VERSION "HNNBNNNYNNNNNNNNNNNNNNNNNNNNNNNNNNNNNNNNNN/4/%%%/4/'%**4NNN///"

NS_ :

BS_:

BU_: AWC BAP_Tester BMC_MLBevo BMS_MV BMS_NV CBC DCDC_800V_PAG DCDC_HV DCDC_HV_02 DCDC_IHEV FCU_MLBevo_FCEV Gateway Gateway_PAG Ladegeraet_2 Ladegeraet_Konzern LE1 LE2 LE_MLBevo Sub_Gateway TME

BO_ 64 Airbag_01: 8 Gateway
 SG_ Airbag_01_CRC : 0|8@1+ (1,0) [0|255] ""  BMC_MLBevo,BMS_MV,BMS_NV,CBC,DCDC_800V_PAG,DCDC_HV,DCDC_HV_02,DCDC_IHEV,FCU_MLBevo_FCEV,Ladegeraet_2,Ladegeraet_Konzern,Sub_Gateway
 SG_ Airbag_01_BZ : 8|4@1+ (1,0) [0|15] ""  BMC_MLBevo,BMS_MV,BMS_NV,CBC,DCDC_800V_PAG,DCDC_HV,DCDC_HV_02,DCDC_IHEV,FCU_MLBevo_FCEV,Ladegeraet_2,Ladegeraet_Konzern,Sub_Gateway
 SG_ AB_RGS_Anst : 12|4@1+ (1.0,0.0) [0.0|15] ""  FCU_MLBevo_FCEV,Sub_Gateway
 SG_ AB_Front_Crash : 16|1@1+ (1.0,0.0) [0.0|1] ""  FCU_MLBevo_FCEV,Sub_Gateway
 SG_ AB_Heck_Crash : 17|1@1+ (1.0,0.0) [0.0|1] ""  FCU_MLBevo_FCEV,Sub_Gateway
 SG_ AB_SF_Crash : 18|1@1+ (1.0,0.0) [0.0|1] ""  FCU_MLBevo_FCEV,Sub_Gateway
 SG_ AB_SB_Crash : 19|1@1+ (1.0,0.0) [0.0|1] ""  FCU_MLBevo_FCEV,Sub_Gateway
 SG_ AB_Rollover_Crash : 20|1@1+ (1.0,0.0) [0.0|1] ""  FCU_MLBevo_FCEV,Sub_Gateway
 SG_ AB_Crash_Int : 21|3@1+ (1.0,0.0) [0.0|7] ""  FCU_MLBevo_FCEV,Sub_Gateway,TME
 SG_ AB_Lampe : 24|1@1+ (1.0,0.0) [0.0|1] ""  FCU_MLBevo_FCEV,Sub_Gateway
 SG_ AB_Deaktiviert : 25|1@1+ (1.0,0.0) [0.0|1] ""  FCU_MLBevo_FCEV,Sub_Gateway
 SG_ AB_VB_deaktiviert : 26|1@1+ (1.0,0.0) [0.0|1] ""  FCU_MLBevo_FCEV,Sub_Gateway
 SG_ AB_Systemfehler : 27|1@1+ (1.0,0.0) [0.0|1] ""  FCU_MLBevo_FCEV,Sub_Gateway
 SG_ AB_Diagnose : 28|1@1+ (1.0,0.0) [0.0|1] ""  FCU_MLBevo_FCEV,Sub_Gateway
 SG_ AB_Stellgliedtest : 29|1@1+ (1.0,0.0) [0.0|1] ""  FCU_MLBevo_FCEV,Sub_Gateway,TME
 SG_ AB_Erh_Auf_VB : 30|2@1+ (1.0,0.0) [0.0|3] ""  FCU_MLBevo_FCEV,Sub_Gateway
 SG_ AB_Gurtwarn_VF : 32|1@1+ (1.0,0.0) [0.0|1] ""  FCU_MLBevo_FCEV,Sub_Gateway
 SG_ AB_Gurtwarn_VB : 33|1@1+ (1.0,0.0) [0.0|1] ""  FCU_MLBevo_FCEV,Sub_Gateway
 SG_ AB_Anzeige_Fussg : 34|2@1+ (1.0,0.0) [0.0|3] ""  FCU_MLBevo_FCEV,Sub_Gateway
 SG_ AB_Texte_AKS : 36|2@1+ (1.0,0.0) [0.0|3] ""  FCU_MLBevo_FCEV,Sub_Gateway
 SG_ AB_MKB_gueltig : 39|1@1+ (1.0,0.0) [0.0|1] ""  FCU_MLBevo_FCEV,Sub_Gateway
 SG_ AB_MKB_Anforderung : 40|1@1+ (1.0,0.0) [0.0|1] ""  FCU_MLBevo_FCEV,Sub_Gateway
 SG_ AB_Versorgungsspannung : 41|1@1+ (1.0,0.0) [0.0|1] ""  FCU_MLBevo_FCEV,Sub_Gateway
 SG_ AB_Deaktivierung_HV : 42|3@1+ (1.0,0.0) [0.0|7] ""  BMC_MLBevo,BMS_MV,BMS_NV,CBC,DCDC_800V_PAG,DCDC_HV,DCDC_HV_02,DCDC_IHEV,FCU_MLBevo_FCEV,Ladegeraet_2,Ladegeraet_Konzern,Sub_Gateway,TME
 SG_ AB_EDR_Trigger : 45|2@1+ (1.0,0.0) [0.0|3] ""  FCU_MLBevo_FCEV,Sub_Gateway
 SG_ AB_Belegung_VF : 47|2@1+ (1.0,0.0) [0.0|3] ""  FCU_MLBevo_FCEV,Sub_Gateway
 SG_ SC_Masterzeit_Offset : 53|2@1+ (5.08,0) [0.00|15.24] "Unit_Secon"  FCU_MLBevo_FCEV,Sub_Gateway
 SG_ SC_LowSpeedCrashErkannt : 55|2@1+ (1.0,0.0) [0.0|3] ""  FCU_MLBevo_FCEV,Sub_Gateway
 SG_ SC_Masterzeit : 57|7@1+ (0.04,0) [0.00|5.04] "Unit_Secon"  FCU_MLBevo_FCEV,Sub_Gateway

BO_ 2589283757 Authentic_Time_01: 8 Gateway
 SG_ AT_VALID_TIME : 32|32@1+ (1,0) [1|4294967295] ""  Ladegeraet_Konzern

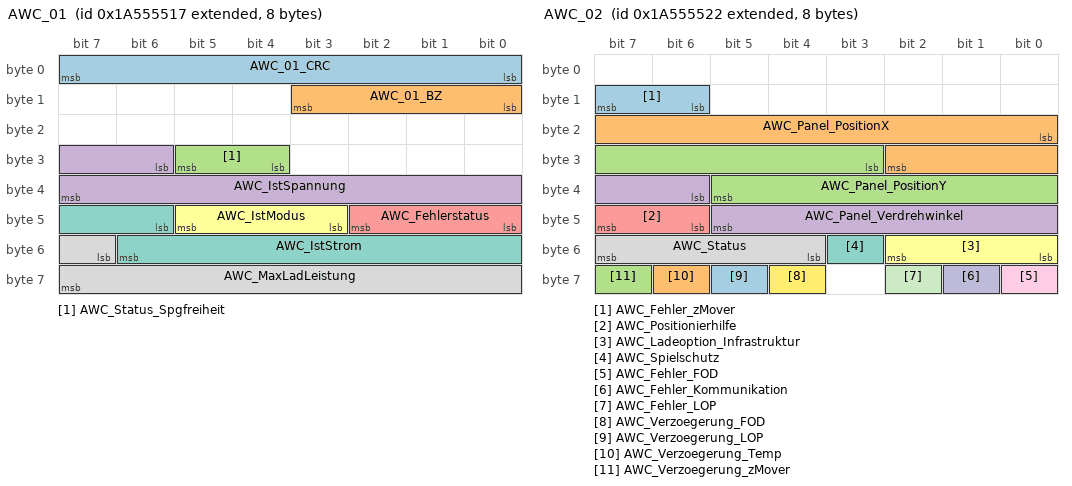
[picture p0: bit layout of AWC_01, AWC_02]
BO_ 2589283607 AWC_01: 8 AWC
 SG_ AWC_01_CRC : 0|8@1+ (1,0) [0|255] ""  Gateway
 SG_ AWC_01_BZ : 8|4@1+ (1,0) [0|15] ""  Gateway
 SG_ AWC_Status_Spgfreiheit : 28|2@1+ (1.0,0.0) [0.0|3] ""  Gateway
 SG_ AWC_IstSpannung : 30|10@1+ (1,0) [0|1021] "Unit_Volt"  Gateway
 SG_ AWC_Fehlerstatus : 40|3@1+ (1.0,0.0) [0.0|7] ""  Gateway
 SG_ AWC_IstModus : 43|3@1+ (1.0,0.0) [0.0|7] ""  Vector__XXX
 SG_ AWC_IstStrom : 46|9@1+ (0.1,0) [0.0|50.9] "Unit_Amper"  Vector__XXX
 SG_ AWC_MaxLadLeistung : 55|9@1+ (25,0) [0|12725] "Unit_Watt"  Vector__XXX

BO_ 2589283618 AWC_02: 8 AWC
 SG_ AWC_Fehler_zMover : 14|2@1+ (1.0,0.0) [0.0|3] ""  Gateway,Gateway_PAG
 SG_ AWC_Panel_PositionX : 16|11@1+ (1,-1000) [-1000|1000] "Unit_Centimeter"  Gateway,Gateway_PAG
 SG_ AWC_Panel_PositionY : 27|11@1+ (1,-1000) [-1000|1000] "Unit_Centimeter"  Gateway,Gateway_PAG
 SG_ AWC_Panel_Verdrehwinkel : 38|8@1+ (1.5,0) [0.0|360.0] "Unit_DegreOfArc"  Gateway,Gateway_PAG
 SG_ AWC_Positionierhilfe : 46|2@1+ (1.0,0.0) [0.0|3] ""  Gateway,Gateway_PAG
 SG_ AWC_Ladeoption_Infrastruktur : 48|3@1+ (1.0,0.0) [0.0|7] ""  Gateway,Gateway_PAG
 SG_ AWC_Spielschutz : 51|1@1+ (1.0,0.0) [0.0|1] ""  Gateway,Gateway_PAG
 SG_ AWC_Status : 52|4@1+ (1.0,0.0) [0.0|15] ""  Gateway,Gateway_PAG
 SG_ AWC_Fehler_FOD : 56|1@1+ (1.0,0.0) [0.0|1] ""  Gateway,Gateway_PAG
 SG_ AWC_Fehler_Kommunikation : 57|1@1+ (1.0,0.0) [0.0|1] ""  Gateway,Gateway_PAG
 SG_ AWC_Fehler_LOP : 58|1@1+ (1.0,0.0) [0.0|1] ""  Gateway,Gateway_PAG
 SG_ AWC_Verzoegerung_FOD : 60|1@1+ (1.0,0.0) [0.0|1] ""  Gateway,Gateway_PAG
 SG_ AWC_Verzoegerung_LOP : 61|1@1+ (1.0,0.0) [0.0|1] ""  Gateway,Gateway_PAG
 SG_ AWC_Verzoegerung_Temp : 62|1@1+ (1.0,0.0) [0.0|1] ""  Gateway,Gateway_PAG
 SG_ AWC_Verzoegerung_zMover : 63|1@1+ (1.0,0.0) [0.0|1] ""  Gateway,Gateway_PAG

BO_ 2536720384 BAP_AWC_ASG_01: 8 Gateway
 SG_ BAP_AWC_ASG_01_Header : 0|8@1+ (1,0) [0|255] "Unit_None"  Vector__XXX

BO_ 2536720385 BAP_AWC_ASG_02: 8 Gateway
 SG_ BAP_AWC_ASG_02_Header : 0|64@1+ (1.0,0.0) [0.0|18446744073709551615] ""  Vector__XXX

BO_ 2536720400 BAP_AWC_FSG_01: 8 AWC
 SG_ BAP_AWC_FSG_01_Header : 0|8@1+ (1,0) [0|255] "Unit_None"  Gateway,Gateway_PAG

BO_ 2536711424 BAP_BatteryControl_ASG_01: 8 Gateway
 SG_ BAP_BatteryControl_ASG_01_Header : 0|8@1+ (1.0,0.0) [0.0|255] ""  Ladegeraet_Konzern

BO_ 2536711425 BAP_BatteryControl_ASG_02: 8 Gateway
 SG_ BAP_BatteryControl_ASG_02_Header : 0|8@1+ (1.0,0.0) [0.0|255] ""  Ladegeraet_Konzern

BO_ 2536711426 BAP_BatteryControl_ASG_03: 8 Gateway
 SG_ BAP_BatteryControl_ASG_03_Header : 0|8@1+ (1.0,0.0) [0.0|255] ""  Ladegeraet_Konzern

BO_ 2536711427 BAP_BatteryControl_ASG_04: 8 Gateway
 SG_ BAP_BatteryControl_ASG_04_Header : 0|8@1+ (1.0,0.0) [0.0|255] ""  Ladegeraet_Konzern

BO_ 2536711429 BAP_BatteryControl_ASG_06: 8 Gateway
 SG_ BAP_BatteryControl_ASG_06_Header : 0|8@1+ (1.0,0.0) [0.0|255] ""  Ladegeraet_Konzern

BO_ 2536711440 BAP_BatteryControl_FSG_01: 8 Ladegeraet_Konzern
 SG_ BAP_BatteryControl_FSG_01_Header : 0|8@1+ (1.0,0.0) [0.0|255] ""  Gateway,Gateway_PAG

BO_ 2536767264 BAP_Debug_Cmd: 8 BAP_Tester
 SG_ BAP_Debug_Cmd : 0|16@1+ (1.0,0.0) [0.0|65535] ""  Gateway,Gateway_PAG,Ladegeraet_Konzern

BO_ 2536767280 BAP_Debug_Data: 8 Gateway
 SG_ BAP_Debug_Data : 0|64@1+ (1.0,0.0) [0.0|18446744073709551615] ""  BAP_Tester

BO_ 2536706306 BAP_Uhrzeit_ASG_03: 8 Ladegeraet_Konzern
 SG_ BAP_Uhrzeit_ASG_03_Header : 0|8@1+ (1.0,0.0) [0.0|255] ""  Gateway,Gateway_PAG

BO_ 2536706310 BAP_Uhrzeit_ASG_07: 8 AWC
 SG_ BAP_Uhrzeit_ASG_07_Header : 0|64@1+ (1.0,0.0) [0.0|18446744073709551615] ""  Gateway,Gateway_PAG

BO_ 2536706320 BAP_Uhrzeit_FSG_01: 8 Gateway
 SG_ BAP_Uhrzeit_FSG_01_Header : 0|8@1+ (1.0,0.0) [0.0|255] ""  Ladegeraet_Konzern

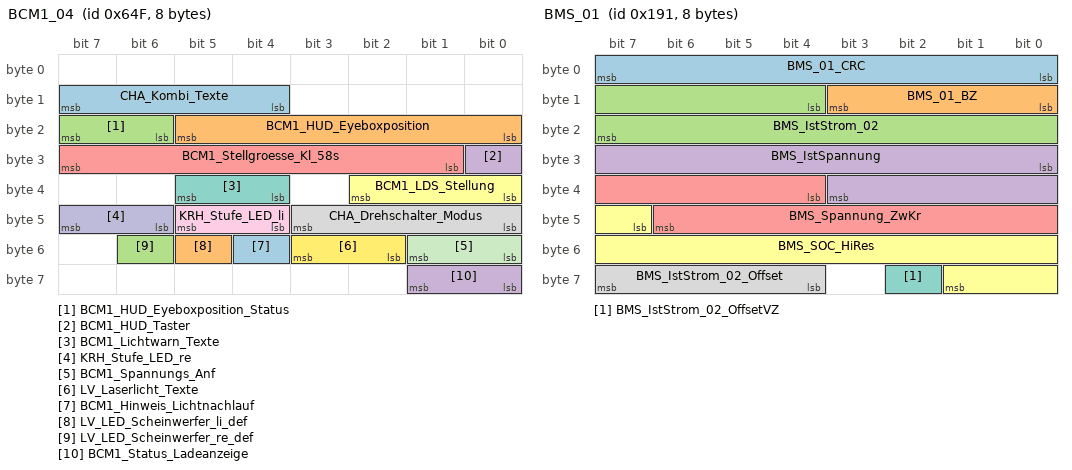
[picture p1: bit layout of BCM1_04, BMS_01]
BO_ 1615 BCM1_04: 8 Gateway
 SG_ CHA_Kombi_Texte : 12|4@1+ (1.0,0.0) [0.0|15] ""  Vector__XXX
 SG_ BCM1_HUD_Eyeboxposition : 16|6@1+ (1,0) [0|63] ""  Vector__XXX
 SG_ BCM1_HUD_Eyeboxposition_Status : 22|2@1+ (1.0,0.0) [0.0|3] ""  Vector__XXX
 SG_ BCM1_HUD_Taster : 24|1@1+ (1.0,0.0) [0.0|1] ""  Vector__XXX
 SG_ BCM1_Stellgroesse_Kl_58s : 25|7@1+ (1,0) [0|100] ""  Vector__XXX
 SG_ BCM1_LDS_Stellung : 32|3@1+ (1.0,0.0) [0.0|7] ""  Vector__XXX
 SG_ BCM1_Lichtwarn_Texte : 36|2@1+ (1.0,0.0) [0.0|3] ""  Vector__XXX
 SG_ CHA_Drehschalter_Modus : 40|4@1+ (1.0,0.0) [0.0|15] ""  Vector__XXX
 SG_ KRH_Stufe_LED_li : 44|2@1+ (1.0,0.0) [0.0|3] ""  Vector__XXX
 SG_ KRH_Stufe_LED_re : 46|2@1+ (1.0,0.0) [0.0|3] ""  Vector__XXX
 SG_ BCM1_Spannungs_Anf : 48|2@1+ (1.0,0.0) [0.0|3] ""  Vector__XXX
 SG_ LV_Laserlicht_Texte : 50|2@1+ (1.0,0.0) [0.0|3] ""  Vector__XXX
 SG_ BCM1_Hinweis_Lichtnachlauf : 52|1@1+ (1.0,0.0) [0.0|1] ""  Vector__XXX
 SG_ LV_LED_Scheinwerfer_li_def : 53|1@1+ (1.0,0.0) [0.0|1] ""  Vector__XXX
 SG_ LV_LED_Scheinwerfer_re_def : 54|1@1+ (1.0,0.0) [0.0|1] ""  Vector__XXX
 SG_ BCM1_Status_Ladeanzeige : 56|2@1+ (1.0,0.0) [0.0|3] ""  Ladegeraet_Konzern

BO_ 1626 BCM_01: 8 Gateway
 SG_ BCM_Bremsbelag_Sensor : 12|1@1+ (1.0,0.0) [0.0|1] ""  Vector__XXX
 SG_ BCM_Bremsfluessigkeit_Sensor : 13|1@1+ (1.0,0.0) [0.0|1] ""  Vector__XXX
 SG_ BCM1_Licht_Warn : 14|1@1+ (1.0,0.0) [0.0|1] ""  Vector__XXX
 SG_ BCM_Waschwasser_Sensor : 15|1@1+ (1.0,0.0) [0.0|1] ""  Vector__XXX
 SG_ BCM_Kuehlmittel_Sensor : 16|1@1+ (1.0,0.0) [0.0|1] ""  TME
 SG_ BCM1_Kl_15_HW_erkannt : 17|1@1+ (1.0,0.0) [0.0|1] ""  Vector__XXX
 SG_ BCM1_Kl_15_Sig_HW_erkannt : 18|1@1+ (1.0,0.0) [0.0|1] ""  Vector__XXX
 SG_ BCM_Kuehlmittel_Sensor_02 : 19|1@1+ (1.0,0.0) [0.0|1] ""  TME
 SG_ BCM1_Hinweis_Lichtnachlauf : 20|1@1+ (1.0,0.0) [0.0|1] ""  Vector__XXX
 SG_ BCM_Offroad_Taste : 21|1@1+ (1.0,0.0) [0.0|1] ""  Vector__XXX
 SG_ BCM_Hybrid_StSt_Taste_Fehler : 23|1@1+ (1.0,0.0) [0.0|1] ""  Vector__XXX
 SG_ BCM_Hybrid_StartStopp_Taste : 24|1@1+ (1.0,0.0) [0.0|1] ""  Vector__XXX
 SG_ BCM1_Warnblink_Taster : 25|1@1+ (1.0,0.0) [0.0|1] ""  Vector__XXX
 SG_ BCM1_Valet_Parking_Taster : 26|1@1+ (1.0,0.0) [0.0|1] ""  Vector__XXX
 SG_ BCM1_LDS_Stellung : 27|3@1+ (1.0,0.0) [0.0|7] ""  Vector__XXX
 SG_ BCM1_Rueckfahrlicht_Schalter : 30|1@1+ (1.0,0.0) [0.0|1] ""  Vector__XXX
 SG_ BCM1_MH_Schalter : 31|1@1+ (1.0,0.0) [0.0|1] ""  Vector__XXX
 SG_ BCM1_MH_WIV_Schalter : 32|1@1+ (1.0,0.0) [0.0|1] ""  Vector__XXX
 SG_ BCM_Eco_Charisma_Taste : 33|1@1+ (1.0,0.0) [0.0|1] ""  Vector__XXX
 SG_ BCM1_NV_Taster : 34|1@1+ (1.0,0.0) [0.0|1] ""  Vector__XXX
 SG_ BCM1_AFS_Lampe : 35|1@1+ (1.0,0.0) [0.0|1] ""  Vector__XXX
 SG_ BCM1_Reisemodus_Texte : 36|2@1+ (1.0,0.0) [0.0|3] ""  Vector__XXX
 SG_ BCM1_Lichtwarn_Texte : 38|2@1+ (1.0,0.0) [0.0|3] ""  Vector__XXX
 SG_ Gong_TFL_Umschaltung : 40|1@1+ (1.0,0.0) [0.0|1] ""  Vector__XXX
 SG_ UGDO_Function_01 : 41|3@1+ (1.0,0.0) [0.0|7] ""  Vector__XXX
 SG_ APS_Tongeber_defekt : 44|1@1+ (1.0,0.0) [0.0|1] ""  Vector__XXX
 SG_ BCM1_EasyEntry_Status : 45|1@1+ (1.0,0.0) [0.0|1] ""  Vector__XXX
 SG_ BCM1_Lenksaeule_aktiv : 46|1@1+ (1.0,0.0) [0.0|1] ""  Vector__XXX
 SG_ BCM1_St_SW_Diebstahl_links : 47|1@1+ (1.0,0.0) [0.0|1] ""  Vector__XXX
 SG_ BCM1_St_SW_Diebstahl_rechts : 48|1@1+ (1.0,0.0) [0.0|1] ""  Vector__XXX
 SG_ ISP_Dimmung_ASP_02 : 49|6@1+ (0.0226,0) [0.0000|1.4012] "Unit_Volt"  Vector__XXX
 SG_ BCM1_Schluesselsuche_Anf : 55|1@1+ (1.0,0.0) [0.0|1] ""  Vector__XXX
 SG_ BCM1_Fahrlicht_Hinweis : 62|1@1+ (1.0,0.0) [0.0|1] ""  Vector__XXX
 SG_ BCM_HDF_betaetigt : 63|1@1+ (1.0,0.0) [0.0|1] ""  Vector__XXX

BO_ 401 BMS_01: 8 BMC_MLBevo
 SG_ BMS_01_CRC : 0|8@1+ (1,0) [0|255] ""  Gateway,Gateway_PAG,LE1,Sub_Gateway
 SG_ BMS_01_BZ : 8|4@1+ (1,0) [0|15] ""  Gateway,Gateway_PAG,LE1,Sub_Gateway
 SG_ BMS_IstStrom_02 : 12|12@1+ (1,-2047) [-2047|2046] "Unit_Amper"  Gateway,Gateway_PAG,Ladegeraet_Konzern,LE1,LE2,Sub_Gateway,TME
 SG_ BMS_IstSpannung : 24|12@1+ (0.25,0) [0.00|1023.25] "Unit_Volt"  DCDC_HV,Gateway,Gateway_PAG,Ladegeraet_2,Ladegeraet_Konzern,LE1,LE2,Sub_Gateway,TME
 SG_ BMS_Spannung_ZwKr : 36|11@1+ (0.5,0) [0.0|1022.5] "Unit_Volt"  Gateway,Gateway_PAG,LE1,LE2,Sub_Gateway,TME
 SG_ BMS_SOC_HiRes : 47|11@1+ (0.05,0) [0.00|100.00] "Unit_PerCent"  Gateway,Gateway_PAG,Ladegeraet_Konzern,Sub_Gateway,TME
 SG_ BMS_IstStrom_02_OffsetVZ : 58|1@1+ (1.0,0.0) [0.0|1] ""  Gateway,Gateway_PAG,Ladegeraet_Konzern,Sub_Gateway
 SG_ BMS_IstStrom_02_Offset : 60|4@1+ (0.0625,0) [0.0000|0.9375] "Unit_Amper"  Gateway,Gateway_PAG,Ladegeraet_Konzern,Sub_Gateway

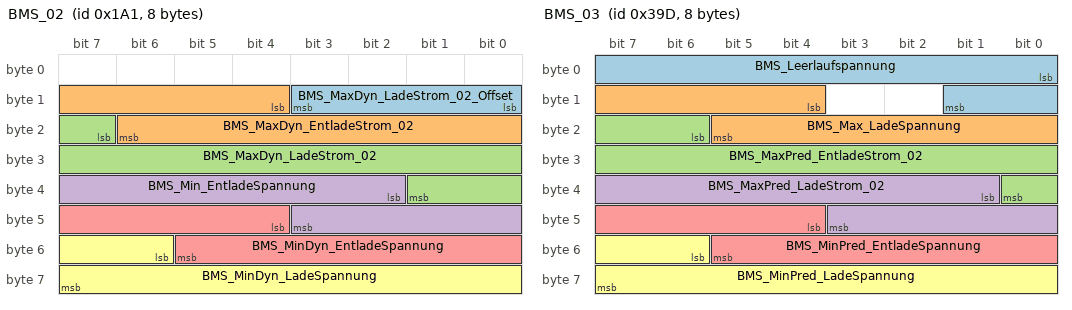
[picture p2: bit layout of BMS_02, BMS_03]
BO_ 417 BMS_02: 8 BMC_MLBevo
 SG_ BMS_MaxDyn_LadeStrom_02_Offset : 8|4@1+ (0.0625,0) [0.0000|0.9375] "Unit_Amper"  FCU_MLBevo_FCEV,Gateway,Gateway_PAG,Ladegeraet_Konzern
 SG_ BMS_MaxDyn_EntladeStrom_02 : 12|11@1+ (1,0) [0|2045] "Unit_Amper"  FCU_MLBevo_FCEV,Gateway,Gateway_PAG
 SG_ BMS_MaxDyn_LadeStrom_02 : 23|11@1+ (1,0) [0|2045] "Unit_Amper"  FCU_MLBevo_FCEV,Gateway,Gateway_PAG,Ladegeraet_Konzern
 SG_ BMS_Min_EntladeSpannung : 34|10@1+ (1,0) [0|1021] "Unit_Volt"  FCU_MLBevo_FCEV,Gateway,Gateway_PAG,Ladegeraet_Konzern
 SG_ BMS_MinDyn_EntladeSpannung : 44|10@1+ (1,0) [0|1022] "Unit_Volt"  FCU_MLBevo_FCEV,Gateway,Gateway_PAG
 SG_ BMS_MinDyn_LadeSpannung : 54|10@1+ (1,0) [0|1022] "Unit_Volt"  FCU_MLBevo_FCEV,Gateway,Gateway_PAG

BO_ 925 BMS_03: 8 BMC_MLBevo
 SG_ BMS_Leerlaufspannung : 0|10@1+ (1,0) [0|1022] "Unit_Volt"  FCU_MLBevo_FCEV,Gateway,Gateway_PAG
 SG_ BMS_Max_LadeSpannung : 12|10@1+ (1,0) [0|1021] "Unit_Volt"  FCU_MLBevo_FCEV,Gateway,Gateway_PAG,Ladegeraet_2,Ladegeraet_Konzern
 SG_ BMS_MaxPred_EntladeStrom_02 : 22|11@1+ (1,0) [0|2045] "Unit_Amper"  FCU_MLBevo_FCEV,Gateway,Gateway_PAG
 SG_ BMS_MaxPred_LadeStrom_02 : 33|11@1+ (1,0) [0|2045] "Unit_Amper"  FCU_MLBevo_FCEV,Gateway,Gateway_PAG,Ladegeraet_Konzern
 SG_ BMS_MinPred_EntladeSpannung : 44|10@1+ (1,0) [0|1022] "Unit_Volt"  FCU_MLBevo_FCEV,Gateway,Gateway_PAG,Ladegeraet_Konzern
 SG_ BMS_MinPred_LadeSpannung : 54|10@1+ (1,0) [0|1022] "Unit_Volt"  FCU_MLBevo_FCEV,Gateway,Gateway_PAG

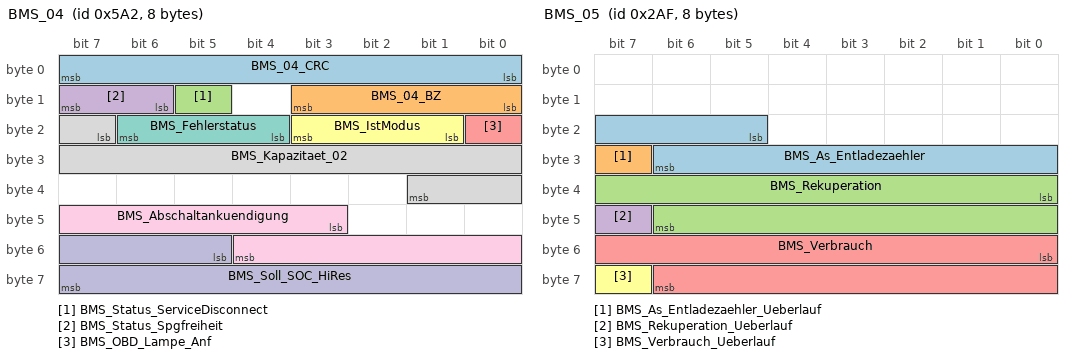
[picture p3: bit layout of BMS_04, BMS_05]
BO_ 1442 BMS_04: 8 BMC_MLBevo
 SG_ BMS_04_CRC : 0|8@1+ (1,0) [0|255] ""  CBC,FCU_MLBevo_FCEV,Gateway,Gateway_PAG,LE1,Sub_Gateway
 SG_ BMS_04_BZ : 8|4@1+ (1,0) [0|15] ""  CBC,FCU_MLBevo_FCEV,Gateway,Gateway_PAG,LE1,Sub_Gateway
 SG_ BMS_Status_ServiceDisconnect : 13|1@1+ (1.0,0.0) [0.0|1] ""  CBC,DCDC_800V_PAG,DCDC_HV,FCU_MLBevo_FCEV,Gateway,Gateway_PAG,Sub_Gateway
 SG_ BMS_Status_Spgfreiheit : 14|2@1+ (1.0,0.0) [0.0|3] ""  FCU_MLBevo_FCEV,Gateway,Gateway_PAG,Sub_Gateway
 SG_ BMS_OBD_Lampe_Anf : 16|1@1+ (1.0,0.0) [0.0|1] ""  FCU_MLBevo_FCEV,Gateway,Gateway_PAG,Sub_Gateway
 SG_ BMS_IstModus : 17|3@1+ (1.0,0.0) [0.0|7] ""  DCDC_HV,FCU_MLBevo_FCEV,Gateway,Gateway_PAG,Ladegeraet_Konzern,LE1,LE2,Sub_Gateway,TME
 SG_ BMS_Fehlerstatus : 20|3@1+ (1.0,0.0) [0.0|7] ""  CBC,DCDC_800V_PAG,DCDC_HV,FCU_MLBevo_FCEV,Gateway,Gateway_PAG,Ladegeraet_Konzern,Sub_Gateway
 SG_ BMS_Kapazitaet_02 : 23|11@1+ (0.2,0) [0.0|409.2] "Unit_AmperHour"  FCU_MLBevo_FCEV,Gateway,Gateway_PAG,Ladegeraet_Konzern,Sub_Gateway
 SG_ BMS_Abschaltankuendigung : 43|10@1+ (0.5,0) [0.0|510.5] "Unit_Secon"  FCU_MLBevo_FCEV,Gateway,Gateway_PAG,Sub_Gateway
 SG_ BMS_Soll_SOC_HiRes : 53|11@1+ (0.05,0) [0.00|100.00] "Unit_PerCent"  FCU_MLBevo_FCEV,Gateway,Gateway_PAG,Sub_Gateway

BO_ 687 BMS_05: 8 BMC_MLBevo
 SG_ BMS_As_Entladezaehler : 21|10@1+ (1,0) [0|1023] "Unit_AmperSecon"  Gateway,Gateway_PAG
 SG_ BMS_As_Entladezaehler_Ueberlauf : 31|1@1+ (1.0,0.0) [0.0|1] ""  Gateway,Gateway_PAG
 SG_ BMS_Rekuperation : 32|15@1+ (10,0) [0|327670] "Unit_WattSecond"  Gateway,Gateway_PAG
 SG_ BMS_Rekuperation_Ueberlauf : 47|1@1+ (1.0,0.0) [0.0|1] ""  Gateway,Gateway_PAG
 SG_ BMS_Verbrauch : 48|15@1+ (10,0) [0|327670] "Unit_WattSecond"  Gateway,Gateway_PAG
 SG_ BMS_Verbrauch_Ueberlauf : 63|1@1+ (1.0,0.0) [0.0|1] ""  Gateway,Gateway_PAG

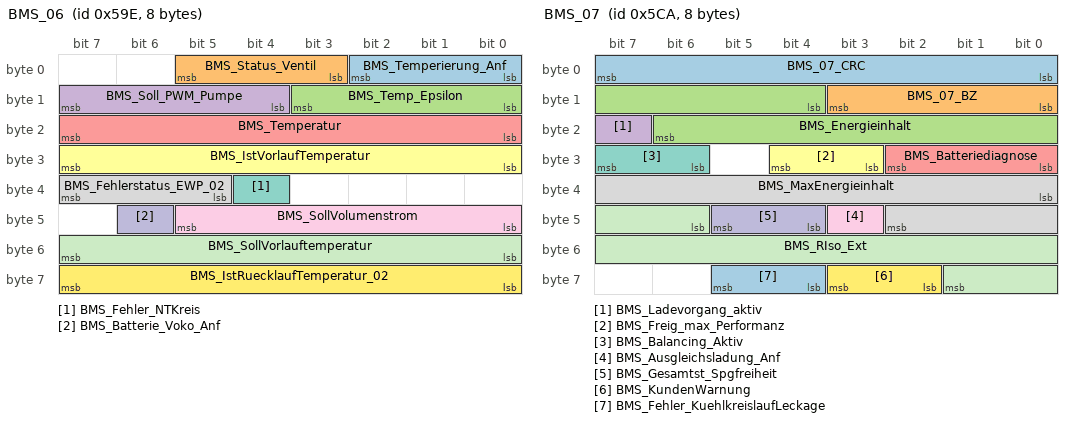
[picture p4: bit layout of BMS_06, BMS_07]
BO_ 1438 BMS_06: 8 BMC_MLBevo
 SG_ BMS_Temperierung_Anf : 0|3@1+ (1.0,0.0) [0.0|7] ""  Gateway,Gateway_PAG,TME
 SG_ BMS_Status_Ventil : 3|3@1+ (1.0,0.0) [0.0|7] ""  Gateway,Gateway_PAG
 SG_ BMS_Temp_Epsilon : 8|4@1+ (1,-15) [-15|0] "Unit_DegreCelsi"  Gateway,Gateway_PAG,TME
 SG_ BMS_Soll_PWM_Pumpe : 12|4@1+ (10,0) [0|100] "Unit_PerCent"  Gateway,Gateway_PAG,TME
 SG_ BMS_Temperatur : 16|8@1+ (0.5,-40) [-40.0|86.5] "Unit_DegreCelsi"  Gateway,Gateway_PAG,Ladegeraet_Konzern,TME
 SG_ BMS_IstVorlaufTemperatur : 24|8@1+ (0.5,-40) [-40.0|86.5] "Unit_DegreCelsi"  Gateway,Gateway_PAG,TME
 SG_ BMS_Fehler_NTKreis : 36|1@1+ (1.0,0.0) [0.0|1] ""  Gateway,Gateway_PAG
 SG_ BMS_Fehlerstatus_EWP_02 : 37|3@1+ (1.0,0.0) [0.0|7] ""  Gateway,Gateway_PAG,TME
 SG_ BMS_SollVolumenstrom : 40|6@1+ (1,0) [0|61] "Unit_LiterPerMinut"  Gateway,Gateway_PAG,TME
 SG_ BMS_Batterie_Voko_Anf : 46|1@1+ (1.0,0.0) [0.0|1] ""  Gateway,Gateway_PAG,Ladegeraet_Konzern,TME
 SG_ BMS_SollVorlauftemperatur : 48|8@1+ (0.5,-40) [-40.0|86.5] "Unit_DegreCelsi"  Gateway,Gateway_PAG,TME
 SG_ BMS_IstRuecklaufTemperatur_02 : 56|8@1+ (0.5,-40) [-40.0|86.5] "Unit_DegreCelsi"  Gateway,Gateway_PAG,TME

BO_ 1482 BMS_07: 8 BMC_MLBevo
 SG_ BMS_07_CRC : 0|8@1+ (1,0) [0|255] ""  Gateway,Gateway_PAG,Sub_Gateway
 SG_ BMS_07_BZ : 8|4@1+ (1,0) [0|15] ""  Gateway,Gateway_PAG,Sub_Gateway
 SG_ BMS_Energieinhalt : 12|11@1+ (50,0) [0|102250] "Unit_WattHour"  Gateway,Gateway_PAG,Ladegeraet_Konzern,Sub_Gateway,TME
 SG_ BMS_Ladevorgang_aktiv : 23|1@1+ (1.0,0.0) [0.0|1] ""  Gateway,Gateway_PAG,Sub_Gateway
 SG_ BMS_Batteriediagnose : 24|3@1+ (1.0,0.0) [0.0|7] ""  Gateway,Gateway_PAG,Sub_Gateway
 SG_ BMS_Freig_max_Performanz : 27|2@1+ (1.0,0.0) [0.0|3] ""  Gateway,Gateway_PAG,Sub_Gateway
 SG_ BMS_Balancing_Aktiv : 30|2@1+ (1.0,0.0) [0.0|3] ""  Gateway,Gateway_PAG,Sub_Gateway
 SG_ BMS_MaxEnergieinhalt : 32|11@1+ (50,0) [0|102250] "Unit_WattHour"  Gateway,Gateway_PAG,Ladegeraet_Konzern,Sub_Gateway,TME
 SG_ BMS_Ausgleichsladung_Anf : 43|1@1+ (1.0,0.0) [0.0|1] ""  Gateway,Gateway_PAG,Sub_Gateway
 SG_ BMS_Gesamtst_Spgfreiheit : 44|2@1+ (1.0,0.0) [0.0|3] ""  Gateway,Gateway_PAG,Sub_Gateway
 SG_ BMS_RIso_Ext : 46|12@1+ (5,0) [0|20465] "Unit_KiloOhm"  Gateway,Gateway_PAG,Sub_Gateway
 SG_ BMS_KundenWarnung : 58|2@1+ (1.0,0.0) [0.0|3] ""  Gateway,Gateway_PAG,Sub_Gateway
 SG_ BMS_Fehler_KuehlkreislaufLeckage : 60|2@1+ (1.0,0.0) [0.0|3] ""  Gateway,Gateway_PAG,Sub_Gateway,TME

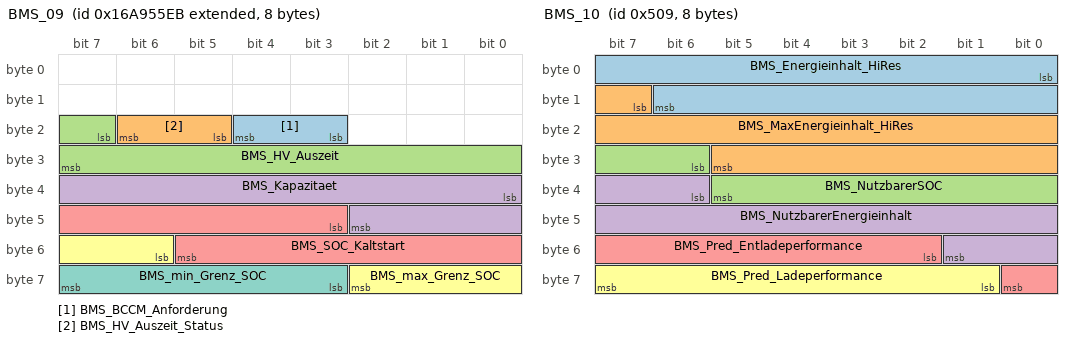
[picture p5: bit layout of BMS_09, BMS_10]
BO_ 2527679979 BMS_09: 8 BMC_MLBevo
 SG_ BMS_BCCM_Anforderung : 19|2@1+ (1.0,0.0) [0.0|3] ""  Gateway,Gateway_PAG,Ladegeraet_Konzern
 SG_ BMS_HV_Auszeit_Status : 21|2@1+ (1.0,0.0) [0.0|3] ""  CBC,DCDC_800V_PAG,DCDC_HV,Gateway,Gateway_PAG,Ladegeraet_2,Ladegeraet_Konzern,TME
 SG_ BMS_HV_Auszeit : 23|9@1+ (4,0) [0|2036] "Unit_Minut"  CBC,DCDC_800V_PAG,DCDC_HV,Gateway,Gateway_PAG,Ladegeraet_2,Ladegeraet_Konzern,TME
 SG_ BMS_Kapazitaet : 32|11@1+ (0.1,0) [0.0|204.6] "Unit_AmperHour"  Gateway,Gateway_PAG,Ladegeraet_Konzern
 SG_ BMS_SOC_Kaltstart : 43|11@1+ (0.05,0) [0.00|100.00] "Unit_PerCent"  Gateway,Gateway_PAG
 SG_ BMS_max_Grenz_SOC : 54|5@1+ (1,70) [70|100] "Unit_PerCent"  Gateway,Gateway_PAG,Ladegeraet_Konzern
 SG_ BMS_min_Grenz_SOC : 59|5@1+ (1,0) [0|30] "Unit_PerCent"  Gateway,Gateway_PAG,Ladegeraet_Konzern

BO_ 1289 BMS_10: 8 BMC_MLBevo
 SG_ BMS_Energieinhalt_HiRes : 0|15@1+ (4,0) [0|131060] "Unit_WattHour"  Gateway,Gateway_PAG,Ladegeraet_Konzern,Sub_Gateway
 SG_ BMS_MaxEnergieinhalt_HiRes : 15|15@1+ (4,0) [0|131060] "Unit_WattHour"  Gateway,Gateway_PAG,Ladegeraet_Konzern,Sub_Gateway
 SG_ BMS_NutzbarerSOC : 30|8@1+ (0.5,0) [0.0|100.0] "Unit_PerCent"  Gateway,Gateway_PAG,Ladegeraet_Konzern,Sub_Gateway,TME
 SG_ BMS_NutzbarerEnergieinhalt : 38|12@1+ (25,0) [0|102325] "Unit_WattHour"  Gateway,Gateway_PAG,Sub_Gateway
 SG_ BMS_Pred_Entladeperformance : 50|7@1+ (1,0) [0|100] "Unit_PerCent"  Gateway,Gateway_PAG,Sub_Gateway
 SG_ BMS_Pred_Ladeperformance : 57|7@1+ (1,0) [0|100] "Unit_PerCent"  Gateway,Gateway_PAG,Sub_Gateway

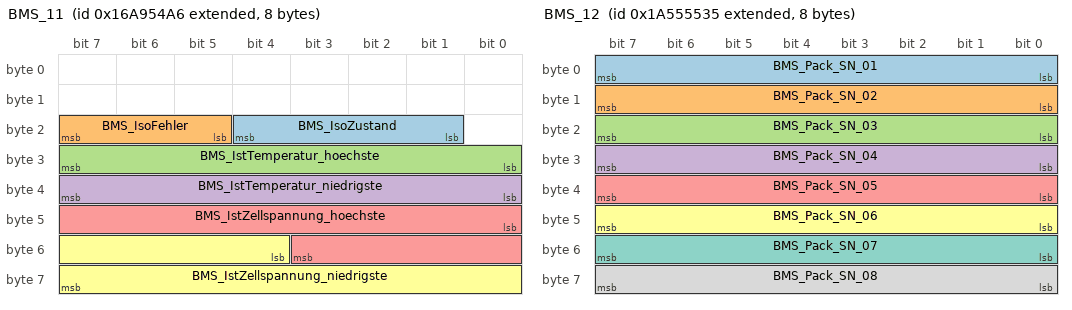
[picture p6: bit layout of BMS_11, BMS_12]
BO_ 2527679654 BMS_11: 8 BMC_MLBevo
 SG_ BMS_IsoZustand : 17|4@1+ (1.0,0.0) [0.0|15] ""  Gateway,Gateway_PAG,Sub_Gateway
 SG_ BMS_IsoFehler : 21|3@1+ (1.0,0.0) [0.0|7] ""  Gateway,Gateway_PAG,Ladegeraet_Konzern,Sub_Gateway
 SG_ BMS_IstTemperatur_hoechste : 24|8@1+ (0.5,-40) [-40.0|86.0] "Unit_DegreCelsi"  Gateway,Gateway_PAG,Ladegeraet_Konzern,Sub_Gateway,TME
 SG_ BMS_IstTemperatur_niedrigste : 32|8@1+ (0.5,-40) [-40.0|86.0] "Unit_DegreCelsi"  Gateway,Gateway_PAG,Ladegeraet_Konzern,Sub_Gateway,TME
 SG_ BMS_IstZellspannung_hoechste : 40|12@1+ (1,1000) [1000|5091] "Unit_MilliVolt"  Gateway,Gateway_PAG,Ladegeraet_Konzern,Sub_Gateway
 SG_ BMS_IstZellspannung_niedrigste : 52|12@1+ (1,1000) [1000|5091] "Unit_MilliVolt"  Gateway,Gateway_PAG,Ladegeraet_Konzern,Sub_Gateway

BO_ 2589283637 BMS_12: 8 BMC_MLBevo
 SG_ BMS_Pack_SN_01 : 0|8@1+ (1.0,0.0) [0.0|255] ""  Gateway,Gateway_PAG,Sub_Gateway
 SG_ BMS_Pack_SN_02 : 8|8@1+ (1.0,0.0) [0.0|255] ""  Gateway,Gateway_PAG,Sub_Gateway
 SG_ BMS_Pack_SN_03 : 16|8@1+ (1.0,0.0) [0.0|255] ""  Gateway,Gateway_PAG,Sub_Gateway
 SG_ BMS_Pack_SN_04 : 24|8@1+ (1.0,0.0) [0.0|255] ""  Gateway,Gateway_PAG,Sub_Gateway
 SG_ BMS_Pack_SN_05 : 32|8@1+ (1.0,0.0) [0.0|255] ""  Gateway,Gateway_PAG,Sub_Gateway
 SG_ BMS_Pack_SN_06 : 40|8@1+ (1.0,0.0) [0.0|255] ""  Gateway,Gateway_PAG,Sub_Gateway
 SG_ BMS_Pack_SN_07 : 48|8@1+ (1.0,0.0) [0.0|255] ""  Gateway,Gateway_PAG,Sub_Gateway
 SG_ BMS_Pack_SN_08 : 56|8@1+ (1.0,0.0) [0.0|255] ""  Gateway,Gateway_PAG,Sub_Gateway

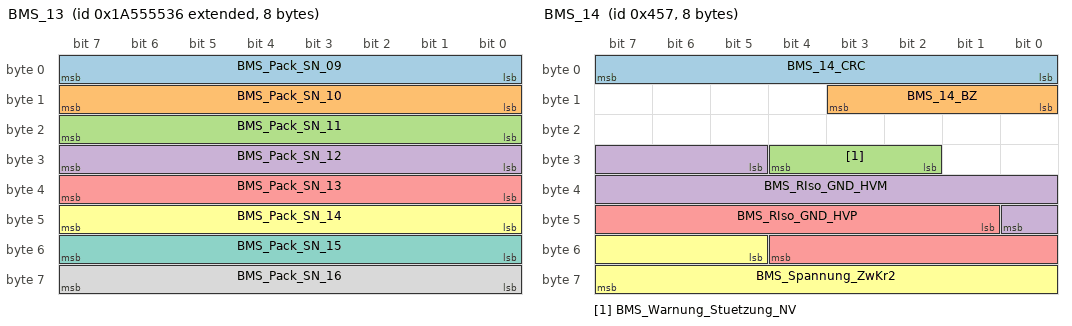
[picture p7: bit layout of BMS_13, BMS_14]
BO_ 2589283638 BMS_13: 8 BMC_MLBevo
 SG_ BMS_Pack_SN_09 : 0|8@1+ (1.0,0.0) [0.0|255] ""  Gateway,Gateway_PAG,Sub_Gateway
 SG_ BMS_Pack_SN_10 : 8|8@1+ (1.0,0.0) [0.0|255] ""  Gateway,Gateway_PAG,Sub_Gateway
 SG_ BMS_Pack_SN_11 : 16|8@1+ (1.0,0.0) [0.0|255] ""  Gateway,Gateway_PAG,Sub_Gateway
 SG_ BMS_Pack_SN_12 : 24|8@1+ (1.0,0.0) [0.0|255] ""  Gateway,Gateway_PAG,Sub_Gateway
 SG_ BMS_Pack_SN_13 : 32|8@1+ (1.0,0.0) [0.0|255] ""  Gateway,Gateway_PAG,Sub_Gateway
 SG_ BMS_Pack_SN_14 : 40|8@1+ (1.0,0.0) [0.0|255] ""  Gateway,Gateway_PAG,Sub_Gateway
 SG_ BMS_Pack_SN_15 : 48|8@1+ (1.0,0.0) [0.0|255] ""  Gateway,Gateway_PAG,Sub_Gateway
 SG_ BMS_Pack_SN_16 : 56|8@1+ (1.0,0.0) [0.0|255] ""  Sub_Gateway

BO_ 1111 BMS_14: 8 BMC_MLBevo
 SG_ BMS_14_CRC : 0|8@1+ (1,0) [0|255] ""  Gateway,Gateway_PAG,LE2,Sub_Gateway
 SG_ BMS_14_BZ : 8|4@1+ (1,0) [0|15] ""  Gateway,Gateway_PAG,LE2,Sub_Gateway
 SG_ BMS_Warnung_Stuetzung_NV : 26|3@1+ (1.0,0.0) [0.0|7] ""  Gateway,Gateway_PAG,Sub_Gateway
 SG_ BMS_RIso_GND_HVM : 29|12@1+ (5,-20465) [-20465|0] "Unit_KiloOhm"  CBC,DCDC_HV_02,Gateway,Gateway_PAG,Sub_Gateway
 SG_ BMS_RIso_GND_HVP : 41|12@1+ (5,0) [0|20465] "Unit_KiloOhm"  CBC,DCDC_HV_02,Gateway,Gateway_PAG,Sub_Gateway
 SG_ BMS_Spannung_ZwKr2 : 53|11@1+ (0.5,0) [0.0|1022.5] "Unit_Volt"  Gateway,Gateway_PAG,LE2,Sub_Gateway,TME

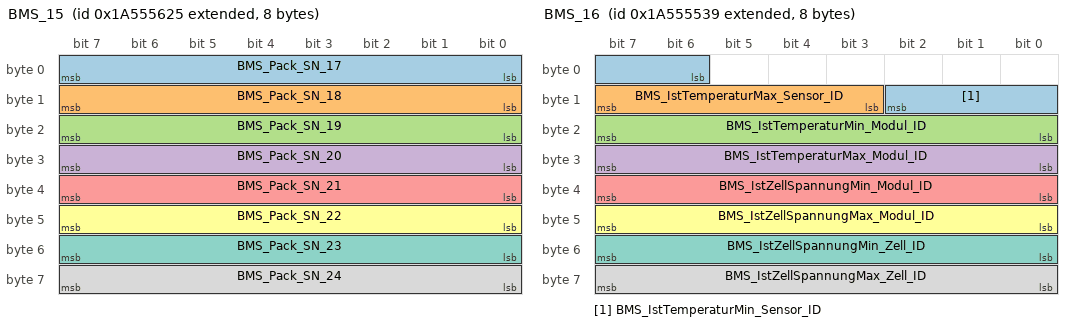
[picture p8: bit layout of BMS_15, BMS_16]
BO_ 2589283877 BMS_15: 8 BMC_MLBevo
 SG_ BMS_Pack_SN_17 : 0|8@1+ (1.0,0.0) [0.0|255] ""  Sub_Gateway
 SG_ BMS_Pack_SN_18 : 8|8@1+ (1.0,0.0) [0.0|255] ""  Sub_Gateway
 SG_ BMS_Pack_SN_19 : 16|8@1+ (1.0,0.0) [0.0|255] ""  Sub_Gateway
 SG_ BMS_Pack_SN_20 : 24|8@1+ (1.0,0.0) [0.0|255] ""  Sub_Gateway
 SG_ BMS_Pack_SN_21 : 32|8@1+ (1.0,0.0) [0.0|255] ""  Sub_Gateway
 SG_ BMS_Pack_SN_22 : 40|8@1+ (1.0,0.0) [0.0|255] ""  Sub_Gateway
 SG_ BMS_Pack_SN_23 : 48|8@1+ (1.0,0.0) [0.0|255] ""  Sub_Gateway
 SG_ BMS_Pack_SN_24 : 56|8@1+ (1.0,0.0) [0.0|255] ""  Sub_Gateway

BO_ 2589283641 BMS_16: 8 BMC_MLBevo
 SG_ BMS_IstTemperaturMin_Sensor_ID : 6|5@1+ (1,0) [1|30] ""  Gateway,Gateway_PAG,Ladegeraet_Konzern,Sub_Gateway
 SG_ BMS_IstTemperaturMax_Sensor_ID : 11|5@1+ (1,0) [1|30] ""  Gateway,Gateway_PAG,Ladegeraet_Konzern,Sub_Gateway
 SG_ BMS_IstTemperaturMin_Modul_ID : 16|8@1+ (1,0) [1|254] ""  Gateway,Gateway_PAG,Ladegeraet_Konzern,Sub_Gateway
 SG_ BMS_IstTemperaturMax_Modul_ID : 24|8@1+ (1,0) [1|254] ""  Gateway,Gateway_PAG,Ladegeraet_Konzern,Sub_Gateway
 SG_ BMS_IstZellSpannungMin_Modul_ID : 32|8@1+ (1,0) [1|254] ""  Gateway,Gateway_PAG,Ladegeraet_Konzern,Sub_Gateway
 SG_ BMS_IstZellSpannungMax_Modul_ID : 40|8@1+ (1,0) [1|254] ""  Gateway,Gateway_PAG,Ladegeraet_Konzern,Sub_Gateway
 SG_ BMS_IstZellSpannungMin_Zell_ID : 48|8@1+ (1,0) [1|254] ""  Gateway,Gateway_PAG,Ladegeraet_Konzern,Sub_Gateway
 SG_ BMS_IstZellSpannungMax_Zell_ID : 56|8@1+ (1,0) [1|254] ""  Gateway,Gateway_PAG,Ladegeraet_Konzern,Sub_Gateway

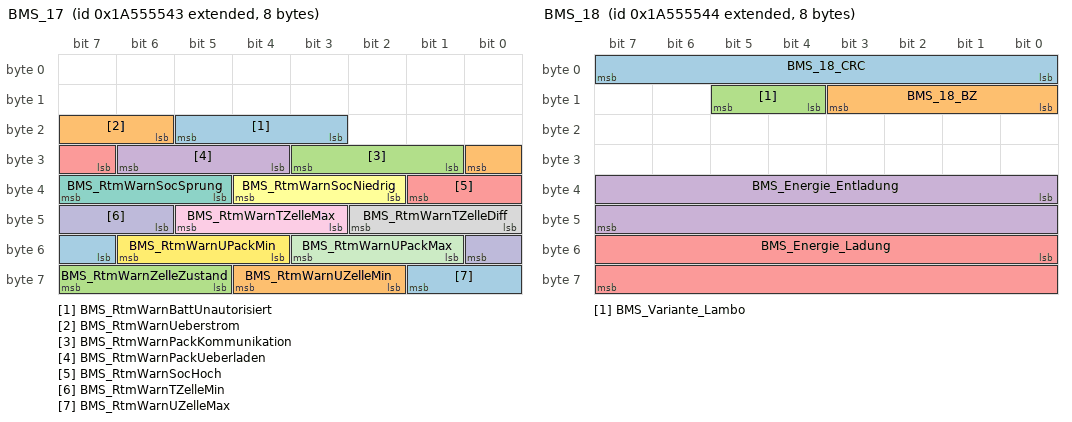
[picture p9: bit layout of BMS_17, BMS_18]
BO_ 2589283651 BMS_17: 8 BMC_MLBevo
 SG_ BMS_RtmWarnBattUnautorisiert : 19|3@1+ (1.0,0.0) [0.0|7] ""  Sub_Gateway
 SG_ BMS_RtmWarnUeberstrom : 22|3@1+ (1.0,0.0) [0.0|7] ""  Gateway,Gateway_PAG,Sub_Gateway
 SG_ BMS_RtmWarnPackKommunikation : 25|3@1+ (1.0,0.0) [0.0|7] ""  Gateway,Gateway_PAG,Sub_Gateway
 SG_ BMS_RtmWarnPackUeberladen : 28|3@1+ (1.0,0.0) [0.0|7] ""  Gateway,Gateway_PAG,Sub_Gateway
 SG_ BMS_RtmWarnSocHoch : 31|3@1+ (1.0,0.0) [0.0|7] ""  Gateway,Gateway_PAG,Sub_Gateway
 SG_ BMS_RtmWarnSocNiedrig : 34|3@1+ (1.0,0.0) [0.0|7] ""  Gateway,Gateway_PAG,Sub_Gateway
 SG_ BMS_RtmWarnSocSprung : 37|3@1+ (1.0,0.0) [0.0|7] ""  Gateway,Gateway_PAG,Sub_Gateway
 SG_ BMS_RtmWarnTZelleDiff : 40|3@1+ (1.0,0.0) [0.0|7] ""  Gateway,Gateway_PAG,Sub_Gateway
 SG_ BMS_RtmWarnTZelleMax : 43|3@1+ (1.0,0.0) [0.0|7] ""  Gateway,Gateway_PAG,Sub_Gateway
 SG_ BMS_RtmWarnTZelleMin : 46|3@1+ (1.0,0.0) [0.0|7] ""  Gateway,Gateway_PAG,Sub_Gateway
 SG_ BMS_RtmWarnUPackMax : 49|3@1+ (1.0,0.0) [0.0|7] ""  Gateway,Gateway_PAG,Sub_Gateway
 SG_ BMS_RtmWarnUPackMin : 52|3@1+ (1.0,0.0) [0.0|7] ""  Gateway,Gateway_PAG,Sub_Gateway
 SG_ BMS_RtmWarnUZelleMax : 55|3@1+ (1.0,0.0) [0.0|7] ""  Gateway,Gateway_PAG,Sub_Gateway
 SG_ BMS_RtmWarnUZelleMin : 58|3@1+ (1.0,0.0) [0.0|7] ""  Gateway,Gateway_PAG,Sub_Gateway
 SG_ BMS_RtmWarnZelleZustand : 61|3@1+ (1.0,0.0) [0.0|7] ""  Gateway,Gateway_PAG,Sub_Gateway

BO_ 2589283652 BMS_18: 8 BMC_MLBevo
 SG_ BMS_18_CRC : 0|8@1+ (1,0) [0|255] ""  Gateway,Gateway_PAG,Sub_Gateway
 SG_ BMS_18_BZ : 8|4@1+ (1,0) [0|15] ""  Gateway,Gateway_PAG,Sub_Gateway
 SG_ BMS_Variante_Lambo : 12|2@1+ (1.0,0.0) [0.0|3] ""  Gateway,Gateway_PAG,Sub_Gateway
 SG_ BMS_Energie_Entladung : 32|16@1+ (0.01,0) [0.00|655.33] "Unit_KiloWattHour"  Gateway,Gateway_PAG,Sub_Gateway
 SG_ BMS_Energie_Ladung : 48|16@1+ (0.01,0) [0.00|655.33] "Unit_KiloWattHour"  Gateway,Gateway_PAG,Sub_Gateway

BO_ 2589283878 BMS_19: 8 BMC_MLBevo
 SG_ BMS_Pack_SN_25 : 0|8@1+ (1.0,0.0) [0.0|255] ""  Sub_Gateway
 SG_ BMS_Pack_SN_26 : 8|8@1+ (1.0,0.0) [0.0|255] ""  Sub_Gateway

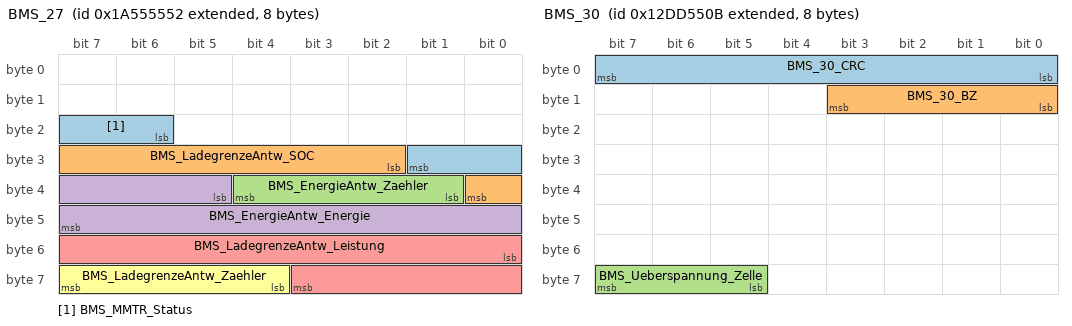
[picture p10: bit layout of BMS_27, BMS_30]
BO_ 2589283666 BMS_27: 8 BMC_MLBevo
 SG_ BMS_MMTR_Status : 22|4@1+ (1.0,0.0) [0.0|15] ""  Gateway_PAG
 SG_ BMS_LadegrenzeAntw_SOC : 26|7@1+ (1,0) [0|100] "Unit_PerCent"  Gateway_PAG,Ladegeraet_Konzern
 SG_ BMS_EnergieAntw_Zaehler : 33|4@1+ (1,0) [0|13] "Unit_None"  Gateway_PAG,Ladegeraet_Konzern
 SG_ BMS_EnergieAntw_Energie : 37|11@1+ (250,0) [0|511250] "Unit_WattHour"  Gateway_PAG,Ladegeraet_Konzern
 SG_ BMS_LadegrenzeAntw_Leistung : 48|12@1+ (200,0) [0|818600] "Unit_Watt"  Gateway_PAG,Ladegeraet_Konzern
 SG_ BMS_LadegrenzeAntw_Zaehler : 60|4@1+ (1,0) [0|13] "Unit_None"  Gateway_PAG,Ladegeraet_Konzern

BO_ 2463978763 BMS_30: 8 BMC_MLBevo
 SG_ BMS_30_CRC : 0|8@1+ (1,0) [0|255] ""  Gateway,Gateway_PAG
 SG_ BMS_30_BZ : 8|4@1+ (1,0) [0|15] ""  Gateway,Gateway_PAG
 SG_ BMS_Ueberspannung_Zelle : 61|3@1+ (1.0,0.0) [0.0|7] ""  Gateway,Gateway_PAG

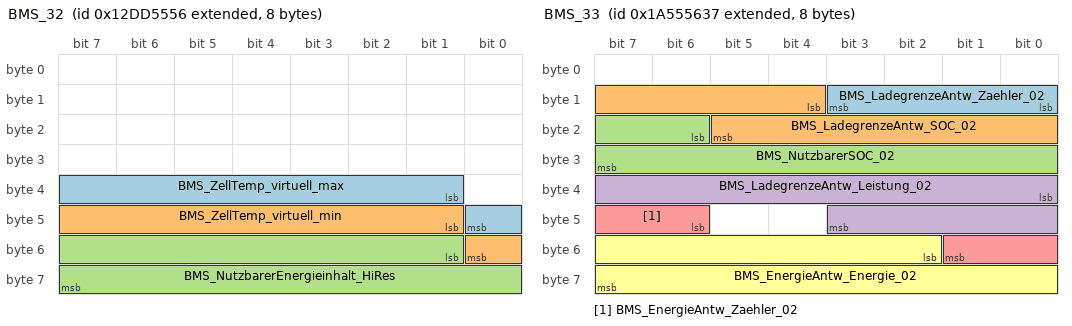
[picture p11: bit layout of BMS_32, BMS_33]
BO_ 2463978838 BMS_32: 8 BMC_MLBevo
 SG_ BMS_ZellTemp_virtuell_max : 33|8@1+ (0.5,-40) [-40.0|86.0] "Unit_DegreCelsi"  Gateway,Gateway_PAG,Sub_Gateway
 SG_ BMS_ZellTemp_virtuell_min : 41|8@1+ (0.5,-40) [-40.0|86.0] "Unit_DegreCelsi"  Gateway,Gateway_PAG,Sub_Gateway
 SG_ BMS_NutzbarerEnergieinhalt_HiRes : 49|15@1+ (4,-4) [0|131056] "Unit_WattHour"  Gateway,Gateway_PAG,Sub_Gateway

BO_ 2589283895 BMS_33: 8 BMC_MLBevo
 SG_ BMS_LadegrenzeAntw_Zaehler_02 : 8|4@1+ (1,0) [0|13] "Unit_None"  Ladegeraet_Konzern
 SG_ BMS_LadegrenzeAntw_SOC_02 : 12|10@1+ (0.1,0) [0.0|100.0] "Unit_PerCent"  Ladegeraet_Konzern
 SG_ BMS_NutzbarerSOC_02 : 22|10@1+ (0.1,0) [0.0|100.0] "Unit_PerCent"  Gateway,Gateway_PAG,Ladegeraet_Konzern
 SG_ BMS_LadegrenzeAntw_Leistung_02 : 32|12@1+ (200,0) [0|818600] "Unit_Watt"  Ladegeraet_Konzern
 SG_ BMS_EnergieAntw_Zaehler_02 : 46|4@1+ (1,0) [0|13] "Unit_None"  Ladegeraet_Konzern
 SG_ BMS_EnergieAntw_Energie_02 : 50|14@1+ (10,0) [0|163810] "Unit_WattHour"  Ladegeraet_Konzern

BO_ 2589284070 BMS_36: 8 BMC_MLBevo
 SG_ BMS_ExtLadeleistung : 12|10@1+ (1,0) [0|818] "Unit_KiloWatt"  Gateway,Gateway_PAG

BO_ 2589284007 BMS_48V_CALID_CVN: 8 BMS_MV
 SG_ BMS_48V_CALID_CVN_MUX M  : 0|2@1+ (1,0) [0|3] ""  Gateway,Gateway_PAG
 SG_ BMS_48V_CVN_VLD : 7|1@1+ (1.0,0.0) [0.0|1] ""  Gateway,Gateway_PAG
 SG_ BMS_48V_CALID_Index_01 m0  : 8|8@1+ (1.0,0.0) [0.0|255] ""  Gateway,Gateway_PAG
 SG_ BMS_48V_CALID_Index_05 m1  : 8|8@1+ (1.0,0.0) [0.0|255] ""  Gateway,Gateway_PAG
 SG_ BMS_48V_CALID_Index_09 m2  : 8|8@1+ (1.0,0.0) [0.0|255] ""  Gateway,Gateway_PAG
 SG_ BMS_48V_CALID_Index_13 m3  : 8|8@1+ (1.0,0.0) [0.0|255] ""  Gateway,Gateway_PAG
 SG_ BMS_48V_CALID_Index_02 m0  : 16|8@1+ (1.0,0.0) [0.0|255] ""  Gateway,Gateway_PAG
 SG_ BMS_48V_CALID_Index_06 m1  : 16|8@1+ (1.0,0.0) [0.0|255] ""  Gateway,Gateway_PAG
 SG_ BMS_48V_CALID_Index_10 m2  : 16|8@1+ (1.0,0.0) [0.0|255] ""  Gateway,Gateway_PAG
 SG_ BMS_48V_CALID_Index_14 m3  : 16|8@1+ (1.0,0.0) [0.0|255] ""  Gateway,Gateway_PAG
 SG_ BMS_48V_CALID_Index_03 m0  : 24|8@1+ (1.0,0.0) [0.0|255] ""  Gateway,Gateway_PAG
 SG_ BMS_48V_CALID_Index_07 m1  : 24|8@1+ (1.0,0.0) [0.0|255] ""  Gateway,Gateway_PAG
 SG_ BMS_48V_CALID_Index_11 m2  : 24|8@1+ (1.0,0.0) [0.0|255] ""  Gateway,Gateway_PAG
 SG_ BMS_48V_CALID_Index_15 m3  : 24|8@1+ (1.0,0.0) [0.0|255] ""  Gateway,Gateway_PAG
 SG_ BMS_48V_CALID_Index_04 m0  : 32|8@1+ (1.0,0.0) [0.0|255] ""  Gateway,Gateway_PAG
 SG_ BMS_48V_CALID_Index_08 m1  : 32|8@1+ (1.0,0.0) [0.0|255] ""  Gateway,Gateway_PAG
 SG_ BMS_48V_CALID_Index_12 m2  : 32|8@1+ (1.0,0.0) [0.0|255] ""  Gateway,Gateway_PAG
 SG_ BMS_48V_CALID_Index_16 m3  : 32|8@1+ (1.0,0.0) [0.0|255] ""  Gateway,Gateway_PAG
 SG_ BMS_48V_CVN_Byte_1 m0  : 40|8@1+ (1.0,0.0) [0.0|255] ""  Gateway,Gateway_PAG
 SG_ BMS_48V_CVN_Byte_2 m1  : 40|8@1+ (1.0,0.0) [0.0|255] ""  Gateway,Gateway_PAG
 SG_ BMS_48V_CVN_Byte_3 m2  : 40|8@1+ (1.0,0.0) [0.0|255] ""  Gateway,Gateway_PAG
 SG_ BMS_48V_CVN_Byte_4 m3  : 40|8@1+ (1.0,0.0) [0.0|255] ""  Gateway,Gateway_PAG

BO_ 2589284008 BMS_48V_Komponentenfehler_01: 8 BMS_MV
 SG_ BMS_48V_Komponentenfehler_01 : 0|2@1+ (1.0,0.0) [0.0|3] ""  Gateway,Gateway_PAG
 SG_ BMS_48V_Komponentenfehler_02 : 2|2@1+ (1.0,0.0) [0.0|3] ""  Gateway,Gateway_PAG
 SG_ BMS_48V_Komponentenfehler_03 : 4|2@1+ (1.0,0.0) [0.0|3] ""  Gateway,Gateway_PAG
 SG_ BMS_48V_Komponentenfehler_04 : 6|2@1+ (1.0,0.0) [0.0|3] ""  Gateway,Gateway_PAG
 SG_ BMS_48V_Komponentenfehler_05 : 8|2@1+ (1.0,0.0) [0.0|3] ""  Gateway,Gateway_PAG
 SG_ BMS_48V_Komponentenfehler_06 : 10|2@1+ (1.0,0.0) [0.0|3] ""  Gateway,Gateway_PAG
 SG_ BMS_48V_Komponentenfehler_07 : 12|2@1+ (1.0,0.0) [0.0|3] ""  Gateway,Gateway_PAG
 SG_ BMS_48V_Komponentenfehler_08 : 14|2@1+ (1.0,0.0) [0.0|3] ""  Gateway,Gateway_PAG
 SG_ BMS_48V_Komponentenfehler_09 : 16|2@1+ (1.0,0.0) [0.0|3] ""  Gateway,Gateway_PAG
 SG_ BMS_48V_Komponentenfehler_10 : 18|2@1+ (1.0,0.0) [0.0|3] ""  Gateway,Gateway_PAG
 SG_ BMS_48V_Komponentenfehler_11 : 20|2@1+ (1.0,0.0) [0.0|3] ""  Gateway,Gateway_PAG
 SG_ BMS_48V_Komponentenfehler_12 : 22|2@1+ (1.0,0.0) [0.0|3] ""  Gateway,Gateway_PAG
 SG_ BMS_48V_Komponentenfehler_13 : 24|2@1+ (1.0,0.0) [0.0|3] ""  Gateway,Gateway_PAG
 SG_ BMS_48V_Komponentenfehler_14 : 26|2@1+ (1.0,0.0) [0.0|3] ""  Gateway,Gateway_PAG
 SG_ BMS_48V_Komponentenfehler_15 : 28|2@1+ (1.0,0.0) [0.0|3] ""  Gateway,Gateway_PAG
 SG_ BMS_48V_Komponentenfehler_16 : 30|2@1+ (1.0,0.0) [0.0|3] ""  Gateway,Gateway_PAG
 SG_ BMS_48V_Komponentenfehler_17 : 32|2@1+ (1.0,0.0) [0.0|3] ""  Gateway,Gateway_PAG
 SG_ BMS_48V_Komponentenfehler_18 : 34|2@1+ (1.0,0.0) [0.0|3] ""  Gateway,Gateway_PAG
 SG_ BMS_48V_Komponentenfehler_19 : 36|2@1+ (1.0,0.0) [0.0|3] ""  Gateway,Gateway_PAG
 SG_ BMS_48V_Komponentenfehler_20 : 38|2@1+ (1.0,0.0) [0.0|3] ""  Gateway,Gateway_PAG
 SG_ BMS_48V_Komponentenfehler_21 : 40|2@1+ (1.0,0.0) [0.0|3] ""  Gateway,Gateway_PAG
 SG_ BMS_48V_Komponentenfehler_22 : 42|2@1+ (1.0,0.0) [0.0|3] ""  Gateway,Gateway_PAG
 SG_ BMS_48V_Komponentenfehler_23 : 44|2@1+ (1.0,0.0) [0.0|3] ""  Gateway,Gateway_PAG
 SG_ BMS_48V_Komponentenfehler_24 : 46|2@1+ (1.0,0.0) [0.0|3] ""  Gateway,Gateway_PAG
 SG_ BMS_48V_Komponentenfehler_25 : 48|2@1+ (1.0,0.0) [0.0|3] ""  Gateway,Gateway_PAG
 SG_ BMS_48V_Komponentenfehler_26 : 50|2@1+ (1.0,0.0) [0.0|3] ""  Gateway,Gateway_PAG
 SG_ BMS_48V_Komponentenfehler_27 : 52|2@1+ (1.0,0.0) [0.0|3] ""  Gateway,Gateway_PAG
 SG_ BMS_48V_Komponentenfehler_28 : 54|2@1+ (1.0,0.0) [0.0|3] ""  Gateway,Gateway_PAG
 SG_ BMS_48V_Komponentenfehler_29 : 56|2@1+ (1.0,0.0) [0.0|3] ""  Gateway,Gateway_PAG
 SG_ BMS_48V_Komponentenfehler_30 : 58|2@1+ (1.0,0.0) [0.0|3] ""  Gateway,Gateway_PAG
 SG_ BMS_48V_Komponentenfehler_31 : 60|2@1+ (1.0,0.0) [0.0|3] ""  Gateway,Gateway_PAG
 SG_ BMS_48V_Komponentenfehler_VLD : 62|1@1+ (1.0,0.0) [0.0|1] ""  Gateway,Gateway_PAG

BO_ 880 BMS_CMC_01: 8 BMC_MLBevo
 SG_ BMS_CMC_01_MUX M  : 0|4@1+ (1,0) [0|15] ""  Sub_Gateway
 SG_ BMS_CMC_Zellspannung_001 m0  : 4|12@1+ (1,1000) [1000|5091] "Unit_MilliVolt"  Sub_Gateway
 SG_ BMS_CMC_Zellspannung_006 m1  : 4|12@1+ (1,1000) [1000|5091] "Unit_MilliVolt"  Sub_Gateway
 SG_ BMS_CMC_Zellspannung_011 m2  : 4|12@1+ (1,1000) [1000|5091] "Unit_MilliVolt"  Sub_Gateway
 SG_ BMS_CMC_Zellspannung_016 m3  : 4|12@1+ (1,1000) [1000|5091] "Unit_MilliVolt"  Sub_Gateway
 SG_ BMS_CMC_Zellspannung_021 m4  : 4|12@1+ (1,1000) [1000|5091] "Unit_MilliVolt"  Sub_Gateway
 SG_ BMS_CMC_Zellspannung_026 m5  : 4|12@1+ (1,1000) [1000|5091] "Unit_MilliVolt"  Sub_Gateway
 SG_ BMS_CMC_Zellspannung_031 m6  : 4|12@1+ (1,1000) [1000|5091] "Unit_MilliVolt"  Sub_Gateway
 SG_ BMS_CMC_Zellspannung_036 m7  : 4|12@1+ (1,1000) [1000|5091] "Unit_MilliVolt"  Sub_Gateway
 SG_ BMS_CMC_Zellspannung_041 m8  : 4|12@1+ (1,1000) [1000|5091] "Unit_MilliVolt"  Sub_Gateway
 SG_ BMS_CMC_Zellspannung_046 m9  : 4|12@1+ (1,1000) [1000|5091] "Unit_MilliVolt"  Sub_Gateway
 SG_ BMS_CMC_Zellspannung_051 m10  : 4|12@1+ (1,1000) [1000|5091] "Unit_MilliVolt"  Sub_Gateway
 SG_ BMS_CMC_Zellspannung_056 m11  : 4|12@1+ (1,1000) [1000|5091] "Unit_MilliVolt"  Sub_Gateway
 SG_ BMS_CMC_Zellspannung_061 m12  : 4|12@1+ (1,1000) [1000|5091] "Unit_MilliVolt"  Sub_Gateway
 SG_ BMS_CMC_Zellspannung_066 m13  : 4|12@1+ (1,1000) [1000|5091] "Unit_MilliVolt"  Sub_Gateway
 SG_ BMS_CMC_Zellspannung_071 m14  : 4|12@1+ (1,1000) [1000|5091] "Unit_MilliVolt"  Sub_Gateway
 SG_ BMS_CMC_Zellspannung_076 m15  : 4|12@1+ (1,1000) [1000|5091] "Unit_MilliVolt"  Sub_Gateway
 SG_ BMS_CMC_Zellspannung_002 m0  : 16|12@1+ (1,1000) [1000|5091] "Unit_MilliVolt"  Sub_Gateway
 SG_ BMS_CMC_Zellspannung_007 m1  : 16|12@1+ (1,1000) [1000|5091] "Unit_MilliVolt"  Sub_Gateway
 SG_ BMS_CMC_Zellspannung_012 m2  : 16|12@1+ (1,1000) [1000|5091] "Unit_MilliVolt"  Sub_Gateway
 SG_ BMS_CMC_Zellspannung_017 m3  : 16|12@1+ (1,1000) [1000|5091] "Unit_MilliVolt"  Sub_Gateway
 SG_ BMS_CMC_Zellspannung_022 m4  : 16|12@1+ (1,1000) [1000|5091] "Unit_MilliVolt"  Sub_Gateway
 SG_ BMS_CMC_Zellspannung_027 m5  : 16|12@1+ (1,1000) [1000|5091] "Unit_MilliVolt"  Sub_Gateway
 SG_ BMS_CMC_Zellspannung_032 m6  : 16|12@1+ (1,1000) [1000|5091] "Unit_MilliVolt"  Sub_Gateway
 SG_ BMS_CMC_Zellspannung_037 m7  : 16|12@1+ (1,1000) [1000|5091] "Unit_MilliVolt"  Sub_Gateway
 SG_ BMS_CMC_Zellspannung_042 m8  : 16|12@1+ (1,1000) [1000|5091] "Unit_MilliVolt"  Sub_Gateway
 SG_ BMS_CMC_Zellspannung_047 m9  : 16|12@1+ (1,1000) [1000|5091] "Unit_MilliVolt"  Sub_Gateway
 SG_ BMS_CMC_Zellspannung_052 m10  : 16|12@1+ (1,1000) [1000|5091] "Unit_MilliVolt"  Sub_Gateway
 SG_ BMS_CMC_Zellspannung_057 m11  : 16|12@1+ (1,1000) [1000|5091] "Unit_MilliVolt"  Sub_Gateway
 SG_ BMS_CMC_Zellspannung_062 m12  : 16|12@1+ (1,1000) [1000|5091] "Unit_MilliVolt"  Sub_Gateway
 SG_ BMS_CMC_Zellspannung_067 m13  : 16|12@1+ (1,1000) [1000|5091] "Unit_MilliVolt"  Sub_Gateway
 SG_ BMS_CMC_Zellspannung_072 m14  : 16|12@1+ (1,1000) [1000|5091] "Unit_MilliVolt"  Sub_Gateway
 SG_ BMS_CMC_Zellspannung_077 m15  : 16|12@1+ (1,1000) [1000|5091] "Unit_MilliVolt"  Sub_Gateway
 SG_ BMS_CMC_Zellspannung_003 m0  : 28|12@1+ (1,1000) [1000|5091] "Unit_MilliVolt"  Sub_Gateway
 SG_ BMS_CMC_Zellspannung_008 m1  : 28|12@1+ (1,1000) [1000|5091] "Unit_MilliVolt"  Sub_Gateway
 SG_ BMS_CMC_Zellspannung_013 m2  : 28|12@1+ (1,1000) [1000|5091] "Unit_MilliVolt"  Sub_Gateway
 SG_ BMS_CMC_Zellspannung_018 m3  : 28|12@1+ (1,1000) [1000|5091] "Unit_MilliVolt"  Sub_Gateway
 SG_ BMS_CMC_Zellspannung_023 m4  : 28|12@1+ (1,1000) [1000|5091] "Unit_MilliVolt"  Sub_Gateway
 SG_ BMS_CMC_Zellspannung_028 m5  : 28|12@1+ (1,1000) [1000|5091] "Unit_MilliVolt"  Sub_Gateway
 SG_ BMS_CMC_Zellspannung_033 m6  : 28|12@1+ (1,1000) [1000|5091] "Unit_MilliVolt"  Sub_Gateway
 SG_ BMS_CMC_Zellspannung_038 m7  : 28|12@1+ (1,1000) [1000|5091] "Unit_MilliVolt"  Sub_Gateway
 SG_ BMS_CMC_Zellspannung_043 m8  : 28|12@1+ (1,1000) [1000|5091] "Unit_MilliVolt"  Sub_Gateway
 SG_ BMS_CMC_Zellspannung_048 m9  : 28|12@1+ (1,1000) [1000|5091] "Unit_MilliVolt"  Sub_Gateway
 SG_ BMS_CMC_Zellspannung_053 m10  : 28|12@1+ (1,1000) [1000|5091] "Unit_MilliVolt"  Sub_Gateway
 SG_ BMS_CMC_Zellspannung_058 m11  : 28|12@1+ (1,1000) [1000|5091] "Unit_MilliVolt"  Sub_Gateway
 SG_ BMS_CMC_Zellspannung_063 m12  : 28|12@1+ (1,1000) [1000|5091] "Unit_MilliVolt"  Sub_Gateway
 SG_ BMS_CMC_Zellspannung_068 m13  : 28|12@1+ (1,1000) [1000|5091] "Unit_MilliVolt"  Sub_Gateway
 SG_ BMS_CMC_Zellspannung_073 m14  : 28|12@1+ (1,1000) [1000|5091] "Unit_MilliVolt"  Sub_Gateway
 SG_ BMS_CMC_Zellspannung_078 m15  : 28|12@1+ (1,1000) [1000|5091] "Unit_MilliVolt"  Sub_Gateway
 SG_ BMS_CMC_Zellspannung_004 m0  : 40|12@1+ (1,1000) [1000|5091] "Unit_MilliVolt"  Sub_Gateway
 SG_ BMS_CMC_Zellspannung_009 m1  : 40|12@1+ (1,1000) [1000|5091] "Unit_MilliVolt"  Sub_Gateway
 SG_ BMS_CMC_Zellspannung_014 m2  : 40|12@1+ (1,1000) [1000|5091] "Unit_MilliVolt"  Sub_Gateway
 SG_ BMS_CMC_Zellspannung_019 m3  : 40|12@1+ (1,1000) [1000|5091] "Unit_MilliVolt"  Sub_Gateway
 SG_ BMS_CMC_Zellspannung_024 m4  : 40|12@1+ (1,1000) [1000|5091] "Unit_MilliVolt"  Sub_Gateway
 SG_ BMS_CMC_Zellspannung_029 m5  : 40|12@1+ (1,1000) [1000|5091] "Unit_MilliVolt"  Sub_Gateway
 SG_ BMS_CMC_Zellspannung_034 m6  : 40|12@1+ (1,1000) [1000|5091] "Unit_MilliVolt"  Sub_Gateway
 SG_ BMS_CMC_Zellspannung_039 m7  : 40|12@1+ (1,1000) [1000|5091] "Unit_MilliVolt"  Sub_Gateway
 SG_ BMS_CMC_Zellspannung_044 m8  : 40|12@1+ (1,1000) [1000|5091] "Unit_MilliVolt"  Sub_Gateway
 SG_ BMS_CMC_Zellspannung_049 m9  : 40|12@1+ (1,1000) [1000|5091] "Unit_MilliVolt"  Sub_Gateway
 SG_ BMS_CMC_Zellspannung_054 m10  : 40|12@1+ (1,1000) [1000|5091] "Unit_MilliVolt"  Sub_Gateway
 SG_ BMS_CMC_Zellspannung_059 m11  : 40|12@1+ (1,1000) [1000|5091] "Unit_MilliVolt"  Sub_Gateway
 SG_ BMS_CMC_Zellspannung_064 m12  : 40|12@1+ (1,1000) [1000|5091] "Unit_MilliVolt"  Sub_Gateway
 SG_ BMS_CMC_Zellspannung_069 m13  : 40|12@1+ (1,1000) [1000|5091] "Unit_MilliVolt"  Sub_Gateway
 SG_ BMS_CMC_Zellspannung_074 m14  : 40|12@1+ (1,1000) [1000|5091] "Unit_MilliVolt"  Sub_Gateway
 SG_ BMS_CMC_Zellspannung_079 m15  : 40|12@1+ (1,1000) [1000|5091] "Unit_MilliVolt"  Sub_Gateway
 SG_ BMS_CMC_Zellspannung_005 m0  : 52|12@1+ (1,1000) [1000|5091] "Unit_MilliVolt"  Sub_Gateway
 SG_ BMS_CMC_Zellspannung_010 m1  : 52|12@1+ (1,1000) [1000|5091] "Unit_MilliVolt"  Sub_Gateway
 SG_ BMS_CMC_Zellspannung_015 m2  : 52|12@1+ (1,1000) [1000|5091] "Unit_MilliVolt"  Sub_Gateway
 SG_ BMS_CMC_Zellspannung_020 m3  : 52|12@1+ (1,1000) [1000|5091] "Unit_MilliVolt"  Sub_Gateway
 SG_ BMS_CMC_Zellspannung_025 m4  : 52|12@1+ (1,1000) [1000|5091] "Unit_MilliVolt"  Sub_Gateway
 SG_ BMS_CMC_Zellspannung_030 m5  : 52|12@1+ (1,1000) [1000|5091] "Unit_MilliVolt"  Sub_Gateway
 SG_ BMS_CMC_Zellspannung_035 m6  : 52|12@1+ (1,1000) [1000|5091] "Unit_MilliVolt"  Sub_Gateway
 SG_ BMS_CMC_Zellspannung_040 m7  : 52|12@1+ (1,1000) [1000|5091] "Unit_MilliVolt"  Sub_Gateway
 SG_ BMS_CMC_Zellspannung_045 m8  : 52|12@1+ (1,1000) [1000|5091] "Unit_MilliVolt"  Sub_Gateway
 SG_ BMS_CMC_Zellspannung_050 m9  : 52|12@1+ (1,1000) [1000|5091] "Unit_MilliVolt"  Sub_Gateway
 SG_ BMS_CMC_Zellspannung_055 m10  : 52|12@1+ (1,1000) [1000|5091] "Unit_MilliVolt"  Sub_Gateway
 SG_ BMS_CMC_Zellspannung_060 m11  : 52|12@1+ (1,1000) [1000|5091] "Unit_MilliVolt"  Sub_Gateway
 SG_ BMS_CMC_Zellspannung_065 m12  : 52|12@1+ (1,1000) [1000|5091] "Unit_MilliVolt"  Sub_Gateway
 SG_ BMS_CMC_Zellspannung_070 m13  : 52|12@1+ (1,1000) [1000|5091] "Unit_MilliVolt"  Sub_Gateway
 SG_ BMS_CMC_Zellspannung_075 m14  : 52|12@1+ (1,1000) [1000|5091] "Unit_MilliVolt"  Sub_Gateway
 SG_ BMS_CMC_Zellspannung_080 m15  : 52|12@1+ (1,1000) [1000|5091] "Unit_MilliVolt"  Sub_Gateway

BO_TX_BU_ 64 :Gateway,Gateway_PAG;
BO_TX_BU_ 2589283757 :Gateway,Gateway_PAG;
BO_TX_BU_ 2536720384 :Gateway,Gateway_PAG;
BO_TX_BU_ 2536720385 :Gateway,Gateway_PAG;
BO_TX_BU_ 2536711424 :Gateway,Gateway_PAG;
BO_TX_BU_ 2536711425 :Gateway,Gateway_PAG;
BO_TX_BU_ 2536711426 :Gateway,Gateway_PAG;
BO_TX_BU_ 2536711427 :Gateway,Gateway_PAG;
BO_TX_BU_ 2536711429 :Gateway,Gateway_PAG;
BO_TX_BU_ 2536767280 :Gateway,Gateway_PAG,Ladegeraet_Konzern;
BO_TX_BU_ 2536706320 :Gateway,Gateway_PAG;
BO_TX_BU_ 1615 :Gateway,Gateway_PAG;
BO_TX_BU_ 1626 :Gateway,Gateway_PAG;

CM_ "MLBevo_HCAN_V8.24.00F Generated by BusNet_NG_Produktiv 9.24.4";
CM_ BU_ AWC "Automatic Wireless Charging";
CM_ BU_ BMC_MLBevo "Hybrid Batteriemanagement (Battery Energy Control Module) MLBevo Batterie Managment System";
CM_ BU_ BMS_NV "Speicher fuer Mild-Hybrid";
CM_ BU_ CBC "Kombination aus DCDC_HV und DCDC_HV_02 (nur Gen2)";
CM_ BU_ DCDC_800V_PAG "DCDC 800V im BEV PAG";
CM_ BU_ DCDC_HV "Standalone DCDC im BEV";
CM_ BU_ DCDC_HV_02 "HV-Booster
 DC/DC Wandler - Zielspannung HV (400V auf 800V)";
CM_ BU_ DCDC_IHEV "KD: Spannungswandler - DC/DC Converter Control Module
Standalone DCDC-Wandler im MLBevo iHEV ";
CM_ BU_ FCU_MLBevo_FCEV "Brennstoffzellenantrieb -Fuel Cell Control Module
DFL-Kürzel: FCU";
CM_ BU_ Gateway "MLBevo Diagnoseinterface für Datenbus

connected Gateway Version 2.0, Zulieferer Conti Markdorf
- e & e4

connected Gateway Version 3.1, Zulieferer ESR/Lear
- e, e2, e5, e6";
CM_ BU_ Gateway_PAG "Gateway-Variante für PAG - Absprungbasis Gateway 3.x";
CM_ BU_ Ladegeraet_2 "OBC2 - OnBoardCharger2";
CM_ BU_ Ladegeraet_Konzern "OnBoardCharger (Ladegeraet) MLBEvo
Ladegeraet_Konzern";
CM_ BU_ LE1 "Leistungselektronik1 BEV";
CM_ BU_ LE2 "Leistungselektronik2 BEV";
CM_ BU_ LE_MLBevo "Elektroantrieb (Drive Motor Control Module): Leistungselektronik Hybrid im PHEV
***EA**SNI:124**EA*** Dieser EA-Tag darf nicht verändert werden!
";
CM_ BU_ Sub_Gateway "C7 PHEV China
MLBevo PHEV China";
CM_ BU_ TME "Thermomanagment Elektrofahrzeuge
zur Koordination Klima & Batterie MLBevo";

CM_ SG_ 64 AB_Anzeige_Fussg "Anzeige für ausgelöste Fussgängerschutz-Aktuatorik";
CM_ SG_ 64 AB_Belegung_VF "Belegungserkennung vorne Fahrer.";
CM_ SG_ 64 AB_Crash_Int "Crash_Intensität_1 = fahrzeugabhängige Reaktionen im Crash
Crash_Intensität_2 = fahrzeugabhängige Reaktionen im Crash
Crash_Intensität_3 = fahrzeugabhängige Reaktionen im Crash

Die jeweiligen fahrzeugabhängigen Reaktionen im Crash sind in einem separ";
CM_ SG_ 64 AB_Deaktiviert "Airbag oder Gurtstraffer wurden per Anpassung deaktiviert: Aktualisierung erst nach Selbsttest";
CM_ SG_ 64 AB_Deaktivierung_HV "Deaktivierung des HV-Systems und der HV-Teilnehmer im Crash (u.a. Hybrid- und Elektrofahrzeuge)";
CM_ SG_ 64 AB_Diagnose "Airbag in Diagnose";
CM_ SG_ 64 AB_EDR_Trigger "Triggerbedingung zur dezentralen Aufzeichnung unfallrelevanter Daten im Event Data Recorder";
CM_ SG_ 64 AB_Erh_Auf_VB "Der Fahrer soll bei einem Statuswechsel des Beifahrerairbags (ausgelöst durch die Beifahrerinsassenerkennung oder den Schlüsselschloßschalter) aufmerksam gemacht werden durch eine Anzeige im Kombi. Nur Audi: gültig für: AB2 (4-Türer AU352), B7, C6, D3";
CM_ SG_ 64 AB_Front_Crash "Bit wird bei Überschreitung der Gurtstraffer-, US- und RdW-Schwelle gesetzt";
CM_ SG_ 64 AB_Gurtwarn_VB "Beifahrer hat Gurt nicht gesteckt, Anzeige im Kombi";
CM_ SG_ 64 AB_Gurtwarn_VF "Fahrer hat Gurt nicht gesteckt, Anzeige im Kombi";
CM_ SG_ 64 AB_Heck_Crash "Wird für alle neu anlaufenden Projekte umgesetzt: AB8.4, Audi8/VW8";
CM_ SG_ 64 AB_Lampe "Sicherheitswarnlampe im Kombi wird vom Airbag-SG angesteuert; Zustand der Lampe wird auf dem CAN-Bus ausgegeben (auch Blinkinformation).";
CM_ SG_ 64 AB_MKB_Anforderung "Anforderung Multi-Kollisions-Bremsung";
CM_ SG_ 64 AB_MKB_gueltig "Multi-Kollisions-Bremsung im Airbag freigeschaltet";
CM_ SG_ 64 AB_RGS_Anst "PreCrash-Ansteuerung reversibler Gurtstraffer (Aktivierung und Kraftniveau)

10xx = deaktiviert";
CM_ SG_ 64 AB_Rollover_Crash "Wird im B6/B7 Cabrio und New Beetle Cabrio bedient. ";
CM_ SG_ 64 AB_SB_Crash "Z.Zt. nur in Verbindung mit Crash-Intensität >= 100b (Kraftstoffpumpenabschaltung) verwendet.
";
CM_ SG_ 64 AB_SF_Crash "Z.Zt. nur in Verbindung mit Crash-Intensität >= 100b (Kraftstoffpumpenabschaltung) verwendet.";
CM_ SG_ 64 AB_Stellgliedtest "Information, ob Airbag im Stellgliedtest ist, um eine Notrufauflösung beim Stellgliedtest zu verhindern";
CM_ SG_ 64 AB_Systemfehler "Systemfehler Ggf. wird Warnlampe dauernd eingeschaltet.";
CM_ SG_ 64 AB_Texte_AKS "Textanzeige für pyrotechnische Auslösung der aktiven Kopfstütze (AKS)";
CM_ SG_ 64 AB_VB_deaktiviert "Als Option vorgehalten, Beifahrerairbag wurden per Schlüsselschalter oder Insassenerkennung deaktiviert";
CM_ SG_ 64 AB_Versorgungsspannung "Übertragung der Plausibilitätsinformation Kl.15-Last vs. Kl.15-CAN.
Bedienung im Fall Kl.15-Last 'EIN' und Kl.15-CAN 'AUS' mit Ausgabe Warnung/Akustik im Kombi.";
CM_ SG_ 64 Airbag_01_CRC "Für MLB:
'Berechnung siehe Lastenheft 'Kommunikationsabsicherung für FlexRay und CAN''

Ab MQB und MLBevo:
'Berechnung siehe Lastenheft 'End-to-End Kommunikationsabsicherung''

Endwerte siehe Begleitdokument 'S-PDU Kennungsfolgen'";
CM_ SG_ 64 SC_LowSpeedCrashErkannt "Crash erkannt bei niedriger Geschwindigkeit";
CM_ SG_ 64 SC_Masterzeit "Masterzeit für alle Objektlisten";
CM_ SG_ 64 SC_Masterzeit_Offset "Erweiterung des Signals SC_Masterzeit um zwei höherwertige Bits, so dass ein Zeitbereich von ~20s (statt 5s) abgedeckt werden kann. Der aus SC_Masterzeit_Offset und SC_Masterzeit zu bildende Zeitstempel wird für die Synchronisation von Ereignissen der Fun";

CM_ SG_ 2589283757 AT_VALID_TIME "Valide (plausible) Zeit vom Zeitmaster der authentischen Zeit im cGW.

Der Zeitmaster der authentischen Zeit im cGW führt eine Plausibilisierung der GPS-Zeit über die Kommunikation mit dem Backend durch. Diese plausibilisierte Zeit wird in diesem Signal";

CM_ SG_ 2589283607 AWC_01_BZ "Fortlaufender Botschaftszaehler";
CM_ SG_ 2589283607 AWC_01_CRC "Für MLB:
'Berechnung siehe Lastenheft 'Kommunikationsabsicherung für FlexRay und CAN''

Ab MQB und MLBevo:
'Berechnung siehe Lastenheft 'End-to-End Kommunikationsabsicherung''

Endwerte siehe Begleitdokument 'S-PDU Kennungsfolgen'";
CM_ SG_ 2589283607 AWC_Fehlerstatus "aktueller Fehlerstatus des Ladegerätes
0: Komponente IO (keine HVK relevanter Fehler)
1: Eingeschränkte_Komponentenfunktion AWC Laden nicht möglich
2: reserve
3: Eingeschr_Komponentenfunktion aufgrund HV-Interlock-Fehler (nur wenn LHVIL)
4- 5: reserv";
CM_ SG_ 2589283607 AWC_IstModus "momentaner AWC -Lademodus, d.h. aktueller Zustand der Energieübertragung (inaktiv, aktiv, verzögert oder deaktiviert)";
CM_ SG_ 2589283607 AWC_IstSpannung "Ausgangsspannung AWC Lader";
CM_ SG_ 2589283607 AWC_IstStrom "Ausgangsstrom AWC";
CM_ SG_ 2589283607 AWC_MaxLadLeistung "Maximale Leistung AWC-Ladegerät bezogen auf die maximale Leistung AWC-Infrastruktur (Kabel, Ladestation) und Berücksichtigung des AWC-Ladegerät-Wirkungsgrades";
CM_ SG_ 2589283607 AWC_Status_Spgfreiheit "Information über Spannungsfreiheit der HV-Komponenten für Diagnose und Kundendienst.";

CM_ SG_ 2589283618 AWC_Fehler_FOD "FOD System defekt
(Foreign Object Detection = Metallerkennung)";
CM_ SG_ 2589283618 AWC_Fehler_Kommunikation "AWC Kommunikation zw. Infrastrukturspule und Fzg-Spule defekt";
CM_ SG_ 2589283618 AWC_Fehler_LOP "LOP System defekt
(Living Object Protection = Personenschutz)";
CM_ SG_ 2589283618 AWC_Fehler_zMover "z-Mover System defekt";
CM_ SG_ 2589283618 AWC_Ladeoption_Infrastruktur "Rückmeldung an das Lademanagement welche Ladeoption an der Infrastrukturseite ausgewählt wurde";
CM_ SG_ 2589283618 AWC_Panel_PositionX "Signal beschreibt den Abstand in x-Richtung (Fzg- Koordinatensystem) der Ladeplatten (optimale Ladeposition)";
CM_ SG_ 2589283618 AWC_Panel_PositionY "Signal beschreibt den Abstand in y-Richtung (Fzg- Koordinatensystem) der Ladeplatten (optimale Ladeposition)";
CM_ SG_ 2589283618 AWC_Panel_Verdrehwinkel "Signal beschreibt die Verdrehung der Bodenplatte zum Fahrzeug";
CM_ SG_ 2589283618 AWC_Positionierhilfe "Status AWC Positionierhilfe und Aktivierungssignal zur Aufschaltung der OPS-Anzeige (AWC Parkhilfe)";
CM_ SG_ 2589283618 AWC_Spielschutz "Spielschutz im AWC verhindert, dass z-Mover wiederholt angehoben und abgesenkt werden kann.
Signal gibt an ob Spielschutz aktiv ist.";
CM_ SG_ 2589283618 AWC_Status "momentaner Betriebszustand AWC inkl. z-Mover";
CM_ SG_ 2589283618 AWC_Verzoegerung_FOD "Verzögerung des Ladevorgangs aufgrund des FOD (Foreign Object Detection = Metallerkennung)";
CM_ SG_ 2589283618 AWC_Verzoegerung_LOP "Verzögerung des Ladevorgangs aufgrund des LOP (Living Object Protection = Personenschutz)";
CM_ SG_ 2589283618 AWC_Verzoegerung_Temp "Verzögerung des Ladevorgangs aufgrund der Umgebungstemperatur außerhalb Ladespec.";
CM_ SG_ 2589283618 AWC_Verzoegerung_zMover "Verzögerung des Ladevorgangs aufgrund des z-Movers";

CM_ SG_ 2536720384 BAP_AWC_ASG_01_Header "AWC Anzeigesteuergerät (ASG BAP Strecke)";

CM_ SG_ 2536720385 BAP_AWC_ASG_02_Header "AWC Anzeigesteuergerät (ASG BAP Strecke)";

CM_ SG_ 2536720400 BAP_AWC_FSG_01_Header "AWC Funktionssteuergeraet";

CM_ SG_ 2536711429 BAP_BatteryControl_ASG_06_Header "BatteryControl Anzeigesteuergerät Head-Up Display";

CM_ SG_ 2536706310 BAP_Uhrzeit_ASG_07_Header "Uhrzeit Anzeigesteuergeraet AWC";

CM_ SG_ 1615 BCM1_Hinweis_Lichtnachlauf "Signal dient der Anzeige eines aktiven Lichtnachlaufes beim automatischen Abschalten der Klemme S und Klemme 15. Der Lichtnachlauf wird gestartet, wenn die Klemme 15 bei aktivem Fahrlicht deaktiviert wird.";
CM_ SG_ 1615 BCM1_HUD_Eyeboxposition "Position des Eyebox Drehgebers";
CM_ SG_ 1615 BCM1_HUD_Eyeboxposition_Status "Status Eyebox Drehgeber";
CM_ SG_ 1615 BCM1_HUD_Taster "Status HUD Taster";
CM_ SG_ 1615 BCM1_LDS_Stellung "Das Signal wird vom AFS / LWR Steuergerät empfangen und dient der Verifizierung der Lichtdrehschalterstellung. Intelligente Lichtfunktionen wie dyn. KL und gleitende Leuchtweite (GLW) nur bei LDS = 'AUTO'.";
CM_ SG_ 1615 BCM1_Lichtwarn_Texte "Anforderung von Lichtwarnungen vom BCM1 zum Kombi
MLB: nur Werte 0..2";
CM_ SG_ 1615 BCM1_Spannungs_Anf "Forderung des BCM1-SG's zur Spannungsanhebung.";
CM_ SG_ 1615 BCM1_Status_Ladeanzeige "Leuchtenstatus zur Anzeige von ChargeCheck
Sendeart = Cyclic, Zykluszeit = 100ms anlog des Signals im MQB (Licht_hinten_01/BCM_Status_Ladeanzeige) auf dem ACAN";
CM_ SG_ 1615 BCM1_Stellgroesse_Kl_58s "Rohwert Dimmpoti";
CM_ SG_ 1615 CHA_Drehschalter_Modus "Charisma Drehschalter Modus";
CM_ SG_ 1615 CHA_Kombi_Texte "Anzeige des aktuellen Charisma-Fahrprofiles im Kombi.
Die Texte werden HUT-Spezifisch in einem Schnittstellen-LAH definiert.";
CM_ SG_ 1615 KRH_Stufe_LED_li "Statusmeldung Kopfraumheizung links";
CM_ SG_ 1615 KRH_Stufe_LED_re "Statusmeldung Kopfraumheizung rechts";
CM_ SG_ 1615 LV_Laserlicht_Texte "Anforderung Kombi-Texte bezüglich Laser-Fernlicht";
CM_ SG_ 1615 LV_LED_Scheinwerfer_li_def "Fehlerstatus LED-Scheinwerfer links
";
CM_ SG_ 1615 LV_LED_Scheinwerfer_re_def "Fehlerstatus LED-Scheinwerfer rechts";

CM_ SG_ 1626 APS_Tongeber_defekt "Status APS-Tongeber zur HMI-Ansteuerng der RCTA-Funktion";
CM_ SG_ 1626 BCM1_AFS_Lampe "Ansteuerung der AFS-Fehlermeldung im Kombi";
CM_ SG_ 1626 BCM1_EasyEntry_Status "Status EasyEntry für Lenksäule (wird auch von IVB verwendet)";
CM_ SG_ 1626 BCM1_Fahrlicht_Hinweis "Signal zum Kombi um den Hinweis 'Bitte Fahrlicht einschalten' anzufordern";
CM_ SG_ 1626 BCM1_Hinweis_Lichtnachlauf "Signal dient der Anzeige eines aktiven Lichtnachlaufes beim automatischen Abschalten der Klemme S und Klemme 15. Der Lichtnachlauf wird gestartet, wenn die Klemme 15 bei aktivem Fahrlicht deaktiviert wird.";
CM_ SG_ 1626 BCM1_Kl_15_HW_erkannt "Erkennung Klemme 15 (Hardware) vom BCM1
";
CM_ SG_ 1626 BCM1_Kl_15_Sig_HW_erkannt "Erkennung Klemme 15 Signal (Hardware) vom BCM1";
CM_ SG_ 1626 BCM1_LDS_Stellung "Das Signal wird vom AFS / LWR Steuergerät empfangen und dient der Verifizierung der Lichtdrehschalterstellung. Intelligente Lichtfunktionen wie dyn. KL und gleitende Leuchtweite (GLW) nur bei LDS = 'AUTO'.";
CM_ SG_ 1626 BCM1_Lenksaeule_aktiv "Lenksaeulenverstellung aktiv";
CM_ SG_ 1626 BCM1_Licht_Warn "Lichtwarnung";
CM_ SG_ 1626 BCM1_Lichtwarn_Texte "Anforderung von Lichtwarnungen vom BCM1 zum Kombi
MLB: nur Werte 0..2";
CM_ SG_ 1626 BCM1_MH_Schalter "Motorhaubenkontakt";
CM_ SG_ 1626 BCM1_MH_WIV_Schalter "Bewerteter Motorhaubenkontakt fuer WIV";
CM_ SG_ 1626 BCM1_NV_Taster "BCM1_NV_Taster gibt an, ob der NightVision-Taster im Lichtdrehschalter-Modul aktuell betaetigt wird.";
CM_ SG_ 1626 BCM1_Reisemodus_Texte "Ansteuerung der Reisemodus-Texte im Kombi";
CM_ SG_ 1626 BCM1_Rueckfahrlicht_Schalter "Rückfahrlichtschalter
ab MQB/ MLBevo: Die Ganginformation wird unentprellt übertragen, im AT-Getriebe wird evtl. kurzzeitig der R-Gang angezeigt. Eine Entprellung muß im Empfänger erfolgen (typisch 400ms).";
CM_ SG_ 1626 BCM1_Schluesselsuche_Anf "Anforderung von BCM1 an BCM2:
Schlüsselpolling aktivieren

Nötig bei z.B. aktiviertem Annäherungslicht";
CM_ SG_ 1626 BCM1_St_SW_Diebstahl_links "Signal zur Anzeige, dass der linke Scheinwerfer gestohlen wurde";
CM_ SG_ 1626 BCM1_St_SW_Diebstahl_rechts "Signal zur Anzeige, dass der rechte Scheinwerfer gestohlen wurde";
CM_ SG_ 1626 BCM1_Valet_Parking_Taster "Valet Parking Taster ";
CM_ SG_ 1626 BCM1_Warnblink_Taster "Warnblinktaster";
CM_ SG_ 1626 BCM_Bremsbelag_Sensor "Sensorsignal der Stromschleife  für Bremsbelagverschleiß aktuell, entstört, unbewertet";
CM_ SG_ 1626 BCM_Bremsfluessigkeit_Sensor "Kontaktsignal des Sensorschalters für die Bremsflüssigkeitsreserve aktuell, entstört, unbewertet";
CM_ SG_ 1626 BCM_Eco_Charisma_Taste "Betätigung Taster ECO alias BlueKey oder Charisma";
CM_ SG_ 1626 BCM_HDF_betaetigt "Betätigung Taster für Heckdeckelfernentriegelung in Mittelkonsole";
CM_ SG_ 1626 BCM_Hybrid_StartStopp_Taste "Betaetigung Taster 'Hybrid' oder alternativ Taster 'Start/Stopp Deaktivierung', je nach Verbau";
CM_ SG_ 1626 BCM_Hybrid_StSt_Taste_Fehler "Fehlerflag, wenn Tasterdiagnose im BCM für den StSt-Taster anschlägt.";
CM_ SG_ 1626 BCM_Kuehlmittel_Sensor "Signal der Sensorelektroden für die Kühlmittelreserve aktuell, entstört, bewertet (OK/Mangel)";
CM_ SG_ 1626 BCM_Kuehlmittel_Sensor_02 "Signal der zweiten Sensorelektroden für die Kühlmittelreserve aktuell, entstört, bewertet (OK/Mangel)";
CM_ SG_ 1626 BCM_Offroad_Taste "Betätigung der Offroad-Taste";
CM_ SG_ 1626 BCM_Waschwasser_Sensor "Signal der Sensorelektroden für die Waschwasserreserve aktuell, entstört, bewertet (OK/Mangel)";
CM_ SG_ 1626 Gong_TFL_Umschaltung "Aktivierung / Deaktivierung des TFL per Affengriff wird mit einem Gong im Kombi quittiert.";
CM_ SG_ 1626 ISP_Dimmung_ASP_02 "Dimmwertvorgabe für Aussenspiegel
Es wird 1:1 die Spannung am Innenspiegel nach außen übertragen.";
CM_ SG_ 1626 UGDO_Function_01 "UGDO_Sender = LIN-Slave BCM1
bei Kl.15 AUS wird für 4s noch der letzte Wert gesendet, danach wird der Wert 7 (= Fehler gesendet)";

CM_ SG_ 401 BMS_01_CRC "Für MLB:
'Berechnung siehe Lastenheft 'Kommunikationsabsicherung für FlexRay und CAN''

Ab MQB und MLBevo:
'Berechnung siehe Lastenheft 'End-to-End Kommunikationsabsicherung''

Endwerte siehe Begleitdokument 'S-PDU Kennungsfolgen'";
CM_ SG_ 401 BMS_IstSpannung "actual voltage of the battery / Momentanwert: Batteriespannung";
CM_ SG_ 401 BMS_IstStrom_02 "Momentanwert: Batteriestrom
Stromrichtung: ein Ladestrom wird mit positiven, ein Entladestrom mit negativen Werten angegeben";
CM_ SG_ 401 BMS_IstStrom_02_Offset "Nachkommastelle des BMS_IstStrom_02";
CM_ SG_ 401 BMS_IstStrom_02_OffsetVZ "Vorzeichen des Offsets, bzw. der Nachkommastelle";
CM_ SG_ 401 BMS_SOC_HiRes "State of Charge / aktueller Ladezustand der Batterie (höhere Auflösung)";
CM_ SG_ 401 BMS_Spannung_ZwKr "Momentanwert: 
Spannung an den Batterie-HV-Anschlüssen";

CM_ SG_ 417 BMS_MaxDyn_EntladeStrom_02 "max current (discharge)
maximal zulässiger Entladestrom (zwingend einzuhaltender Grenzwert); Wert ist für eine Dauer von 1s garantiert
";
CM_ SG_ 417 BMS_MaxDyn_LadeStrom_02 "max current (charge)
maximal zulässiger Ladestrom (zwingend einzuhaltender Grenzwert); Wert ist für eine Dauer von 1s garantiert
(Im Balancing-Mode wird über diesen Wert der Ladestrom-Sollwert angegeben)";
CM_ SG_ 417 BMS_MaxDyn_LadeStrom_02_Offset "Nachkommastelle BMS_MaxDyn_LadeStrom_02";
CM_ SG_ 417 BMS_Min_EntladeSpannung "min. voltage / minimal erlaubte Batteriespannung (zwingend einzuhaltender Grenzwert)";
CM_ SG_ 417 BMS_MinDyn_EntladeSpannung "min. voltage during discharge with current MaxDyn_EntladeStrom resp. iDisChMax / rechnerischer Wert: minimales, für eine Dauer von ~1s garantiertes Spannungsniveau, das unter Belastung mit MaxDyn_EntladeStrom bzw. iDisChMax nicht unterschritten werden wür";
CM_ SG_ 417 BMS_MinDyn_LadeSpannung "min. voltage during charge with current MaxDyn_LadeStrom resp. iChMax / rechnerischer Wert: minimales, für eine Dauer von ~1s garantiertes Spannungsniveau, das unter Belastung mit MaxDyn_LadeStrom bzw. iChMax nicht unterschritten werden würde
";

CM_ SG_ 925 BMS_Leerlaufspannung "Leerlaufspannung der Gesamtbatterie, Open Circuit Voltage of the battery system";
CM_ SG_ 925 BMS_Max_LadeSpannung "max. voltage / maximal erlaubte Batteriespannung (zwingend einzuhaltender Grenzwert)";
CM_ SG_ 925 BMS_MaxPred_EntladeStrom_02 "dynamic el. limit, max. current (discharge) for the specified time (e.g. 10s): and the voltage limit (only for prediction)
rechnerischer Wert: quasistationärer, für eine Dauer von z.B. 10s garantierter maximaler Entladestrom";
CM_ SG_ 925 BMS_MaxPred_LadeStrom_02 "dynamic el. limit, max. current (charge) for the specified time (e.g. 10s), and the voltage limit (only for prediction) 
rechnerischer Wert: quasistationärer, für eine Dauer von z.B. 10s garantierter maximaler Ladestrom
EV / PlugIn:
externes Laden (BMS";
CM_ SG_ 925 BMS_MinPred_EntladeSpannung "static el. limit, min. battery voltage (~10s) during current MaxPred_EntladeStrom resp iDisChPredMax / rechnerischer Wert: minimales, für eine Dauer von 10s garantiertes Spannungsniveau, das unter Belastung mit MaxPred_EntladeStrom bzw. iDisChPredMax nich";
CM_ SG_ 925 BMS_MinPred_LadeSpannung "static el. limit, min. battery voltage (~10s) during current MaxPred_LadeStrom resp. iChPredMax / rechnerischer Wert: minimales, für eine Dauer von ~10s garantiertes Spannungsniveau, das unter Belastung mit MaxPred_LadeStrom bzw. iChPredMax nicht untersch";

CM_ SG_ 1442 BMS_04_CRC "Für MLB:
'Berechnung siehe Lastenheft 'Kommunikationsabsicherung für FlexRay und CAN''

Ab MQB und MLBevo:
'Berechnung siehe Lastenheft 'End-to-End Kommunikationsabsicherung''

Endwerte siehe Begleitdokument 'S-PDU Kennungsfolgen'";
CM_ SG_ 1442 BMS_Abschaltankuendigung "Zeitliche Ankündigung einer Abschaltung der HV Batterie.";
CM_ SG_ 1442 BMS_Fehlerstatus "aktueller Fehlerstatus der Batterie";
CM_ SG_ 1442 BMS_IstModus "Aktueller Betriebsmodus der Batterie
0: Standby; Schuetze geoeffnet; Kommunikation aktiv
1: Hauptschuetze geschlossen / HV-Netz aktiviert / normaler Fahrbetrieb
2: projektabhaengig belegt (z.B. Balancing, erweitertes DC-Schnelladen)
3: externes Laden ";
CM_ SG_ 1442 BMS_Kapazitaet_02 "Nutzbare Kapazität der Batterie,
oder alterungsabhängige absolute Gesamtkapazität der Batterie.

Projektabhängig kann die Kapazität auf das nutzbare SOC-Fenster (zwischen oberer und unterer SOC-Grenze) bezogen sein, wobei sich dieses SOC-Fenster alteru";
CM_ SG_ 1442 BMS_OBD_Lampe_Anf "Anforderung MIL (MalfunctionIndicationLamp) von BMS (Motorsteuergerät reicht diese Info an Kombi weiter).";
CM_ SG_ 1442 BMS_Soll_SOC_HiRes "Der Sollwert für den HV-Batterie-SOC bei einer SOC-steuernden Betriebsstrategie";
CM_ SG_ 1442 BMS_Status_ServiceDisconnect "Status des Service Disconnect, ob dieser gesteckt oder gezogen ist.
Abhängigkeiten zu anderen Signalen: BMS_Fehler_Sicherung und BMS_Fehler_Pilot";
CM_ SG_ 1442 BMS_Status_Spgfreiheit "0=Init (ohne Funktion)
1=BMS Zwischenkreis spannungsfrei (U_Zwkr < 20V)
2=BMS Zwischenkreis nicht spannungsfrei (U_Zwkr >/= 25V, Hysterese)
3=Fehler (z.B. Fehler in der Sensorik)";

CM_ SG_ 687 BMS_As_Entladezaehler "Signal zur Berechnung des Lastprofils durch die RWB";
CM_ SG_ 687 BMS_As_Entladezaehler_Ueberlauf "Wird beim ersten Überlauf von BMS_As_Entladezahler auf 1 gesetzt. Reset über KL15-Wechsel";
CM_ SG_ 687 BMS_Rekuperation "Zähler: Anzeigesignal: Energiezufuhr in die HV-Batterie (Reku). Darf nicht durch Laden der Batterie bedatet werden";
CM_ SG_ 687 BMS_Rekuperation_Ueberlauf "Rekuperationleistungssignal BMS_Rekuperation mindest 1x übergelaufen";
CM_ SG_ 687 BMS_Verbrauch "Zähler: Energieentnahme aus der HV-Batterie";
CM_ SG_ 687 BMS_Verbrauch_Ueberlauf "Verbrauchssignal mindest 1x übergelaufen";

CM_ SG_ 1438 BMS_Batterie_Voko_Anf "Anforderung des BMC die Bauteilvorkonditionierung der HV-Batterie durchzuführen.";
CM_ SG_ 1438 BMS_Fehler_NTKreis "Fehler im NTKreis, HV-Batterie wird nicht klimatisiert
(Fehler, Fehlerfrei) ";
CM_ SG_ 1438 BMS_Fehlerstatus_EWP_02 "Fehlerstatus der elektrischen Wasserpumpe der HV-Batterie";
CM_ SG_ 1438 BMS_IstRuecklaufTemperatur_02 "Aktuelle Ruecklauftemperatur der Batterie";
CM_ SG_ 1438 BMS_IstVorlaufTemperatur "Aktuelle Vorlauftemperatur der Batterie";
CM_ SG_ 1438 BMS_Soll_PWM_Pumpe "Ansteuerungs-Sollwert der Batterie-Kühlmittelpumpe. 
Speziell im MQB PHEV: Istwert der Pumpenansteuerung (Batterie steuert Pumpe selbständig an).";
CM_ SG_ 1438 BMS_SollVolumenstrom "Soll Volumenstrom für Kühlkreislauf Batterie";
CM_ SG_ 1438 BMS_SollVorlauftemperatur "Soll_Vorlauftemperatur_Kühlmedium in °C";
CM_ SG_ 1438 BMS_Status_Ventil "Status des 3-2-Wege-Ventils (betätigt/unbetätigt/Fehler)";
CM_ SG_ 1438 BMS_Temp_Epsilon "Das Signal beschreibt die Differenz zwischen Batterie Soll-Temperatur und Batterie Ist-Temperatur.";
CM_ SG_ 1438 BMS_Temperatur "battery temperature / Momentanwert: Temperatur der Traktionsbatterie";
CM_ SG_ 1438 BMS_Temperierung_Anf "Temperierungsbedarf der HV-Batterie";

CM_ SG_ 1482 BMS_07_CRC "Für MLB:
'Berechnung siehe Lastenheft 'Kommunikationsabsicherung für FlexRay und CAN''

Ab MQB und MLBevo:
'Berechnung siehe Lastenheft 'End-to-End Kommunikationsabsicherung''

Endwerte siehe Begleitdokument 'S-PDU Kennungsfolgen'";
CM_ SG_ 1482 BMS_Ausgleichsladung_Anf "BMS wünscht eine Ausgleichsladung
Flag derzeit ungenutzt, da BalancingModus im Detail noch nicht geklärt.";
CM_ SG_ 1482 BMS_Balancing_Aktiv "Signal zeigt an, ob mindestens eine Zelle der HV Batterie balanciert wird";
CM_ SG_ 1482 BMS_Batteriediagnose "Anzeige von Textwarnungen";
CM_ SG_ 1482 BMS_Energieinhalt "aktuell nutzbarer Energieinhalt der HV-Batterie
(bezogen auf ein definiertes mittleres Belastungsprofil)";
CM_ SG_ 1482 BMS_Fehler_KuehlkreislaufLeckage "Bei einer Leckage im Kühlkreislauf wird dieser Fehler gesetzt.";
CM_ SG_ 1482 BMS_Freig_max_Performanz "Freigabe der Komponente, dass eine maximale Leistung zur Verfügung gestellt werden kann.";
CM_ SG_ 1482 BMS_Gesamtst_Spgfreiheit "0 = Funktion nicht aktiviert
1 = HV-System spannungsfrei (U_Zwkr von BMS, LE und Ladegerät < 20V, DCLadestecker nicht gesteckt und Service Disconnect entriegelt)
2 = HV-System nicht spannungsfrei (U_Zwkr von BMS, LE und Ladegerät >= 20V, Ladestecker ges";
CM_ SG_ 1482 BMS_KundenWarnung "Kunden Warnung aufgrund eines Batteriefehlers";
CM_ SG_ 1482 BMS_Ladevorgang_aktiv "Signalisiert aktiven Ladevorgang, Ladegerät und DC/DC aktiv.
Signal bleibt nach Kl.15 ein aktiv, bis ESP_Stillstandsflag gelöscht.

Abhängigkeit zu BMS_Energieinhalt";
CM_ SG_ 1482 BMS_MaxEnergieinhalt "maximaler nutzbarer Energieinhalt der HV-Batterie (bezogen auf Last KBI_RWDS_Lastprofil bei SOC=100%)
Abhängig von KBI_RWDS_Lastprofil";
CM_ SG_ 1482 BMS_RIso_Ext "Minimum des Isolationswiderstands zwischen Batteriegehäuse und HV+ bzw. Batteriegehäuse und HV- bei geschlossenen Schützen (externe Iso Messung)";

CM_ SG_ 2527679979 BMS_BCCM_Anforderung "Signal zum HVLM zur Aktivierung BCCM aufgrund Grenzwertüberschreitung Standzeitzähler";
CM_ SG_ 2527679979 BMS_HV_Auszeit "Zeit seit letzter Hochvoltaktivität.";
CM_ SG_ 2527679979 BMS_HV_Auszeit_Status "Status HV-Auszeit.";
CM_ SG_ 2527679979 BMS_Kapazitaet "Gesamtenergiekapazitaet der HV-Batterie unter Berücksichtigung der Alterung";
CM_ SG_ 2527679979 BMS_max_Grenz_SOC "oberer Grenz SOC - Betriebsstrategie";
CM_ SG_ 2527679979 BMS_min_Grenz_SOC "unterer Grenz SOC - Betriebsstrategie";
CM_ SG_ 2527679979 BMS_SOC_Kaltstart "Abhängig von der notwendigen Kaltstartleistung berechneter SOC Wert.";

CM_ SG_ 1289 BMS_Energieinhalt_HiRes "aktuell nutzbarer Energieinhalt der HV-Batterie
(bezogen auf ein definiertes mittleres Belastungsprofil)";
CM_ SG_ 1289 BMS_MaxEnergieinhalt_HiRes "maximal nutzbarer Energieinhalt der HV-Batterie
(bezogen auf ein definiertes mittleres Belastungsprofil)";
CM_ SG_ 1289 BMS_NutzbarerEnergieinhalt "Restenergieinhalt der Traktionsbatterie, bezogen auf die Betriebsstrategiegrenzen";
CM_ SG_ 1289 BMS_NutzbarerSOC "Aktueller relativer Ladezustand der HV-Batterie";
CM_ SG_ 1289 BMS_Pred_Entladeperformance "Indikator Stromintegral in Entladerichtung. 
0%     = Start abrampen Peak-Entladestromgrenze auf Dauer-Entladestromgrenze.
100% = Voller Peak-Entladestrom verfügbar";
CM_ SG_ 1289 BMS_Pred_Ladeperformance "Indikator Stromintegral in Laderichtung. 
0%     = Start abrampen Peak-Ladestromgrenze auf Dauer-Ladestromgrenze.
100% = Voller Peak-Ladestrom verfügbar";

CM_ SG_ 2527679654 BMS_IsoFehler "Ergebnis der Isolationsmessung des BMS";
CM_ SG_ 2527679654 BMS_IsoZustand "Ergebnis des aktuellen/letzten Isolations-Meßzyklus: Messung läuft; Messung Batterie-intern oder Gesamtsystem; gemessener Wert unterschreitet Schwelle 1 / Schwelle 2.";
CM_ SG_ 2527679654 BMS_IstTemperatur_hoechste "aktuell höchste Temperatur in der Batterie";
CM_ SG_ 2527679654 BMS_IstTemperatur_niedrigste "aktuell niedrigsteTemperatur in der Batterie";
CM_ SG_ 2527679654 BMS_IstZellspannung_hoechste "höchster Wert aller Zellspannungen im BMS";
CM_ SG_ 2527679654 BMS_IstZellspannung_niedrigste "niedrigster Wert aller Zellspannungen im BMS";

CM_ SG_ 2589283637 BMS_Pack_SN_01 "Seriennummer der HV Batterie, Byte 1, ASCII Codierung";
CM_ SG_ 2589283637 BMS_Pack_SN_02 "Seriennummer der HV Batterie, Byte 2, ASCII Codierung";
CM_ SG_ 2589283637 BMS_Pack_SN_03 "Seriennummer der HV Batterie, Byte 3, ASCII Codierung";
CM_ SG_ 2589283637 BMS_Pack_SN_04 "Seriennummer der HV Batterie, Byte 4, ASCII Codierung";
CM_ SG_ 2589283637 BMS_Pack_SN_05 "Seriennummer der HV Batterie, Byte 5, ASCII Codierung";
CM_ SG_ 2589283637 BMS_Pack_SN_06 "Seriennummer der HV Batterie, Byte 6, ASCII Codierung";
CM_ SG_ 2589283637 BMS_Pack_SN_07 "Seriennummer der HV Batterie, Byte 7, ASCII Codierung";
CM_ SG_ 2589283637 BMS_Pack_SN_08 "Seriennummer der HV Batterie, Byte 8, ASCII Codierung";

CM_ SG_ 2589283638 BMS_Pack_SN_09 "Seriennummer der HV Batterie, Byte 9, ASCII Codierung";
CM_ SG_ 2589283638 BMS_Pack_SN_10 "Seriennummer der HV Batterie, Byte 10, ASCII Codierung";
CM_ SG_ 2589283638 BMS_Pack_SN_11 "Seriennummer der HV Batterie, Byte 11, ASCII Codierung";
CM_ SG_ 2589283638 BMS_Pack_SN_12 "Seriennummer der HV Batterie, Byte 12, ASCII Codierung";
CM_ SG_ 2589283638 BMS_Pack_SN_13 "Seriennummer der HV Batterie, Byte 13, ASCII Codierung";
CM_ SG_ 2589283638 BMS_Pack_SN_14 "Seriennummer der HV Batterie, Byte 14, ASCII Codierung";
CM_ SG_ 2589283638 BMS_Pack_SN_15 "Seriennummer der HV Batterie, Byte 15, ASCII Codierung";
CM_ SG_ 2589283638 BMS_Pack_SN_16 "Seriennummer der HV Batterie, Byte 16, ASCII Codierung";

CM_ SG_ 1111 BMS_14_BZ "4bit Botschaftszähler, wird mit jeder Sendebotschaft inkrementiert";
CM_ SG_ 1111 BMS_14_CRC "Für MLB:
Berechnung siehe Lastenheft 'Kommunikationsabsicherung für FlexRay und CAN'
Ab MQB und MLBevo:
Berechnung siehe Lastenheft 'End-to-End Kommunikationsabsicherung'

Endwerte siehe Begleitdokument 'S-PDU Kennungsfolgen'";
CM_ SG_ 1111 BMS_RIso_GND_HVM "Iso-Widerstand
negative Werte = Isowiderstand GND zu HV-
Nur relevant für Fahrzeuge (z.B. PO513/xxx_B) mit HV-Ladebooster (DCDC_HV_02)";
CM_ SG_ 1111 BMS_RIso_GND_HVP "Iso-Widerstand
positive Werte = Isowiderstand GND zu HV+
Nur relevant für Fahrzeuge (z.B. PO513/xxx_B) mit HV-Ladebooster (DCDC_HV_02)";
CM_ SG_ 1111 BMS_Spannung_ZwKr2 "Momentanwert: 
Zweite Zwischenkreisspannung für Batterien mit zwei HV Abgaengen (zwei HV Kreise)
MLBevo PAG:
BMS_Spannung_ZwKr    vordere LE
BMS_Spannung_ZwKr2  hintere LE";
CM_ SG_ 1111 BMS_Warnung_Stuetzung_NV "Warnung an das Energiemanagement zur Verfügbarkeit der sicherheitsrelevanten NV-Stützung.

Bei Stuetzung_iO kann die HV-Batterie zum aktuellen Zeitpunkt für die vorgegebene Dauer die notwendige Leistung/Energie zur Stützung des NV-Systems zur Verfügung ";

CM_ SG_ 2589283877 BMS_Pack_SN_17 "Seriennummer der HV Batterie, Byte 17, ASCII Codierung";
CM_ SG_ 2589283877 BMS_Pack_SN_18 "Seriennummer der HV Batterie, Byte 18, ASCII Codierung";
CM_ SG_ 2589283877 BMS_Pack_SN_19 "Seriennummer der HV Batterie, Byte 19, ASCII Codierung";
CM_ SG_ 2589283877 BMS_Pack_SN_20 "Seriennummer der HV Batterie, Byte 20, ASCII Codierung";
CM_ SG_ 2589283877 BMS_Pack_SN_21 "Seriennummer der HV Batterie, Byte 21, ASCII Codierung";
CM_ SG_ 2589283877 BMS_Pack_SN_22 "Seriennummer der HV Batterie, Byte 22, ASCII Codierung";
CM_ SG_ 2589283877 BMS_Pack_SN_23 "Seriennummer der HV Batterie, Byte 23, ASCII Codierung";
CM_ SG_ 2589283877 BMS_Pack_SN_24 "Seriennummer der HV Batterie, Byte 24, ASCII Codierung";

CM_ SG_ 2589283641 BMS_IstTemperaturMax_Modul_ID "RTM-Signal: Nummer (ID) des Moduls mit dem aktuell höchsten Temperaturmeßwert";
CM_ SG_ 2589283641 BMS_IstTemperaturMax_Sensor_ID "RTM-Signal: Nummer (ID) des Sensors (innerhalb des Moduls) mit dem aktuell höchsten Temperaturmeßwert";
CM_ SG_ 2589283641 BMS_IstTemperaturMin_Modul_ID "RTM-Signal: Nummer (ID) des Moduls mit dem aktuell niedrigsten Temperaturmeßwert";
CM_ SG_ 2589283641 BMS_IstTemperaturMin_Sensor_ID "RTM-Signal: Nummer (ID) des Sensors (innerhalb des Moduls) mit dem aktuell niedrigsten Temperaturmeßwert";
CM_ SG_ 2589283641 BMS_IstZellSpannungMax_Modul_ID "RTM-Signal: Nummer (ID) des Moduls mit der aktuell höchsten Zellspannung";
CM_ SG_ 2589283641 BMS_IstZellSpannungMax_Zell_ID "RTM-Signal: Nummer (ID) der Zelle (innerhalb des Moduls) mit der aktuell höchsten Zellspannung";
CM_ SG_ 2589283641 BMS_IstZellSpannungMin_Modul_ID "RTM-Signal: Nummer (ID) des Moduls mit der aktuell niedrigsten Zellspannung";
CM_ SG_ 2589283641 BMS_IstZellSpannungMin_Zell_ID "RTM-Signal: Nummer (ID) der Zelle (innerhalb des Moduls) mit der aktuell niedrigsten Zellspannung";

CM_ SG_ 2589283651 BMS_RtmWarnBattUnautorisiert "RTM Signal battery unmatch warning";
CM_ SG_ 2589283651 BMS_RtmWarnPackKommunikation "Real Time Monitor Traction battery CAN communication fault";
CM_ SG_ 2589283651 BMS_RtmWarnPackUeberladen "RTM Signal Energy-storage over-charging warning";
CM_ SG_ 2589283651 BMS_RtmWarnSocHoch "RTM Signal Excessively-high SOC warning";
CM_ SG_ 2589283651 BMS_RtmWarnSocNiedrig "RTM Signal Low SOC warning";
CM_ SG_ 2589283651 BMS_RtmWarnSocSprung "RTM Signal SOC jump warning";
CM_ SG_ 2589283651 BMS_RtmWarnTZelleDiff "RTM Signal Temperature difference warning";
CM_ SG_ 2589283651 BMS_RtmWarnTZelleMax "RTM Signal Max_temperature_cell_Warning";
CM_ SG_ 2589283651 BMS_RtmWarnTZelleMin "RTM Signal Min_temperature_cell_Warning";
CM_ SG_ 2589283651 BMS_RtmWarnUeberstrom "Real Time Monitor Over-current of overall current of traction battery";
CM_ SG_ 2589283651 BMS_RtmWarnUPackMax "RTM Signal Max_Voltage_of_battery_Warning";
CM_ SG_ 2589283651 BMS_RtmWarnUPackMin "RTM Signal Min_Voltage_of_battery_Warning";
CM_ SG_ 2589283651 BMS_RtmWarnUZelleMax "RTM Signal Max_voltage_cell_Warning";
CM_ SG_ 2589283651 BMS_RtmWarnUZelleMin "RTM Signal Min_voltage_cell_Warning";
CM_ SG_ 2589283651 BMS_RtmWarnZelleZustand "RTM Signal Cell poor-consistency warning";

CM_ SG_ 2589283652 BMS_18_BZ "4bit Botschaftszähler, wird mit jeder Sendebotschaft inkrementiert";
CM_ SG_ 2589283652 BMS_18_CRC "Für MLB:
Berechnung siehe Lastenheft 'Kommunikationsabsicherung für FlexRay und CAN'
Ab MQB und MLBevo:
Berechnung siehe Lastenheft 'End-to-End Kommunikationsabsicherung'

Endwerte siehe Begleitdokument 'S-PDU Kennungsfolgen'";
CM_ SG_ 2589283652 BMS_Energie_Entladung "Energie, welche seit dem letzten Fahrzyklus aus der HV-Batterie entnommen wurde.";
CM_ SG_ 2589283652 BMS_Energie_Ladung "Energie, welche seit dem letzten Fahrzyklus in die HV-Batterie geladen wurde.";
CM_ SG_ 2589283652 BMS_Variante_Lambo "Information to HVK of a specific Lamborghini PHEV configuration";

CM_ SG_ 2589283878 BMS_Pack_SN_25 "Seriennummer der HV Batterie, Byte 25, ASCII Codierung";
CM_ SG_ 2589283878 BMS_Pack_SN_26 "Seriennummer der HV Batterie, Byte 26, ASCII Codierung";

CM_ SG_ 2589283666 BMS_EnergieAntw_Energie "Für Laden der HV-Batterie notwendige Energie (um angefragten SOC-Hub zu erreichen).";
CM_ SG_ 2589283666 BMS_EnergieAntw_Zaehler "Fortlaufender Zähler für die Antwort Energie.";
CM_ SG_ 2589283666 BMS_LadegrenzeAntw_Leistung "Ladeleistung mit welcher bis zu SOC aus BMS_LadegrenzeAntw_SOC geladen werden kann.";
CM_ SG_ 2589283666 BMS_LadegrenzeAntw_SOC "SOC-Grenze bis zu welcher mit der Leistung aus BMS_LadegrenzeAntw_Leistung geladen werden kann.";
CM_ SG_ 2589283666 BMS_LadegrenzeAntw_Zaehler "Fortlaufender Zähler für die Antwort Leistung.";
CM_ SG_ 2589283666 BMS_MMTR_Status "Status der HVB zur Funktion Make me track ready";

CM_ SG_ 2463978763 BMS_30_BZ "4bit Botschaftszähler, wird mit jeder Sendebotschaft inkrementiert";
CM_ SG_ 2463978763 BMS_30_CRC "Für MLB:
Berechnung siehe Lastenheft 'Kommunikationsabsicherung für FlexRay und CAN'
Ab MQB und MLBevo:
Berechnung siehe Lastenheft 'End-to-End Kommunikationsabsicherung'

Endwerte siehe Begleitdokument 'S-PDU Kennungsfolgen'";
CM_ SG_ 2463978763 BMS_Ueberspannung_Zelle "Anforderung Notabschaltung an HVK aufgrund Überladung";

CM_ SG_ 2463978838 BMS_NutzbarerEnergieinhalt_HiRes "Restenergieinhalt der Traktionsbatterie, bezogen auf die Betriebsstrategiegrenzen";
CM_ SG_ 2463978838 BMS_ZellTemp_virtuell_max "Maximaler Wert der Zelltemperatur der HVB, Berechnung über Thermomodell";
CM_ SG_ 2463978838 BMS_ZellTemp_virtuell_min "Minimaler Wert der Zelltemperatur der HVB, Berechnung über Thermomodell";

CM_ SG_ 2589283895 BMS_EnergieAntw_Energie_02 "Für Laden der HV-Batterie notwendige Energie (um angefragten SOC-Hub zu erreichen). (neues Signal mit erhöhter Auflösung)";
CM_ SG_ 2589283895 BMS_EnergieAntw_Zaehler_02 "Fortlaufender Zähler für die Antwort Energie. (Für den neuen BMS-Handshake mit höherer Auflösung)";
CM_ SG_ 2589283895 BMS_LadegrenzeAntw_Leistung_02 "Ladeleistung mit welcher bis zu SOC aus BMS_LadegrenzeAntw_SOC geladen werden kann. (Für den neuen BMS-Handshake mit höherer Auflösung)";
CM_ SG_ 2589283895 BMS_LadegrenzeAntw_SOC_02 "SOC-Grenze bis zu welcher mit der Leistung aus BMS_LadegrenzeAntw_Leistung geladen werden kann. (neues Signal mit erhöhter Auflösung)";
CM_ SG_ 2589283895 BMS_LadegrenzeAntw_Zaehler_02 "Fortlaufender Zähler für die Antwort Leistung. (Für den neuen BMS-Handshake mit höherer Auflösung)";
CM_ SG_ 2589283895 BMS_NutzbarerSOC_02 "Aktueller relativer Ladezustand der HV-Batterie. (Kunden-SOC mit erhöhter Auflösung)";

CM_ SG_ 2589284070 BMS_ExtLadeleistung "Prognostizierte Ladeleistung während er Fahrt und im Stand die bei der aktuellen HVB-Temperatur und aktuellem SOC theoretisch maximal möglich ist.";

CM_ SG_ 2589284007 BMS_48V_CALID_CVN_MUX "Alle CALID-Indizes bilden zusammen die CALID";
CM_ SG_ 2589284007 BMS_48V_CALID_Index_01 "Software-Calibration-Identification (CALID) im ASCII-Zeichenformat; 
für Ausgabe an das Generic Scan-Tool für OBD in NAR

0x30 entspricht ASCII '0'";
CM_ SG_ 2589284007 BMS_48V_CALID_Index_02 "Software-Calibration-Identification (CALID) im ASCII-Zeichenformat; 
für Ausgabe an das Generic Scan-Tool für OBD in NAR

0x30 entspricht ASCII '0'";
CM_ SG_ 2589284007 BMS_48V_CALID_Index_03 "Software-Calibration-Identification (CALID) im ASCII-Zeichenformat; 
für Ausgabe an das Generic Scan-Tool für OBD in NAR

0x30 entspricht ASCII '0'";
CM_ SG_ 2589284007 BMS_48V_CALID_Index_04 "Software-Calibration-Identification (CALID) im ASCII-Zeichenformat; 
für Ausgabe an das Generic Scan-Tool für OBD in NAR

0x30 entspricht ASCII '0'";
CM_ SG_ 2589284007 BMS_48V_CALID_Index_05 "Software-Calibration-Identification (CALID) im ASCII-Zeichenformat; 
für Ausgabe an das Generic Scan-Tool für OBD in NAR

0x30 entspricht ASCII '0'";
CM_ SG_ 2589284007 BMS_48V_CALID_Index_06 "Software-Calibration-Identification (CALID) im ASCII-Zeichenformat; 
für Ausgabe an das Generic Scan-Tool für OBD in NAR

0x30 entspricht ASCII '0'";
CM_ SG_ 2589284007 BMS_48V_CALID_Index_07 "Software-Calibration-Identification (CALID) im ASCII-Zeichenformat; 
für Ausgabe an das Generic Scan-Tool für OBD in NAR

0x30 entspricht ASCII '0'";
CM_ SG_ 2589284007 BMS_48V_CALID_Index_08 "Software-Calibration-Identification (CALID) im ASCII-Zeichenformat; 
für Ausgabe an das Generic Scan-Tool für OBD in NAR

0x30 entspricht ASCII '0'";
CM_ SG_ 2589284007 BMS_48V_CALID_Index_09 "Software-Calibration-Identification (CALID) im ASCII-Zeichenformat; 
für Ausgabe an das Generic Scan-Tool für OBD in NAR

0x30 entspricht ASCII '0'";
CM_ SG_ 2589284007 BMS_48V_CALID_Index_10 "Software-Calibration-Identification (CALID) im ASCII-Zeichenformat; 
für Ausgabe an das Generic Scan-Tool für OBD in NAR

0x30 entspricht ASCII '0'";
CM_ SG_ 2589284007 BMS_48V_CALID_Index_11 "Software-Calibration-Identification (CALID) im ASCII-Zeichenformat; 
für Ausgabe an das Generic Scan-Tool für OBD in NAR

0x30 entspricht ASCII '0'";
CM_ SG_ 2589284007 BMS_48V_CALID_Index_12 "Software-Calibration-Identification (CALID) im ASCII-Zeichenformat; 
für Ausgabe an das Generic Scan-Tool für OBD in NAR

0x30 entspricht ASCII '0'";
CM_ SG_ 2589284007 BMS_48V_CALID_Index_13 "Software-Calibration-Identification (CALID) im ASCII-Zeichenformat; 
für Ausgabe an das Generic Scan-Tool für OBD in NAR

0x30 entspricht ASCII '0'";
CM_ SG_ 2589284007 BMS_48V_CALID_Index_14 "Software-Calibration-Identification (CALID) im ASCII-Zeichenformat; 
für Ausgabe an das Generic Scan-Tool für OBD in NAR

0x30 entspricht ASCII '0'";
CM_ SG_ 2589284007 BMS_48V_CALID_Index_15 "Software-Calibration-Identification (CALID) im ASCII-Zeichenformat; 
für Ausgabe an das Generic Scan-Tool für OBD in NAR

0x30 entspricht ASCII '0'";
CM_ SG_ 2589284007 BMS_48V_CALID_Index_16 "Software-Calibration-Identification (CALID) im ASCII-Zeichenformat; 
für Ausgabe an das Generic Scan-Tool für OBD in NAR

0x30 entspricht ASCII '0'";
CM_ SG_ 2589284007 BMS_48V_CVN_Byte_1 "Calibration Verification Number (CVN bzw. Checksumme) des SW- und Datenstandes; 
für Ausgabe an das Generic Scan-Tool für OBD in NAR";
CM_ SG_ 2589284007 BMS_48V_CVN_Byte_2 "Calibration Verification Number (CVN bzw. Checksumme) des SW- und Datenstandes; 
für Ausgabe an das Generic Scan-Tool für OBD in NAR";
CM_ SG_ 2589284007 BMS_48V_CVN_Byte_3 "Calibration Verification Number (CVN bzw. Checksumme) des SW- und Datenstandes; 
für Ausgabe an das Generic Scan-Tool für OBD in NAR";
CM_ SG_ 2589284007 BMS_48V_CVN_Byte_4 "Calibration Verification Number (CVN bzw. Checksumme) des SW- und Datenstandes; 
für Ausgabe an das Generic Scan-Tool für OBD in NAR";
CM_ SG_ 2589284007 BMS_48V_CVN_VLD "Valid-Bit der Calibration-Verification-Number (CVN bzw. Checksumme)";

CM_ SG_ 2589284008 BMS_48V_Komponentenfehler_01 "Übertragung OBD relevanter Fehlerpfade vom Secondary zum Primary Steuergerät. 
Zuordnung der generischen Komponentenfehler muss zwischen Sender und Empfänger abgestimmt werden.";
CM_ SG_ 2589284008 BMS_48V_Komponentenfehler_02 "Übertragung OBD relevanter Fehlerpfade vom Secondary zum Primary Steuergerät. 
Zuordnung der generischen Komponentenfehler muss zwischen Sender und Empfänger abgestimmt werden.";
CM_ SG_ 2589284008 BMS_48V_Komponentenfehler_03 "Übertragung OBD relevanter Fehlerpfade vom Secondary zum Primary Steuergerät. 
Zuordnung der generischen Komponentenfehler muss zwischen Sender und Empfänger abgestimmt werden.";
CM_ SG_ 2589284008 BMS_48V_Komponentenfehler_04 "Übertragung OBD relevanter Fehlerpfade vom Secondary zum Primary Steuergerät. 
Zuordnung der generischen Komponentenfehler muss zwischen Sender und Empfänger abgestimmt werden.";
CM_ SG_ 2589284008 BMS_48V_Komponentenfehler_05 "Übertragung OBD relevanter Fehlerpfade vom Secondary zum Primary Steuergerät. 
Zuordnung der generischen Komponentenfehler muss zwischen Sender und Empfänger abgestimmt werden.";
CM_ SG_ 2589284008 BMS_48V_Komponentenfehler_06 "Übertragung OBD relevanter Fehlerpfade vom Secondary zum Primary Steuergerät. 
Zuordnung der generischen Komponentenfehler muss zwischen Sender und Empfänger abgestimmt werden.";
CM_ SG_ 2589284008 BMS_48V_Komponentenfehler_07 "Übertragung OBD relevanter Fehlerpfade vom Secondary zum Primary Steuergerät. 
Zuordnung der generischen Komponentenfehler muss zwischen Sender und Empfänger abgestimmt werden.";
CM_ SG_ 2589284008 BMS_48V_Komponentenfehler_08 "Übertragung OBD relevanter Fehlerpfade vom Secondary zum Primary Steuergerät. 
Zuordnung der generischen Komponentenfehler muss zwischen Sender und Empfänger abgestimmt werden.";
CM_ SG_ 2589284008 BMS_48V_Komponentenfehler_09 "Übertragung OBD relevanter Fehlerpfade vom Secondary zum Primary Steuergerät. 
Zuordnung der generischen Komponentenfehler muss zwischen Sender und Empfänger abgestimmt werden.";
CM_ SG_ 2589284008 BMS_48V_Komponentenfehler_10 "Übertragung OBD relevanter Fehlerpfade vom Secondary zum Primary Steuergerät. 
Zuordnung der generischen Komponentenfehler muss zwischen Sender und Empfänger abgestimmt werden.";
CM_ SG_ 2589284008 BMS_48V_Komponentenfehler_11 "Übertragung OBD relevanter Fehlerpfade vom Secondary zum Primary Steuergerät. 
Zuordnung der generischen Komponentenfehler muss zwischen Sender und Empfänger abgestimmt werden.";
CM_ SG_ 2589284008 BMS_48V_Komponentenfehler_12 "Übertragung OBD relevanter Fehlerpfade vom Secondary zum Primary Steuergerät. 
Zuordnung der generischen Komponentenfehler muss zwischen Sender und Empfänger abgestimmt werden.";
CM_ SG_ 2589284008 BMS_48V_Komponentenfehler_13 "Übertragung OBD relevanter Fehlerpfade vom Secondary zum Primary Steuergerät. 
Zuordnung der generischen Komponentenfehler muss zwischen Sender und Empfänger abgestimmt werden.";
CM_ SG_ 2589284008 BMS_48V_Komponentenfehler_14 "Übertragung OBD relevanter Fehlerpfade vom Secondary zum Primary Steuergerät. 
Zuordnung der generischen Komponentenfehler muss zwischen Sender und Empfänger abgestimmt werden.";
CM_ SG_ 2589284008 BMS_48V_Komponentenfehler_15 "Übertragung OBD relevanter Fehlerpfade vom Secondary zum Primary Steuergerät. 
Zuordnung der generischen Komponentenfehler muss zwischen Sender und Empfänger abgestimmt werden.";
CM_ SG_ 2589284008 BMS_48V_Komponentenfehler_16 "Übertragung OBD relevanter Fehlerpfade vom Secondary zum Primary Steuergerät. 
Zuordnung der generischen Komponentenfehler muss zwischen Sender und Empfänger abgestimmt werden.";
CM_ SG_ 2589284008 BMS_48V_Komponentenfehler_17 "Übertragung OBD relevanter Fehlerpfade vom Secondary zum Primary Steuergerät. 
Zuordnung der generischen Komponentenfehler muss zwischen Sender und Empfänger abgestimmt werden.";
CM_ SG_ 2589284008 BMS_48V_Komponentenfehler_18 "Übertragung OBD relevanter Fehlerpfade vom Secondary zum Primary Steuergerät. 
Zuordnung der generischen Komponentenfehler muss zwischen Sender und Empfänger abgestimmt werden.";
CM_ SG_ 2589284008 BMS_48V_Komponentenfehler_19 "Übertragung OBD relevanter Fehlerpfade vom Secondary zum Primary Steuergerät. 
Zuordnung der generischen Komponentenfehler muss zwischen Sender und Empfänger abgestimmt werden.";
CM_ SG_ 2589284008 BMS_48V_Komponentenfehler_20 "Übertragung OBD relevanter Fehlerpfade vom Secondary zum Primary Steuergerät. 
Zuordnung der generischen Komponentenfehler muss zwischen Sender und Empfänger abgestimmt werden.";
CM_ SG_ 2589284008 BMS_48V_Komponentenfehler_21 "Übertragung OBD relevanter Fehlerpfade vom Secondary zum Primary Steuergerät. 
Zuordnung der generischen Komponentenfehler muss zwischen Sender und Empfänger abgestimmt werden.";
CM_ SG_ 2589284008 BMS_48V_Komponentenfehler_22 "Übertragung OBD relevanter Fehlerpfade vom Secondary zum Primary Steuergerät. 
Zuordnung der generischen Komponentenfehler muss zwischen Sender und Empfänger abgestimmt werden.";
CM_ SG_ 2589284008 BMS_48V_Komponentenfehler_23 "Übertragung OBD relevanter Fehlerpfade vom Secondary zum Primary Steuergerät. 
Zuordnung der generischen Komponentenfehler muss zwischen Sender und Empfänger abgestimmt werden.";
CM_ SG_ 2589284008 BMS_48V_Komponentenfehler_24 "Übertragung OBD relevanter Fehlerpfade vom Secondary zum Primary Steuergerät. 
Zuordnung der generischen Komponentenfehler muss zwischen Sender und Empfänger abgestimmt werden.";
CM_ SG_ 2589284008 BMS_48V_Komponentenfehler_25 "Übertragung OBD relevanter Fehlerpfade vom Secondary zum Primary Steuergerät. 
Zuordnung der generischen Komponentenfehler muss zwischen Sender und Empfänger abgestimmt werden.";
CM_ SG_ 2589284008 BMS_48V_Komponentenfehler_26 "Übertragung OBD relevanter Fehlerpfade vom Secondary zum Primary Steuergerät. 
Zuordnung der generischen Komponentenfehler muss zwischen Sender und Empfänger abgestimmt werden.";
CM_ SG_ 2589284008 BMS_48V_Komponentenfehler_27 "Übertragung OBD relevanter Fehlerpfade vom Secondary zum Primary Steuergerät. 
Zuordnung der generischen Komponentenfehler muss zwischen Sender und Empfänger abgestimmt werden.";
CM_ SG_ 2589284008 BMS_48V_Komponentenfehler_28 "Übertragung OBD relevanter Fehlerpfade vom Secondary zum Primary Steuergerät. 
Zuordnung der generischen Komponentenfehler muss zwischen Sender und Empfänger abgestimmt werden.";
CM_ SG_ 2589284008 BMS_48V_Komponentenfehler_29 "Übertragung OBD relevanter Fehlerpfade vom Secondary zum Primary Steuergerät. 
Zuordnung der generischen Komponentenfehler muss zwischen Sender und Empfänger abgestimmt werden.";
CM_ SG_ 2589284008 BMS_48V_Komponentenfehler_30 "Übertragung OBD relevanter Fehlerpfade vom Secondary zum Primary Steuergerät. 
Zuordnung der generischen Komponentenfehler muss zwischen Sender und Empfänger abgestimmt werden.";
CM_ SG_ 2589284008 BMS_48V_Komponentenfehler_31 "Übertragung OBD relevanter Fehlerpfade vom Secondary zum Primary Steuergerät. 
Zuordnung der generischen Komponentenfehler muss zwischen Sender und Empfänger abgestimmt werden.";
CM_ SG_ 2589284008 BMS_48V_Komponentenfehler_VLD "Übertragung OBD relevanter Fehlerpfade vom Secondary zum Primary Steuergerät. 
Zuordnung der generischen Komponentenfehler muss zwischen Sender und Empfänger abgestimmt werden.";

CM_ SG_ 880 BMS_CMC_01_MUX "Multiplexer der Botschaft BMS_CMC_01 zur Übertragung der Zellspannungen für RTM";
CM_ SG_ 880 BMS_CMC_Zellspannung_001 "Einzelzellspannung zur Übertragung per RTM";
CM_ SG_ 880 BMS_CMC_Zellspannung_002 "Einzelzellspannung zur Übertragung per RTM";
CM_ SG_ 880 BMS_CMC_Zellspannung_003 "Einzelzellspannung zur Übertragung per RTM";
CM_ SG_ 880 BMS_CMC_Zellspannung_004 "Einzelzellspannung zur Übertragung per RTM";
CM_ SG_ 880 BMS_CMC_Zellspannung_005 "Einzelzellspannung zur Übertragung per RTM";
CM_ SG_ 880 BMS_CMC_Zellspannung_006 "Einzelzellspannung zur Übertragung per RTM";
CM_ SG_ 880 BMS_CMC_Zellspannung_007 "Einzelzellspannung zur Übertragung per RTM";
CM_ SG_ 880 BMS_CMC_Zellspannung_008 "Einzelzellspannung zur Übertragung per RTM";
CM_ SG_ 880 BMS_CMC_Zellspannung_009 "Einzelzellspannung zur Übertragung per RTM";
CM_ SG_ 880 BMS_CMC_Zellspannung_010 "Einzelzellspannung zur Übertragung per RTM";
CM_ SG_ 880 BMS_CMC_Zellspannung_011 "Einzelzellspannung zur Übertragung per RTM";
CM_ SG_ 880 BMS_CMC_Zellspannung_012 "Einzelzellspannung zur Übertragung per RTM";
CM_ SG_ 880 BMS_CMC_Zellspannung_013 "Einzelzellspannung zur Übertragung per RTM";
CM_ SG_ 880 BMS_CMC_Zellspannung_014 "Einzelzellspannung zur Übertragung per RTM";
CM_ SG_ 880 BMS_CMC_Zellspannung_015 "Einzelzellspannung zur Übertragung per RTM";
CM_ SG_ 880 BMS_CMC_Zellspannung_016 "Einzelzellspannung zur Übertragung per RTM";
CM_ SG_ 880 BMS_CMC_Zellspannung_017 "Einzelzellspannung zur Übertragung per RTM";
CM_ SG_ 880 BMS_CMC_Zellspannung_018 "Einzelzellspannung zur Übertragung per RTM";
CM_ SG_ 880 BMS_CMC_Zellspannung_019 "Einzelzellspannung zur Übertragung per RTM";
CM_ SG_ 880 BMS_CMC_Zellspannung_020 "Einzelzellspannung zur Übertragung per RTM";
CM_ SG_ 880 BMS_CMC_Zellspannung_021 "Einzelzellspannung zur Übertragung per RTM";
CM_ SG_ 880 BMS_CMC_Zellspannung_022 "Einzelzellspannung zur Übertragung per RTM";
CM_ SG_ 880 BMS_CMC_Zellspannung_023 "Einzelzellspannung zur Übertragung per RTM";
CM_ SG_ 880 BMS_CMC_Zellspannung_024 "Einzelzellspannung zur Übertragung per RTM";
CM_ SG_ 880 BMS_CMC_Zellspannung_025 "Einzelzellspannung zur Übertragung per RTM";
CM_ SG_ 880 BMS_CMC_Zellspannung_026 "Einzelzellspannung zur Übertragung per RTM";
CM_ SG_ 880 BMS_CMC_Zellspannung_027 "Einzelzellspannung zur Übertragung per RTM";
CM_ SG_ 880 BMS_CMC_Zellspannung_028 "Einzelzellspannung zur Übertragung per RTM";
CM_ SG_ 880 BMS_CMC_Zellspannung_029 "Einzelzellspannung zur Übertragung per RTM";
CM_ SG_ 880 BMS_CMC_Zellspannung_030 "Einzelzellspannung zur Übertragung per RTM";
CM_ SG_ 880 BMS_CMC_Zellspannung_031 "Einzelzellspannung zur Übertragung per RTM";
CM_ SG_ 880 BMS_CMC_Zellspannung_032 "Einzelzellspannung zur Übertragung per RTM";
CM_ SG_ 880 BMS_CMC_Zellspannung_033 "Einzelzellspannung zur Übertragung per RTM";
CM_ SG_ 880 BMS_CMC_Zellspannung_034 "Einzelzellspannung zur Übertragung per RTM";
CM_ SG_ 880 BMS_CMC_Zellspannung_035 "Einzelzellspannung zur Übertragung per RTM";
CM_ SG_ 880 BMS_CMC_Zellspannung_036 "Einzelzellspannung zur Übertragung per RTM";
CM_ SG_ 880 BMS_CMC_Zellspannung_037 "Einzelzellspannung zur Übertragung per RTM";
CM_ SG_ 880 BMS_CMC_Zellspannung_038 "Einzelzellspannung zur Übertragung per RTM";
CM_ SG_ 880 BMS_CMC_Zellspannung_039 "Einzelzellspannung zur Übertragung per RTM";
CM_ SG_ 880 BMS_CMC_Zellspannung_040 "Einzelzellspannung zur Übertragung per RTM";
CM_ SG_ 880 BMS_CMC_Zellspannung_041 "Einzelzellspannung zur Übertragung per RTM";
CM_ SG_ 880 BMS_CMC_Zellspannung_042 "Einzelzellspannung zur Übertragung per RTM";
CM_ SG_ 880 BMS_CMC_Zellspannung_043 "Einzelzellspannung zur Übertragung per RTM";
CM_ SG_ 880 BMS_CMC_Zellspannung_044 "Einzelzellspannung zur Übertragung per RTM";
CM_ SG_ 880 BMS_CMC_Zellspannung_045 "Einzelzellspannung zur Übertragung per RTM";
CM_ SG_ 880 BMS_CMC_Zellspannung_046 "Einzelzellspannung zur Übertragung per RTM";
CM_ SG_ 880 BMS_CMC_Zellspannung_047 "Einzelzellspannung zur Übertragung per RTM";
CM_ SG_ 880 BMS_CMC_Zellspannung_048 "Einzelzellspannung zur Übertragung per RTM";
CM_ SG_ 880 BMS_CMC_Zellspannung_049 "Einzelzellspannung zur Übertragung per RTM";
CM_ SG_ 880 BMS_CMC_Zellspannung_050 "Einzelzellspannung zur Übertragung per RTM";
CM_ SG_ 880 BMS_CMC_Zellspannung_051 "Einzelzellspannung zur Übertragung per RTM";
CM_ SG_ 880 BMS_CMC_Zellspannung_052 "Einzelzellspannung zur Übertragung per RTM";
CM_ SG_ 880 BMS_CMC_Zellspannung_053 "Einzelzellspannung zur Übertragung per RTM";
CM_ SG_ 880 BMS_CMC_Zellspannung_054 "Einzelzellspannung zur Übertragung per RTM";
CM_ SG_ 880 BMS_CMC_Zellspannung_055 "Einzelzellspannung zur Übertragung per RTM";
CM_ SG_ 880 BMS_CMC_Zellspannung_056 "Einzelzellspannung zur Übertragung per RTM";
CM_ SG_ 880 BMS_CMC_Zellspannung_057 "Einzelzellspannung zur Übertragung per RTM";
CM_ SG_ 880 BMS_CMC_Zellspannung_058 "Einzelzellspannung zur Übertragung per RTM";
CM_ SG_ 880 BMS_CMC_Zellspannung_059 "Einzelzellspannung zur Übertragung per RTM";
CM_ SG_ 880 BMS_CMC_Zellspannung_060 "Einzelzellspannung zur Übertragung per RTM";
CM_ SG_ 880 BMS_CMC_Zellspannung_061 "Einzelzellspannung zur Übertragung per RTM";
CM_ SG_ 880 BMS_CMC_Zellspannung_062 "Einzelzellspannung zur Übertragung per RTM";
CM_ SG_ 880 BMS_CMC_Zellspannung_063 "Einzelzellspannung zur Übertragung per RTM";
CM_ SG_ 880 BMS_CMC_Zellspannung_064 "Einzelzellspannung zur Übertragung per RTM";
CM_ SG_ 880 BMS_CMC_Zellspannung_065 "Einzelzellspannung zur Übertragung per RTM";
CM_ SG_ 880 BMS_CMC_Zellspannung_066 "Einzelzellspannung zur Übertragung per RTM";
CM_ SG_ 880 BMS_CMC_Zellspannung_067 "Einzelzellspannung zur Übertragung per RTM";
CM_ SG_ 880 BMS_CMC_Zellspannung_068 "Einzelzellspannung zur Übertragung per RTM";
CM_ SG_ 880 BMS_CMC_Zellspannung_069 "Einzelzellspannung zur Übertragung per RTM";
CM_ SG_ 880 BMS_CMC_Zellspannung_070 "Einzelzellspannung zur Übertragung per RTM";
CM_ SG_ 880 BMS_CMC_Zellspannung_071 "Einzelzellspannung zur Übertragung per RTM";
CM_ SG_ 880 BMS_CMC_Zellspannung_072 "Einzelzellspannung zur Übertragung per RTM";
CM_ SG_ 880 BMS_CMC_Zellspannung_073 "Einzelzellspannung zur Übertragung per RTM";
CM_ SG_ 880 BMS_CMC_Zellspannung_074 "Einzelzellspannung zur Übertragung per RTM";
CM_ SG_ 880 BMS_CMC_Zellspannung_075 "Einzelzellspannung zur Übertragung per RTM";
CM_ SG_ 880 BMS_CMC_Zellspannung_076 "Einzelzellspannung zur Übertragung per RTM";
CM_ SG_ 880 BMS_CMC_Zellspannung_077 "Einzelzellspannung zur Übertragung per RTM";
CM_ SG_ 880 BMS_CMC_Zellspannung_078 "Einzelzellspannung zur Übertragung per RTM";
CM_ SG_ 880 BMS_CMC_Zellspannung_079 "Einzelzellspannung zur Übertragung per RTM";
CM_ SG_ 880 BMS_CMC_Zellspannung_080 "Einzelzellspannung zur Übertragung per RTM";

BA_DEF_  "DBName" STRING;
BA_DEF_  "GenNWMApBusSleep" STRING;
BA_DEF_  "GenNWMApCanNormal" STRING;
BA_DEF_  "GenNWMApCanOff" STRING;
BA_DEF_  "GenNWMApCanOn" STRING;
BA_DEF_  "GenNWMApCanSleep" STRING;
BA_DEF_  "GenNWMApCanWakeUp" STRING;
BA_DEF_  "GenNWMGotoMode_Awake" STRING;
BA_DEF_  "GenNWMGotoMode_BusSleep" STRING;
BA_DEF_  "GenNWMSleepTime" INT 0 1000000;
BA_DEF_  "GenNWMTalkNM" STRING;
BA_DEF_  "Manufacturer" STRING;
BA_DEF_  "NmhBaseAddress" HEX 0 536870911;
BA_DEF_  "NmhMessageCount" INT 0 1024;
BA_DEF_  "NmType" STRING;
BA_DEF_  "VAGTP20_SetupMessageCount" INT 0 255;
BA_DEF_  "VAGTP20_SetupStartAddress" HEX 0 2047;
BA_DEF_  "VersionDay" INT 1 31;
BA_DEF_  "VersionMonth" INT 1 12;
BA_DEF_  "VersionWeek" INT 1 52;
BA_DEF_  "VersionYear" INT 0 99;
BA_DEF_  "VersionNumber" INT 0 65535;
BA_DEF_  "BusType" STRING;
BA_DEF_  "Baudrate" INT 1 1000000;
BA_DEF_  "SamplePointMin" INT 1 100;
BA_DEF_  "SamplePointMax" INT 1 100;
BA_DEF_  "SyncJumpWidthMin" INT 1 4;
BA_DEF_  "SyncJumpWidthMax" INT 1 4;
BA_DEF_  "NBTMin" INT 1 30;
BA_DEF_  "NBTMax" INT 1 30;
BA_DEF_  "NmhTimeoutTimer" INT 0 65535;
BA_DEF_  "NmhWaitBusSleepTimer" INT 0 65535;
BA_DEF_  "NmhPrepareBusSleepTimer" INT 0 65535;
BA_DEF_  "NmhLongTimer" INT 0 65535;
BA_DEF_  "NmhNStart" INT 0 255;
BA_DEF_ BU_  "GenNodAutoGenDsp" ENUM "No", "Yes";
BA_DEF_ BU_  "GenNodAutoGenSnd" ENUM "No", "Yes";
BA_DEF_ BU_  "GenNodSleepTime" INT 0 1000000;
BA_DEF_ BU_  "ILUsed" ENUM "No", "Yes";
BA_DEF_ BU_  "ECUVariantDefault" ENUM "No", "Yes";
BA_DEF_ BU_  "ECUVariantGroup" STRING;
BA_DEF_ BU_  "NodeLayerModules" STRING;
BA_DEF_ BU_  "NmhNode" ENUM "No", "Yes";
BA_DEF_ BU_  "NmNode" ENUM "No", "Yes";
BA_DEF_ BO_  "DiagRequest" ENUM "No", "Yes";
BA_DEF_ BO_  "DiagResponse" ENUM "No", "Yes";
BA_DEF_ BO_  "DiagState" ENUM "No", "Yes";
BA_DEF_ BO_  "GenMsgChkConstant" HEX 0 4095;
BA_DEF_ BO_  "GenMsgCycleTime" INT 0 65535;
BA_DEF_ BO_  "GenMsgCycleTimeFast" INT 0 65535;
BA_DEF_ BO_  "GenMsgDelayTime" INT 0 100000;
BA_DEF_ BO_  "GenMsgILSupport" ENUM "No", "Yes";
BA_DEF_ BO_  "GenMsgNrOfRepetition" INT 0 100;
BA_DEF_ BO_  "GenMsgPDUConstants" STRING;
BA_DEF_ BO_  "GenMsgSendType" ENUM "Cyclic", "not_used", "not_used", "not_used", "not_used", "not_used", "not_used", "IfActive", "NoMsgSendType";
BA_DEF_ BO_  "GenMsgStartDelayTime" INT 0 100000;
BA_DEF_ BO_  "NmMessage" ENUM "No", "Yes";
BA_DEF_ BO_  "NmhMessage" ENUM "No", "Yes";
BA_DEF_ BO_  "MsgType" ENUM "Application", "NM ", "NMH", "TP2.0", "ISO-TP ", "BAP", "EID", "KS", "XCP_PRE_CONFIGURED", "XCP_RUNTIME_CONFIGURED";
BA_DEF_ BO_  "VAGTP20_API" HEX 0 255;
BA_DEF_ BO_  "VAGTP20_DynConnection" ENUM "No", "Yes";
BA_DEF_ BO_  "VAGTP20_DynSetup" ENUM "No", "Yes";
BA_DEF_ BO_  "VAGTP20_StatConnection" ENUM "No", "Yes";
BA_DEF_ SG_  "GenSigActiveRepetitions" INT -2147483648 2147483647;
BA_DEF_ SG_  "GenSigInactiveValue" INT -2147483648 2147483647;
BA_DEF_ SG_  "GenSigSendType" ENUM "Cyclic", "OnWrite", "OnWriteWithRepetition", "OnChange", "OnChangeWithRepetition", "IfActive", "IfActiveWithRepetition", "NoSigSendType", "OnChangeAndIfActive", "OnChangeAndIfActiveWithRepetition";
BA_DEF_ SG_  "GenSigStartValue" INT -2147483648 2147483647;
BA_DEF_ SG_  "NWM-WakeupAllowed" ENUM "No", "Yes";
BA_DEF_ SG_  "GenSigFuncType" ENUM "NoFunction", "MsgCounter", "CRC-8", "XOR", "XOR-2", "DatedBit", "SW-Kl15", "CHK", "Constant", "Protocol", "CRC-8-SAE_J1850", "CRC-32", "DataLength", "DataID", "MsgCounter16", "SOK-Signatur", "Cluster";
BA_DEF_ SG_  "GenSigSwitchedByIgnition" ENUM "No", "Yes";
BA_DEF_ SG_  "Fehlerwert" HEX 0 2147483647;
BA_DEF_ SG_  "GenSigMissingSourceValue" HEX 0 2147483647;
BA_DEF_DEF_  "DBName" "";
BA_DEF_DEF_  "GenNWMApBusSleep" "";
BA_DEF_DEF_  "GenNWMApCanNormal" "";
BA_DEF_DEF_  "GenNWMApCanOff" "";
BA_DEF_DEF_  "GenNWMApCanOn" "";
BA_DEF_DEF_  "GenNWMApCanSleep" "";
BA_DEF_DEF_  "GenNWMApCanWakeUp" "";
BA_DEF_DEF_  "GenNWMGotoMode_Awake" "";
BA_DEF_DEF_  "GenNWMGotoMode_BusSleep" "";
BA_DEF_DEF_  "GenNWMSleepTime" 0;
BA_DEF_DEF_  "GenNWMTalkNM" "";
BA_DEF_DEF_  "Manufacturer" "";
BA_DEF_DEF_  "NmhBaseAddress" 0;
BA_DEF_DEF_  "NmhMessageCount" 1;
BA_DEF_DEF_  "NmType" "None";
BA_DEF_DEF_  "VAGTP20_SetupMessageCount" 0;
BA_DEF_DEF_  "VAGTP20_SetupStartAddress" 0;
BA_DEF_DEF_  "VersionDay" 2;
BA_DEF_DEF_  "VersionMonth" 6;
BA_DEF_DEF_  "VersionWeek" 23;
BA_DEF_DEF_  "VersionYear" 22;
BA_DEF_DEF_  "VersionNumber" 0;
BA_DEF_DEF_  "BusType" "";
BA_DEF_DEF_  "Baudrate" 1;
BA_DEF_DEF_  "SamplePointMin" 1;
BA_DEF_DEF_  "SamplePointMax" 1;
BA_DEF_DEF_  "SyncJumpWidthMin" 1;
BA_DEF_DEF_  "SyncJumpWidthMax" 1;
BA_DEF_DEF_  "NBTMin" 10;
BA_DEF_DEF_  "NBTMax" 20;
BA_DEF_DEF_  "NmhTimeoutTimer" 0;
BA_DEF_DEF_  "NmhWaitBusSleepTimer" 0;
BA_DEF_DEF_  "NmhPrepareBusSleepTimer" 0;
BA_DEF_DEF_  "NmhLongTimer" 0;
BA_DEF_DEF_  "NmhNStart" 0;
BA_DEF_DEF_  "GenNodAutoGenDsp" "Yes";
BA_DEF_DEF_  "GenNodAutoGenSnd" "Yes";
BA_DEF_DEF_  "GenNodSleepTime" 0;
BA_DEF_DEF_  "ILUsed" "Yes";
BA_DEF_DEF_  "ECUVariantDefault" "Yes";
BA_DEF_DEF_  "ECUVariantGroup" "";
BA_DEF_DEF_  "NodeLayerModules" "";
BA_DEF_DEF_  "NmhNode" "Yes";
BA_DEF_DEF_  "NmNode" "No";
BA_DEF_DEF_  "DiagRequest" "No";
BA_DEF_DEF_  "DiagResponse" "No";
BA_DEF_DEF_  "DiagState" "No";
BA_DEF_DEF_  "GenMsgChkConstant" 0;
BA_DEF_DEF_  "GenMsgCycleTime" 0;
BA_DEF_DEF_  "GenMsgCycleTimeFast" 0;
BA_DEF_DEF_  "GenMsgDelayTime" 0;
BA_DEF_DEF_  "GenMsgILSupport" "No";
BA_DEF_DEF_  "GenMsgNrOfRepetition" 0;
BA_DEF_DEF_  "GenMsgPDUConstants" "";
BA_DEF_DEF_  "GenMsgSendType" "NoMsgSendType";
BA_DEF_DEF_  "GenMsgStartDelayTime" 0;
BA_DEF_DEF_  "NmMessage" "No";
BA_DEF_DEF_  "NmhMessage" "No";
BA_DEF_DEF_  "MsgType" "Application";
BA_DEF_DEF_  "VAGTP20_API" 0;
BA_DEF_DEF_  "VAGTP20_DynConnection" "No";
BA_DEF_DEF_  "VAGTP20_DynSetup" "No";
BA_DEF_DEF_  "VAGTP20_StatConnection" "No";
BA_DEF_DEF_  "GenSigActiveRepetitions" 0;
BA_DEF_DEF_  "GenSigInactiveValue" 0;
BA_DEF_DEF_  "GenSigSendType" "NoSigSendType";
BA_DEF_DEF_  "GenSigStartValue" 0;
BA_DEF_DEF_  "NWM-WakeupAllowed" "No";
BA_DEF_DEF_  "GenSigFuncType" "NoFunction";
BA_DEF_DEF_  "GenSigSwitchedByIgnition" "Yes";
BA_DEF_DEF_  "Fehlerwert" 0;
BA_DEF_DEF_  "GenSigMissingSourceValue" 0;
BA_  "DBName" "MLBevo_HCAN";
BA_  "GenNWMApBusSleep" "NMIndNetSDN()";
BA_  "GenNWMApCanNormal" "apCanNormal()";
BA_  "GenNWMApCanOff" "NMIndnetOff()";
BA_  "GenNWMApCanOn" "NMIndnetOn()";
BA_  "GenNWMApCanSleep" "apCanSleep()";
BA_  "GenNWMApCanWakeUp" "apCanWakeUp()";
BA_  "GenNWMGotoMode_Awake" "Nmh_ReqNetOn()";
BA_  "GenNWMGotoMode_BusSleep" "Nmh_ReqNetOff()";
BA_  "GenNWMSleepTime" 4000;
BA_  "GenNWMTalkNM" "Nmh_ReqNetOn()";
BA_  "Manufacturer" "VAG";
BA_  "NmhBaseAddress" 452984832;
BA_  "NmhMessageCount" 256;
BA_  "NmType" "NM-High";
BA_  "VAGTP20_SetupMessageCount" 128;
BA_  "VAGTP20_SetupStartAddress" 512;
BA_  "VersionNumber" 2400;
BA_  "BusType" "CAN";
BA_  "Baudrate" 500000;
BA_  "SamplePointMin" 80;
BA_  "SamplePointMax" 84;
BA_  "SyncJumpWidthMin" 2;
BA_  "SyncJumpWidthMax" 4;
BA_  "NmhTimeoutTimer" 1000;
BA_  "NmhWaitBusSleepTimer" 750;
BA_  "NmhPrepareBusSleepTimer" 500;
BA_  "NmhLongTimer" 200;
BA_  "NmhNStart" 20;
BA_ "GenNodSleepTime" BU_ AWC 4000;
BA_ "ECUVariantGroup" BU_ AWC "AWC";
BA_ "NodeLayerModules" BU_ AWC "NMHigh.DLL";
BA_ "GenNodSleepTime" BU_ BAP_Tester 4000;
BA_ "ECUVariantGroup" BU_ BAP_Tester "BAP";
BA_ "NmhNode" BU_ BAP_Tester 0;
BA_ "GenNodSleepTime" BU_ BMC_MLBevo 4000;
BA_ "ECUVariantGroup" BU_ BMC_MLBevo "BMS_HV";
BA_ "NodeLayerModules" BU_ BMC_MLBevo "NMHigh.DLL";
BA_ "GenNodSleepTime" BU_ BMS_MV 4000;
BA_ "ECUVariantGroup" BU_ BMS_MV "BMS_MV";
BA_ "NodeLayerModules" BU_ BMS_MV "NMHigh.DLL";
BA_ "GenNodSleepTime" BU_ BMS_NV 4000;
BA_ "ECUVariantGroup" BU_ BMS_NV "BMS_NV";
BA_ "NodeLayerModules" BU_ BMS_NV "NMHigh.DLL";
BA_ "GenNodSleepTime" BU_ CBC 4000;
BA_ "NodeLayerModules" BU_ CBC "NMHigh.DLL";
BA_ "GenNodSleepTime" BU_ DCDC_800V_PAG 4000;
BA_ "ECUVariantDefault" BU_ DCDC_800V_PAG 0;
BA_ "ECUVariantGroup" BU_ DCDC_800V_PAG "DCDC";
BA_ "NodeLayerModules" BU_ DCDC_800V_PAG "NMHigh.DLL";
BA_ "GenNodSleepTime" BU_ DCDC_HV 4000;
BA_ "ECUVariantDefault" BU_ DCDC_HV 0;
BA_ "ECUVariantGroup" BU_ DCDC_HV "DCDC";
BA_ "NodeLayerModules" BU_ DCDC_HV "NMHigh.DLL";
BA_ "GenNodSleepTime" BU_ DCDC_HV_02 4000;
BA_ "ECUVariantGroup" BU_ DCDC_HV_02 "DCDC2";
BA_ "NodeLayerModules" BU_ DCDC_HV_02 "NMHigh.DLL";
BA_ "GenNodSleepTime" BU_ DCDC_IHEV 4000;
BA_ "ECUVariantGroup" BU_ DCDC_IHEV "DCDC_IHEV";
BA_ "NodeLayerModules" BU_ DCDC_IHEV "NMHigh.DLL";
BA_ "GenNodSleepTime" BU_ FCU_MLBevo_FCEV 4000;
BA_ "ECUVariantGroup" BU_ FCU_MLBevo_FCEV "FCU";
BA_ "NodeLayerModules" BU_ FCU_MLBevo_FCEV "NMHigh.DLL";
BA_ "GenNodSleepTime" BU_ Gateway 4000;
BA_ "ECUVariantGroup" BU_ Gateway "Gateway";
BA_ "NodeLayerModules" BU_ Gateway "NMHigh.DLL";
BA_ "GenNodSleepTime" BU_ Gateway_PAG 4000;
BA_ "ECUVariantDefault" BU_ Gateway_PAG 0;
BA_ "ECUVariantGroup" BU_ Gateway_PAG "Gateway";
BA_ "NodeLayerModules" BU_ Gateway_PAG "NMHigh.DLL";
BA_ "GenNodSleepTime" BU_ Ladegeraet_2 4000;
BA_ "ECUVariantGroup" BU_ Ladegeraet_2 "OBC2";
BA_ "NodeLayerModules" BU_ Ladegeraet_2 "NMHigh.DLL";
BA_ "GenNodSleepTime" BU_ Ladegeraet_Konzern 4000;
BA_ "ECUVariantGroup" BU_ Ladegeraet_Konzern "OBC";
BA_ "NodeLayerModules" BU_ Ladegeraet_Konzern "NMHigh.DLL";
BA_ "GenNodSleepTime" BU_ LE1 4000;
BA_ "ECUVariantDefault" BU_ LE1 0;
BA_ "ECUVariantGroup" BU_ LE1 "LE";
BA_ "NodeLayerModules" BU_ LE1 "NMHigh.DLL";
BA_ "GenNodSleepTime" BU_ LE2 4000;
BA_ "ECUVariantGroup" BU_ LE2 "LE2";
BA_ "NodeLayerModules" BU_ LE2 "NMHigh.DLL";
BA_ "GenNodSleepTime" BU_ LE_MLBevo 4000;
BA_ "ECUVariantGroup" BU_ LE_MLBevo "LE";
BA_ "NodeLayerModules" BU_ LE_MLBevo "NMHigh.DLL";
BA_ "GenNodSleepTime" BU_ Sub_Gateway 4000;
BA_ "ECUVariantGroup" BU_ Sub_Gateway "Sub_Gateway";
BA_ "NodeLayerModules" BU_ Sub_Gateway "NMHigh.DLL";
BA_ "GenNodSleepTime" BU_ TME 4000;
BA_ "ECUVariantGroup" BU_ TME "TME";
BA_ "NodeLayerModules" BU_ TME "NMHigh.DLL";
BA_ "GenMsgChkConstant" BO_ 64 64;
BA_ "GenMsgCycleTime" BO_ 64 40;
BA_ "GenMsgCycleTimeFast" BO_ 64 10;
BA_ "GenMsgDelayTime" BO_ 64 10;
BA_ "GenMsgILSupport" BO_ 64 1;
BA_ "GenMsgNrOfRepetition" BO_ 64 5;
BA_ "GenMsgPDUConstants" BO_ 64 "0x40,0x40,0x40,0x40,0x40,0x40,0x40,0x40,0x40,0x40,0x40,0x40,0x40,0x40,0x40,0x40";
BA_ "GenMsgSendType" BO_ 64 0;
BA_ "GenMsgCycleTime" BO_ 2589283757 1000;
BA_ "GenMsgILSupport" BO_ 2589283757 1;
BA_ "GenMsgSendType" BO_ 2589283757 0;
BA_ "GenMsgStartDelayTime" BO_ 2589283757 100;
BA_ "GenMsgCycleTime" BO_ 2589283607 200;
BA_ "GenMsgDelayTime" BO_ 2589283607 100;
BA_ "GenMsgILSupport" BO_ 2589283607 1;
BA_ "GenMsgPDUConstants" BO_ 2589283607 "0xfb,0xee,0x5d,0x2d,0xfa,0x85,0x27,0xd4,0xc9,0xc4,0xa5,0x45,0x5f,0x76,0xa3,0x89";
BA_ "GenMsgSendType" BO_ 2589283607 0;
BA_ "GenMsgCycleTime" BO_ 2589283618 200;
BA_ "GenMsgDelayTime" BO_ 2589283618 100;
BA_ "GenMsgILSupport" BO_ 2589283618 1;
BA_ "GenMsgSendType" BO_ 2589283618 0;
BA_ "MsgType" BO_ 2536720384 5;
BA_ "MsgType" BO_ 2536720385 5;
BA_ "MsgType" BO_ 2536720400 5;
BA_ "MsgType" BO_ 2536711424 5;
BA_ "MsgType" BO_ 2536711425 5;
BA_ "MsgType" BO_ 2536711426 5;
BA_ "MsgType" BO_ 2536711427 5;
BA_ "MsgType" BO_ 2536711429 5;
BA_ "MsgType" BO_ 2536711440 5;
BA_ "MsgType" BO_ 2536767264 5;
BA_ "MsgType" BO_ 2536767280 5;
BA_ "MsgType" BO_ 2536706306 5;
BA_ "MsgType" BO_ 2536706310 5;
BA_ "MsgType" BO_ 2536706320 5;
BA_ "GenMsgCycleTime" BO_ 1615 1000;
BA_ "GenMsgDelayTime" BO_ 1615 40;
BA_ "GenMsgILSupport" BO_ 1615 1;
BA_ "GenMsgSendType" BO_ 1615 0;
BA_ "GenMsgCycleTime" BO_ 1626 1000;
BA_ "GenMsgCycleTimeFast" BO_ 1626 100;
BA_ "GenMsgDelayTime" BO_ 1626 50;
BA_ "GenMsgILSupport" BO_ 1626 1;
BA_ "GenMsgNrOfRepetition" BO_ 1626 10;
BA_ "GenMsgSendType" BO_ 1626 0;
BA_ "GenMsgCycleTime" BO_ 401 10;
BA_ "GenMsgILSupport" BO_ 401 1;
BA_ "GenMsgPDUConstants" BO_ 401 "0x7d,0x0e,0xaf,0x0b,0x24,0x58,0x88,0x9e,0x89,0x3a,0x81,0x61,0x4e,0xe3,0x04,0x1f";
BA_ "GenMsgSendType" BO_ 401 0;
BA_ "GenMsgCycleTime" BO_ 417 100;
BA_ "GenMsgILSupport" BO_ 417 1;
BA_ "GenMsgSendType" BO_ 417 0;
BA_ "GenMsgCycleTime" BO_ 925 100;
BA_ "GenMsgILSupport" BO_ 925 1;
BA_ "GenMsgSendType" BO_ 925 0;
BA_ "GenMsgCycleTime" BO_ 1442 500;
BA_ "GenMsgDelayTime" BO_ 1442 20;
BA_ "GenMsgILSupport" BO_ 1442 1;
BA_ "GenMsgPDUConstants" BO_ 1442 "0xeb,0x4c,0x44,0xaf,0x21,0x8d,0x01,0x58,0xfa,0x93,0xdb,0x89,0x15,0x10,0x4a,0x61";
BA_ "GenMsgSendType" BO_ 1442 0;
BA_ "GenMsgCycleTime" BO_ 687 50;
BA_ "GenMsgILSupport" BO_ 687 1;
BA_ "GenMsgSendType" BO_ 687 0;
BA_ "GenMsgCycleTime" BO_ 1438 500;
BA_ "GenMsgILSupport" BO_ 1438 1;
BA_ "GenMsgSendType" BO_ 1438 0;
BA_ "GenMsgChkConstant" BO_ 1482 67;
BA_ "GenMsgCycleTime" BO_ 1482 500;
BA_ "GenMsgDelayTime" BO_ 1482 50;
BA_ "GenMsgILSupport" BO_ 1482 1;
BA_ "GenMsgPDUConstants" BO_ 1482 "0x43,0x43,0x43,0x43,0x43,0x43,0x43,0x43,0x43,0x43,0x43,0x43,0x43,0x43,0x43,0x43";
BA_ "GenMsgSendType" BO_ 1482 0;
BA_ "GenMsgCycleTime" BO_ 2527679979 1000;
BA_ "GenMsgILSupport" BO_ 2527679979 1;
BA_ "GenMsgSendType" BO_ 2527679979 0;
BA_ "GenMsgCycleTime" BO_ 1289 100;
BA_ "GenMsgILSupport" BO_ 1289 1;
BA_ "GenMsgSendType" BO_ 1289 0;
BA_ "GenMsgCycleTime" BO_ 2527679654 2000;
BA_ "GenMsgILSupport" BO_ 2527679654 1;
BA_ "GenMsgPDUConstants" BO_ 2527679654 "0x79,0xb9,0x67,0xad,0xd5,0xf7,0x70,0xaa,0x44,0x61,0x5a,0xdc,0x26,0xb4,0xd2,0xc3";
BA_ "GenMsgSendType" BO_ 2527679654 0;
BA_ "GenMsgCycleTime" BO_ 2589283637 2000;
BA_ "GenMsgILSupport" BO_ 2589283637 1;
BA_ "GenMsgSendType" BO_ 2589283637 0;
BA_ "GenMsgCycleTime" BO_ 2589283638 2000;
BA_ "GenMsgILSupport" BO_ 2589283638 1;
BA_ "GenMsgSendType" BO_ 2589283638 0;
BA_ "GenMsgCycleTime" BO_ 1111 100;
BA_ "GenMsgILSupport" BO_ 1111 1;
BA_ "GenMsgPDUConstants" BO_ 1111 "0x82,0x79,0xee,0xb9,0xf9,0x67,0x97,0xad,0xb1,0xd5,0xcb,0xf7,0xb6,0x70,0x13,0xaa";
BA_ "GenMsgSendType" BO_ 1111 0;
BA_ "GenMsgCycleTime" BO_ 2589283877 2000;
BA_ "GenMsgILSupport" BO_ 2589283877 1;
BA_ "GenMsgSendType" BO_ 2589283877 0;
BA_ "GenMsgCycleTime" BO_ 2589283641 1000;
BA_ "GenMsgILSupport" BO_ 2589283641 1;
BA_ "GenMsgSendType" BO_ 2589283641 0;
BA_ "GenMsgCycleTime" BO_ 2589283651 1000;
BA_ "GenMsgILSupport" BO_ 2589283651 1;
BA_ "GenMsgSendType" BO_ 2589283651 0;
BA_ "GenMsgCycleTime" BO_ 2589283652 500;
BA_ "GenMsgILSupport" BO_ 2589283652 1;
BA_ "GenMsgPDUConstants" BO_ 2589283652 "0x05,0xa8,0x5b,0x9b,0x95,0xb2,0x30,0x1b,0x1d,0xb9,0x11,0xcb,0x94,0x44,0xcc,0x24";
BA_ "GenMsgSendType" BO_ 2589283652 0;
BA_ "GenMsgCycleTime" BO_ 2589283878 1000;
BA_ "GenMsgILSupport" BO_ 2589283878 1;
BA_ "GenMsgSendType" BO_ 2589283878 0;
BA_ "GenMsgCycleTime" BO_ 2589283666 1000;
BA_ "GenMsgDelayTime" BO_ 2589283666 100;
BA_ "GenMsgILSupport" BO_ 2589283666 1;
BA_ "GenMsgSendType" BO_ 2589283666 0;
BA_ "GenMsgCycleTime" BO_ 2463978763 100;
BA_ "GenMsgILSupport" BO_ 2463978763 1;
BA_ "GenMsgPDUConstants" BO_ 2463978763 "0x67,0xf7,0x44,0xdc,0xd2,0xca,0xe7,0x2b,0xd6,0x5c,0xc6,0xa3,0xbe,0x0d,0x16,0x58";
BA_ "GenMsgSendType" BO_ 2463978763 0;
BA_ "GenMsgCycleTime" BO_ 2463978838 100;
BA_ "GenMsgILSupport" BO_ 2463978838 1;
BA_ "GenMsgSendType" BO_ 2463978838 0;
BA_ "GenMsgCycleTime" BO_ 2589283895 100;
BA_ "GenMsgILSupport" BO_ 2589283895 1;
BA_ "GenMsgSendType" BO_ 2589283895 0;
BA_ "GenMsgCycleTime" BO_ 2589284070 2000;
BA_ "GenMsgILSupport" BO_ 2589284070 1;
BA_ "GenMsgSendType" BO_ 2589284070 0;
BA_ "GenMsgCycleTime" BO_ 2589284007 960;
BA_ "GenMsgILSupport" BO_ 2589284007 1;
BA_ "GenMsgSendType" BO_ 2589284007 0;
BA_ "GenMsgCycleTime" BO_ 2589284008 1000;
BA_ "GenMsgILSupport" BO_ 2589284008 1;
BA_ "GenMsgSendType" BO_ 2589284008 0;
BA_ "GenMsgCycleTime" BO_ 880 60;
BA_ "GenMsgILSupport" BO_ 880 1;
BA_ "GenMsgSendType" BO_ 880 0;
BA_ "GenSigSendType" SG_ 64 AB_Anzeige_Fussg 0;
BA_ "GenSigSwitchedByIgnition" SG_ 64 AB_Anzeige_Fussg 0;
BA_ "GenSigSendType" SG_ 64 AB_Belegung_VF 0;
BA_ "GenSigSwitchedByIgnition" SG_ 64 AB_Belegung_VF 0;
BA_ "Fehlerwert" SG_ 64 AB_Belegung_VF 1;
BA_ "GenSigActiveRepetitions" SG_ 64 AB_Crash_Int 5;
BA_ "GenSigSendType" SG_ 64 AB_Crash_Int 4;
BA_ "GenSigSwitchedByIgnition" SG_ 64 AB_Crash_Int 0;
BA_ "GenSigSendType" SG_ 64 AB_Deaktiviert 0;
BA_ "GenSigSwitchedByIgnition" SG_ 64 AB_Deaktiviert 0;
BA_ "GenSigActiveRepetitions" SG_ 64 AB_Deaktivierung_HV 5;
BA_ "GenSigSendType" SG_ 64 AB_Deaktivierung_HV 4;
BA_ "GenSigSwitchedByIgnition" SG_ 64 AB_Deaktivierung_HV 0;
BA_ "Fehlerwert" SG_ 64 AB_Deaktivierung_HV 7;
BA_ "GenSigSendType" SG_ 64 AB_Diagnose 0;
BA_ "GenSigSwitchedByIgnition" SG_ 64 AB_Diagnose 0;
BA_ "GenSigSendType" SG_ 64 AB_EDR_Trigger 3;
BA_ "GenSigSwitchedByIgnition" SG_ 64 AB_EDR_Trigger 0;
BA_ "GenSigSendType" SG_ 64 AB_Erh_Auf_VB 0;
BA_ "GenSigSwitchedByIgnition" SG_ 64 AB_Erh_Auf_VB 0;
BA_ "GenSigActiveRepetitions" SG_ 64 AB_Front_Crash 5;
BA_ "GenSigSendType" SG_ 64 AB_Front_Crash 4;
BA_ "GenSigSwitchedByIgnition" SG_ 64 AB_Front_Crash 0;
BA_ "GenSigSendType" SG_ 64 AB_Gurtwarn_VB 0;
BA_ "GenSigSwitchedByIgnition" SG_ 64 AB_Gurtwarn_VB 0;
BA_ "GenSigSendType" SG_ 64 AB_Gurtwarn_VF 0;
BA_ "GenSigSwitchedByIgnition" SG_ 64 AB_Gurtwarn_VF 0;
BA_ "GenSigActiveRepetitions" SG_ 64 AB_Heck_Crash 5;
BA_ "GenSigSendType" SG_ 64 AB_Heck_Crash 4;
BA_ "GenSigSwitchedByIgnition" SG_ 64 AB_Heck_Crash 0;
BA_ "GenSigSendType" SG_ 64 AB_Lampe 0;
BA_ "GenSigStartValue" SG_ 64 AB_Lampe 1;
BA_ "GenSigSwitchedByIgnition" SG_ 64 AB_Lampe 0;
BA_ "GenSigActiveRepetitions" SG_ 64 AB_MKB_Anforderung 5;
BA_ "GenSigSendType" SG_ 64 AB_MKB_Anforderung 4;
BA_ "GenSigSwitchedByIgnition" SG_ 64 AB_MKB_Anforderung 0;
BA_ "GenSigSendType" SG_ 64 AB_MKB_gueltig 0;
BA_ "GenSigSwitchedByIgnition" SG_ 64 AB_MKB_gueltig 0;
BA_ "GenSigSendType" SG_ 64 AB_RGS_Anst 0;
BA_ "GenSigStartValue" SG_ 64 AB_RGS_Anst 8;
BA_ "GenSigSwitchedByIgnition" SG_ 64 AB_RGS_Anst 0;
BA_ "GenSigActiveRepetitions" SG_ 64 AB_Rollover_Crash 5;
BA_ "GenSigSendType" SG_ 64 AB_Rollover_Crash 4;
BA_ "GenSigSwitchedByIgnition" SG_ 64 AB_Rollover_Crash 0;
BA_ "GenSigActiveRepetitions" SG_ 64 AB_SB_Crash 5;
BA_ "GenSigSendType" SG_ 64 AB_SB_Crash 4;
BA_ "GenSigSwitchedByIgnition" SG_ 64 AB_SB_Crash 0;
BA_ "GenSigActiveRepetitions" SG_ 64 AB_SF_Crash 5;
BA_ "GenSigSendType" SG_ 64 AB_SF_Crash 4;
BA_ "GenSigSwitchedByIgnition" SG_ 64 AB_SF_Crash 0;
BA_ "GenSigSendType" SG_ 64 AB_Stellgliedtest 0;
BA_ "GenSigSwitchedByIgnition" SG_ 64 AB_Stellgliedtest 0;
BA_ "GenSigSendType" SG_ 64 AB_Systemfehler 0;
BA_ "GenSigSwitchedByIgnition" SG_ 64 AB_Systemfehler 0;
BA_ "GenSigSendType" SG_ 64 AB_Texte_AKS 0;
BA_ "GenSigSwitchedByIgnition" SG_ 64 AB_Texte_AKS 0;
BA_ "GenSigSendType" SG_ 64 AB_VB_deaktiviert 0;
BA_ "GenSigStartValue" SG_ 64 AB_VB_deaktiviert 1;
BA_ "GenSigSwitchedByIgnition" SG_ 64 AB_VB_deaktiviert 0;
BA_ "GenSigSendType" SG_ 64 AB_Versorgungsspannung 0;
BA_ "GenSigSwitchedByIgnition" SG_ 64 AB_Versorgungsspannung 0;
BA_ "GenSigSendType" SG_ 64 Airbag_01_BZ 0;
BA_ "GenSigFuncType" SG_ 64 Airbag_01_BZ 1;
BA_ "GenSigSwitchedByIgnition" SG_ 64 Airbag_01_BZ 0;
BA_ "GenSigSendType" SG_ 64 Airbag_01_CRC 0;
BA_ "GenSigFuncType" SG_ 64 Airbag_01_CRC 2;
BA_ "GenSigSwitchedByIgnition" SG_ 64 Airbag_01_CRC 0;
BA_ "GenSigSendType" SG_ 64 SC_LowSpeedCrashErkannt 0;
BA_ "GenSigSwitchedByIgnition" SG_ 64 SC_LowSpeedCrashErkannt 0;
BA_ "GenSigSendType" SG_ 64 SC_Masterzeit 0;
BA_ "GenSigStartValue" SG_ 64 SC_Masterzeit 127;
BA_ "GenSigSendType" SG_ 64 SC_Masterzeit_Offset 0;
BA_ "GenSigSendType" SG_ 2589283757 AT_VALID_TIME 0;
BA_ "GenSigSwitchedByIgnition" SG_ 2589283757 AT_VALID_TIME 0;
BA_ "GenSigSendType" SG_ 2589283607 AWC_01_BZ 0;
BA_ "GenSigFuncType" SG_ 2589283607 AWC_01_BZ 1;
BA_ "GenSigSwitchedByIgnition" SG_ 2589283607 AWC_01_BZ 0;
BA_ "GenSigSendType" SG_ 2589283607 AWC_01_CRC 0;
BA_ "GenSigFuncType" SG_ 2589283607 AWC_01_CRC 2;
BA_ "GenSigSwitchedByIgnition" SG_ 2589283607 AWC_01_CRC 0;
BA_ "GenSigSendType" SG_ 2589283607 AWC_Fehlerstatus 3;
BA_ "GenSigStartValue" SG_ 2589283607 AWC_Fehlerstatus 7;
BA_ "GenSigSwitchedByIgnition" SG_ 2589283607 AWC_Fehlerstatus 0;
BA_ "GenSigSendType" SG_ 2589283607 AWC_IstModus 3;
BA_ "GenSigStartValue" SG_ 2589283607 AWC_IstModus 6;
BA_ "GenSigSwitchedByIgnition" SG_ 2589283607 AWC_IstModus 0;
BA_ "GenSigSendType" SG_ 2589283607 AWC_IstSpannung 0;
BA_ "GenSigStartValue" SG_ 2589283607 AWC_IstSpannung 1022;
BA_ "GenSigSwitchedByIgnition" SG_ 2589283607 AWC_IstSpannung 0;
BA_ "Fehlerwert" SG_ 2589283607 AWC_IstSpannung 1023;
BA_ "GenSigSendType" SG_ 2589283607 AWC_IstStrom 0;
BA_ "GenSigStartValue" SG_ 2589283607 AWC_IstStrom 510;
BA_ "GenSigSwitchedByIgnition" SG_ 2589283607 AWC_IstStrom 0;
BA_ "Fehlerwert" SG_ 2589283607 AWC_IstStrom 511;
BA_ "GenSigSendType" SG_ 2589283607 AWC_MaxLadLeistung 0;
BA_ "GenSigStartValue" SG_ 2589283607 AWC_MaxLadLeistung 510;
BA_ "GenSigSwitchedByIgnition" SG_ 2589283607 AWC_MaxLadLeistung 0;
BA_ "Fehlerwert" SG_ 2589283607 AWC_MaxLadLeistung 511;
BA_ "GenSigSendType" SG_ 2589283607 AWC_Status_Spgfreiheit 3;
BA_ "GenSigSwitchedByIgnition" SG_ 2589283607 AWC_Status_Spgfreiheit 0;
BA_ "Fehlerwert" SG_ 2589283607 AWC_Status_Spgfreiheit 3;
BA_ "GenSigSendType" SG_ 2589283618 AWC_Fehler_FOD 3;
BA_ "GenSigSwitchedByIgnition" SG_ 2589283618 AWC_Fehler_FOD 0;
BA_ "Fehlerwert" SG_ 2589283618 AWC_Fehler_FOD 1;
BA_ "GenSigSendType" SG_ 2589283618 AWC_Fehler_Kommunikation 3;
BA_ "GenSigSwitchedByIgnition" SG_ 2589283618 AWC_Fehler_Kommunikation 0;
BA_ "Fehlerwert" SG_ 2589283618 AWC_Fehler_Kommunikation 1;
BA_ "GenSigSendType" SG_ 2589283618 AWC_Fehler_LOP 3;
BA_ "GenSigSwitchedByIgnition" SG_ 2589283618 AWC_Fehler_LOP 0;
BA_ "Fehlerwert" SG_ 2589283618 AWC_Fehler_LOP 1;
BA_ "GenSigSendType" SG_ 2589283618 AWC_Fehler_zMover 3;
BA_ "GenSigSwitchedByIgnition" SG_ 2589283618 AWC_Fehler_zMover 0;
BA_ "Fehlerwert" SG_ 2589283618 AWC_Fehler_zMover 1;
BA_ "GenSigSendType" SG_ 2589283618 AWC_Ladeoption_Infrastruktur 3;
BA_ "GenSigStartValue" SG_ 2589283618 AWC_Ladeoption_Infrastruktur 7;
BA_ "GenSigSwitchedByIgnition" SG_ 2589283618 AWC_Ladeoption_Infrastruktur 0;
BA_ "GenSigSendType" SG_ 2589283618 AWC_Panel_PositionX 0;
BA_ "GenSigStartValue" SG_ 2589283618 AWC_Panel_PositionX 2046;
BA_ "GenSigSwitchedByIgnition" SG_ 2589283618 AWC_Panel_PositionX 0;
BA_ "Fehlerwert" SG_ 2589283618 AWC_Panel_PositionX 2047;
BA_ "GenSigSendType" SG_ 2589283618 AWC_Panel_PositionY 0;
BA_ "GenSigStartValue" SG_ 2589283618 AWC_Panel_PositionY 2046;
BA_ "GenSigSwitchedByIgnition" SG_ 2589283618 AWC_Panel_PositionY 0;
BA_ "Fehlerwert" SG_ 2589283618 AWC_Panel_PositionY 2047;
BA_ "GenSigSendType" SG_ 2589283618 AWC_Panel_Verdrehwinkel 0;
BA_ "GenSigStartValue" SG_ 2589283618 AWC_Panel_Verdrehwinkel 254;
BA_ "GenSigSwitchedByIgnition" SG_ 2589283618 AWC_Panel_Verdrehwinkel 0;
BA_ "Fehlerwert" SG_ 2589283618 AWC_Panel_Verdrehwinkel 255;
BA_ "GenSigSendType" SG_ 2589283618 AWC_Positionierhilfe 3;
BA_ "GenSigSwitchedByIgnition" SG_ 2589283618 AWC_Positionierhilfe 0;
BA_ "GenSigSendType" SG_ 2589283618 AWC_Spielschutz 0;
BA_ "GenSigSwitchedByIgnition" SG_ 2589283618 AWC_Spielschutz 0;
BA_ "GenSigSendType" SG_ 2589283618 AWC_Status 3;
BA_ "GenSigStartValue" SG_ 2589283618 AWC_Status 14;
BA_ "GenSigSwitchedByIgnition" SG_ 2589283618 AWC_Status 0;
BA_ "Fehlerwert" SG_ 2589283618 AWC_Status 15;
BA_ "GenSigSendType" SG_ 2589283618 AWC_Verzoegerung_FOD 3;
BA_ "GenSigSwitchedByIgnition" SG_ 2589283618 AWC_Verzoegerung_FOD 0;
BA_ "GenSigSendType" SG_ 2589283618 AWC_Verzoegerung_LOP 3;
BA_ "GenSigSwitchedByIgnition" SG_ 2589283618 AWC_Verzoegerung_LOP 0;
BA_ "GenSigSendType" SG_ 2589283618 AWC_Verzoegerung_Temp 3;
BA_ "GenSigSwitchedByIgnition" SG_ 2589283618 AWC_Verzoegerung_Temp 0;
BA_ "GenSigSendType" SG_ 2589283618 AWC_Verzoegerung_zMover 3;
BA_ "GenSigSwitchedByIgnition" SG_ 2589283618 AWC_Verzoegerung_zMover 0;
BA_ "GenSigSendType" SG_ 2536720384 BAP_AWC_ASG_01_Header 3;
BA_ "GenSigSwitchedByIgnition" SG_ 2536720384 BAP_AWC_ASG_01_Header 0;
BA_ "GenSigSendType" SG_ 2536720385 BAP_AWC_ASG_02_Header 3;
BA_ "GenSigSwitchedByIgnition" SG_ 2536720385 BAP_AWC_ASG_02_Header 0;
BA_ "GenSigSendType" SG_ 2536720400 BAP_AWC_FSG_01_Header 3;
BA_ "GenSigSwitchedByIgnition" SG_ 2536720400 BAP_AWC_FSG_01_Header 0;
BA_ "GenSigSendType" SG_ 2536711424 BAP_BatteryControl_ASG_01_Header 3;
BA_ "GenSigSwitchedByIgnition" SG_ 2536711424 BAP_BatteryControl_ASG_01_Header 0;
BA_ "GenSigSendType" SG_ 2536711425 BAP_BatteryControl_ASG_02_Header 3;
BA_ "GenSigSwitchedByIgnition" SG_ 2536711425 BAP_BatteryControl_ASG_02_Header 0;
BA_ "GenSigSendType" SG_ 2536711426 BAP_BatteryControl_ASG_03_Header 3;
BA_ "GenSigSwitchedByIgnition" SG_ 2536711426 BAP_BatteryControl_ASG_03_Header 0;
BA_ "GenSigSendType" SG_ 2536711427 BAP_BatteryControl_ASG_04_Header 3;
BA_ "GenSigSwitchedByIgnition" SG_ 2536711427 BAP_BatteryControl_ASG_04_Header 0;
BA_ "GenSigSendType" SG_ 2536711429 BAP_BatteryControl_ASG_06_Header 3;
BA_ "GenSigSwitchedByIgnition" SG_ 2536711429 BAP_BatteryControl_ASG_06_Header 0;
BA_ "GenSigSendType" SG_ 2536711440 BAP_BatteryControl_FSG_01_Header 3;
BA_ "GenSigSwitchedByIgnition" SG_ 2536711440 BAP_BatteryControl_FSG_01_Header 0;
BA_ "GenSigSendType" SG_ 2536767264 BAP_Debug_Cmd 3;
BA_ "GenSigSwitchedByIgnition" SG_ 2536767264 BAP_Debug_Cmd 0;
BA_ "GenSigSendType" SG_ 2536767280 BAP_Debug_Data 3;
BA_ "GenSigSwitchedByIgnition" SG_ 2536767280 BAP_Debug_Data 0;
BA_ "GenSigSendType" SG_ 2536706306 BAP_Uhrzeit_ASG_03_Header 3;
BA_ "GenSigSwitchedByIgnition" SG_ 2536706306 BAP_Uhrzeit_ASG_03_Header 0;
BA_ "GenSigSendType" SG_ 2536706310 BAP_Uhrzeit_ASG_07_Header 3;
BA_ "GenSigSwitchedByIgnition" SG_ 2536706310 BAP_Uhrzeit_ASG_07_Header 0;
BA_ "GenSigSendType" SG_ 2536706320 BAP_Uhrzeit_FSG_01_Header 3;
BA_ "GenSigSwitchedByIgnition" SG_ 2536706320 BAP_Uhrzeit_FSG_01_Header 0;
BA_ "GenSigSendType" SG_ 1615 BCM1_Hinweis_Lichtnachlauf 3;
BA_ "GenSigSwitchedByIgnition" SG_ 1615 BCM1_Hinweis_Lichtnachlauf 0;
BA_ "GenSigSendType" SG_ 1615 BCM1_HUD_Eyeboxposition 3;
BA_ "GenSigSwitchedByIgnition" SG_ 1615 BCM1_HUD_Eyeboxposition 0;
BA_ "GenSigSendType" SG_ 1615 BCM1_HUD_Eyeboxposition_Status 3;
BA_ "GenSigSwitchedByIgnition" SG_ 1615 BCM1_HUD_Eyeboxposition_Status 0;
BA_ "GenSigSendType" SG_ 1615 BCM1_HUD_Taster 3;
BA_ "GenSigSwitchedByIgnition" SG_ 1615 BCM1_HUD_Taster 0;
BA_ "GenSigSendType" SG_ 1615 BCM1_LDS_Stellung 3;
BA_ "GenSigSwitchedByIgnition" SG_ 1615 BCM1_LDS_Stellung 0;
BA_ "Fehlerwert" SG_ 1615 BCM1_LDS_Stellung 7;
BA_ "GenSigSendType" SG_ 1615 BCM1_Lichtwarn_Texte 3;
BA_ "GenSigSwitchedByIgnition" SG_ 1615 BCM1_Lichtwarn_Texte 0;
BA_ "GenSigSendType" SG_ 1615 BCM1_Spannungs_Anf 3;
BA_ "GenSigSwitchedByIgnition" SG_ 1615 BCM1_Spannungs_Anf 0;
BA_ "GenSigSendType" SG_ 1615 BCM1_Status_Ladeanzeige 3;
BA_ "GenSigSwitchedByIgnition" SG_ 1615 BCM1_Status_Ladeanzeige 0;
BA_ "GenSigSendType" SG_ 1615 BCM1_Stellgroesse_Kl_58s 3;
BA_ "GenSigStartValue" SG_ 1615 BCM1_Stellgroesse_Kl_58s 126;
BA_ "GenSigSwitchedByIgnition" SG_ 1615 BCM1_Stellgroesse_Kl_58s 0;
BA_ "Fehlerwert" SG_ 1615 BCM1_Stellgroesse_Kl_58s 127;
BA_ "GenSigSendType" SG_ 1615 CHA_Drehschalter_Modus 3;
BA_ "GenSigSwitchedByIgnition" SG_ 1615 CHA_Drehschalter_Modus 0;
BA_ "Fehlerwert" SG_ 1615 CHA_Drehschalter_Modus 15;
BA_ "GenSigSendType" SG_ 1615 CHA_Kombi_Texte 3;
BA_ "GenSigSwitchedByIgnition" SG_ 1615 CHA_Kombi_Texte 0;
BA_ "GenSigSendType" SG_ 1615 KRH_Stufe_LED_li 3;
BA_ "GenSigSwitchedByIgnition" SG_ 1615 KRH_Stufe_LED_li 0;
BA_ "GenSigSendType" SG_ 1615 KRH_Stufe_LED_re 3;
BA_ "GenSigSwitchedByIgnition" SG_ 1615 KRH_Stufe_LED_re 0;
BA_ "GenSigSendType" SG_ 1615 LV_Laserlicht_Texte 0;
BA_ "GenSigSwitchedByIgnition" SG_ 1615 LV_Laserlicht_Texte 0;
BA_ "GenSigSendType" SG_ 1615 LV_LED_Scheinwerfer_li_def 0;
BA_ "GenSigSwitchedByIgnition" SG_ 1615 LV_LED_Scheinwerfer_li_def 0;
BA_ "GenSigSendType" SG_ 1615 LV_LED_Scheinwerfer_re_def 0;
BA_ "GenSigSwitchedByIgnition" SG_ 1615 LV_LED_Scheinwerfer_re_def 0;
BA_ "GenSigSendType" SG_ 1626 APS_Tongeber_defekt 3;
BA_ "GenSigSwitchedByIgnition" SG_ 1626 APS_Tongeber_defekt 0;
BA_ "GenSigSendType" SG_ 1626 BCM1_AFS_Lampe 3;
BA_ "GenSigSwitchedByIgnition" SG_ 1626 BCM1_AFS_Lampe 0;
BA_ "GenSigSendType" SG_ 1626 BCM1_EasyEntry_Status 3;
BA_ "GenSigSwitchedByIgnition" SG_ 1626 BCM1_EasyEntry_Status 0;
BA_ "GenSigSendType" SG_ 1626 BCM1_Fahrlicht_Hinweis 3;
BA_ "GenSigSwitchedByIgnition" SG_ 1626 BCM1_Fahrlicht_Hinweis 0;
BA_ "GenSigSendType" SG_ 1626 BCM1_Hinweis_Lichtnachlauf 3;
BA_ "GenSigSwitchedByIgnition" SG_ 1626 BCM1_Hinweis_Lichtnachlauf 0;
BA_ "GenSigSendType" SG_ 1626 BCM1_Kl_15_HW_erkannt 3;
BA_ "GenSigSwitchedByIgnition" SG_ 1626 BCM1_Kl_15_HW_erkannt 0;
BA_ "GenSigSendType" SG_ 1626 BCM1_Kl_15_Sig_HW_erkannt 3;
BA_ "GenSigSwitchedByIgnition" SG_ 1626 BCM1_Kl_15_Sig_HW_erkannt 0;
BA_ "GenSigSendType" SG_ 1626 BCM1_LDS_Stellung 3;
BA_ "GenSigSwitchedByIgnition" SG_ 1626 BCM1_LDS_Stellung 0;
BA_ "Fehlerwert" SG_ 1626 BCM1_LDS_Stellung 7;
BA_ "GenSigSendType" SG_ 1626 BCM1_Lenksaeule_aktiv 3;
BA_ "GenSigSwitchedByIgnition" SG_ 1626 BCM1_Lenksaeule_aktiv 0;
BA_ "GenSigSendType" SG_ 1626 BCM1_Licht_Warn 3;
BA_ "GenSigSwitchedByIgnition" SG_ 1626 BCM1_Licht_Warn 0;
BA_ "GenSigSendType" SG_ 1626 BCM1_Lichtwarn_Texte 3;
BA_ "GenSigSwitchedByIgnition" SG_ 1626 BCM1_Lichtwarn_Texte 0;
BA_ "GenSigSendType" SG_ 1626 BCM1_MH_Schalter 3;
BA_ "GenSigSwitchedByIgnition" SG_ 1626 BCM1_MH_Schalter 0;
BA_ "GenSigSendType" SG_ 1626 BCM1_MH_WIV_Schalter 3;
BA_ "GenSigSwitchedByIgnition" SG_ 1626 BCM1_MH_WIV_Schalter 0;
BA_ "GenSigActiveRepetitions" SG_ 1626 BCM1_NV_Taster 10;
BA_ "GenSigSendType" SG_ 1626 BCM1_NV_Taster 4;
BA_ "GenSigSwitchedByIgnition" SG_ 1626 BCM1_NV_Taster 0;
BA_ "GenSigSendType" SG_ 1626 BCM1_Reisemodus_Texte 3;
BA_ "GenSigSwitchedByIgnition" SG_ 1626 BCM1_Reisemodus_Texte 0;
BA_ "GenSigSendType" SG_ 1626 BCM1_Rueckfahrlicht_Schalter 3;
BA_ "GenSigSwitchedByIgnition" SG_ 1626 BCM1_Rueckfahrlicht_Schalter 0;
BA_ "GenSigSendType" SG_ 1626 BCM1_Schluesselsuche_Anf 0;
BA_ "GenSigSwitchedByIgnition" SG_ 1626 BCM1_Schluesselsuche_Anf 0;
BA_ "GenSigSendType" SG_ 1626 BCM1_St_SW_Diebstahl_links 3;
BA_ "GenSigSwitchedByIgnition" SG_ 1626 BCM1_St_SW_Diebstahl_links 0;
BA_ "GenSigSendType" SG_ 1626 BCM1_St_SW_Diebstahl_rechts 3;
BA_ "GenSigSwitchedByIgnition" SG_ 1626 BCM1_St_SW_Diebstahl_rechts 0;
BA_ "GenSigActiveRepetitions" SG_ 1626 BCM1_Valet_Parking_Taster 10;
BA_ "GenSigSendType" SG_ 1626 BCM1_Valet_Parking_Taster 4;
BA_ "GenSigSwitchedByIgnition" SG_ 1626 BCM1_Valet_Parking_Taster 0;
BA_ "GenSigActiveRepetitions" SG_ 1626 BCM1_Warnblink_Taster 10;
BA_ "GenSigSendType" SG_ 1626 BCM1_Warnblink_Taster 4;
BA_ "GenSigSwitchedByIgnition" SG_ 1626 BCM1_Warnblink_Taster 0;
BA_ "GenSigSendType" SG_ 1626 BCM_Bremsbelag_Sensor 3;
BA_ "GenSigSwitchedByIgnition" SG_ 1626 BCM_Bremsbelag_Sensor 0;
BA_ "GenSigSendType" SG_ 1626 BCM_Bremsfluessigkeit_Sensor 3;
BA_ "GenSigSwitchedByIgnition" SG_ 1626 BCM_Bremsfluessigkeit_Sensor 0;
BA_ "GenSigSendType" SG_ 1626 BCM_Eco_Charisma_Taste 3;
BA_ "GenSigSwitchedByIgnition" SG_ 1626 BCM_Eco_Charisma_Taste 0;
BA_ "GenSigSendType" SG_ 1626 BCM_HDF_betaetigt 3;
BA_ "GenSigSwitchedByIgnition" SG_ 1626 BCM_HDF_betaetigt 0;
BA_ "GenSigActiveRepetitions" SG_ 1626 BCM_Hybrid_StartStopp_Taste 10;
BA_ "GenSigSendType" SG_ 1626 BCM_Hybrid_StartStopp_Taste 4;
BA_ "GenSigSwitchedByIgnition" SG_ 1626 BCM_Hybrid_StartStopp_Taste 0;
BA_ "GenSigSendType" SG_ 1626 BCM_Hybrid_StSt_Taste_Fehler 0;
BA_ "GenSigSwitchedByIgnition" SG_ 1626 BCM_Hybrid_StSt_Taste_Fehler 0;
BA_ "GenSigSendType" SG_ 1626 BCM_Kuehlmittel_Sensor 3;
BA_ "GenSigSwitchedByIgnition" SG_ 1626 BCM_Kuehlmittel_Sensor 0;
BA_ "GenSigSendType" SG_ 1626 BCM_Kuehlmittel_Sensor_02 3;
BA_ "GenSigSwitchedByIgnition" SG_ 1626 BCM_Kuehlmittel_Sensor_02 0;
BA_ "GenSigSendType" SG_ 1626 BCM_Offroad_Taste 3;
BA_ "GenSigSwitchedByIgnition" SG_ 1626 BCM_Offroad_Taste 0;
BA_ "GenSigSendType" SG_ 1626 BCM_Waschwasser_Sensor 3;
BA_ "GenSigSwitchedByIgnition" SG_ 1626 BCM_Waschwasser_Sensor 0;
BA_ "GenSigSendType" SG_ 1626 Gong_TFL_Umschaltung 3;
BA_ "GenSigSwitchedByIgnition" SG_ 1626 Gong_TFL_Umschaltung 0;
BA_ "GenSigSendType" SG_ 1626 ISP_Dimmung_ASP_02 3;
BA_ "GenSigSendType" SG_ 1626 UGDO_Function_01 3;
BA_ "Fehlerwert" SG_ 1626 UGDO_Function_01 7;
BA_ "GenSigSendType" SG_ 401 BMS_01_BZ 0;
BA_ "GenSigFuncType" SG_ 401 BMS_01_BZ 1;
BA_ "GenSigSwitchedByIgnition" SG_ 401 BMS_01_BZ 0;
BA_ "GenSigSendType" SG_ 401 BMS_01_CRC 0;
BA_ "GenSigFuncType" SG_ 401 BMS_01_CRC 2;
BA_ "GenSigSwitchedByIgnition" SG_ 401 BMS_01_CRC 0;
BA_ "GenSigSendType" SG_ 401 BMS_IstSpannung 0;
BA_ "GenSigStartValue" SG_ 401 BMS_IstSpannung 4094;
BA_ "GenSigSwitchedByIgnition" SG_ 401 BMS_IstSpannung 0;
BA_ "Fehlerwert" SG_ 401 BMS_IstSpannung 4095;
BA_ "GenSigSendType" SG_ 401 BMS_IstStrom_02 0;
BA_ "GenSigStartValue" SG_ 401 BMS_IstStrom_02 4094;
BA_ "GenSigSwitchedByIgnition" SG_ 401 BMS_IstStrom_02 0;
BA_ "Fehlerwert" SG_ 401 BMS_IstStrom_02 4095;
BA_ "GenSigSendType" SG_ 401 BMS_IstStrom_02_Offset 0;
BA_ "GenSigSwitchedByIgnition" SG_ 401 BMS_IstStrom_02_Offset 0;
BA_ "GenSigSendType" SG_ 401 BMS_IstStrom_02_OffsetVZ 0;
BA_ "GenSigSwitchedByIgnition" SG_ 401 BMS_IstStrom_02_OffsetVZ 0;
BA_ "GenSigSendType" SG_ 401 BMS_SOC_HiRes 0;
BA_ "GenSigStartValue" SG_ 401 BMS_SOC_HiRes 2046;
BA_ "GenSigSwitchedByIgnition" SG_ 401 BMS_SOC_HiRes 0;
BA_ "Fehlerwert" SG_ 401 BMS_SOC_HiRes 2047;
BA_ "GenSigSendType" SG_ 401 BMS_Spannung_ZwKr 0;
BA_ "GenSigStartValue" SG_ 401 BMS_Spannung_ZwKr 2046;
BA_ "GenSigSwitchedByIgnition" SG_ 401 BMS_Spannung_ZwKr 0;
BA_ "Fehlerwert" SG_ 401 BMS_Spannung_ZwKr 2047;
BA_ "GenSigSendType" SG_ 417 BMS_MaxDyn_EntladeStrom_02 0;
BA_ "GenSigStartValue" SG_ 417 BMS_MaxDyn_EntladeStrom_02 2046;
BA_ "GenSigSwitchedByIgnition" SG_ 417 BMS_MaxDyn_EntladeStrom_02 0;
BA_ "Fehlerwert" SG_ 417 BMS_MaxDyn_EntladeStrom_02 2047;
BA_ "GenSigSendType" SG_ 417 BMS_MaxDyn_LadeStrom_02 0;
BA_ "GenSigStartValue" SG_ 417 BMS_MaxDyn_LadeStrom_02 2046;
BA_ "GenSigSwitchedByIgnition" SG_ 417 BMS_MaxDyn_LadeStrom_02 0;
BA_ "Fehlerwert" SG_ 417 BMS_MaxDyn_LadeStrom_02 2047;
BA_ "GenSigSendType" SG_ 417 BMS_MaxDyn_LadeStrom_02_Offset 0;
BA_ "GenSigSwitchedByIgnition" SG_ 417 BMS_MaxDyn_LadeStrom_02_Offset 0;
BA_ "GenSigSendType" SG_ 417 BMS_Min_EntladeSpannung 0;
BA_ "GenSigStartValue" SG_ 417 BMS_Min_EntladeSpannung 1022;
BA_ "GenSigSwitchedByIgnition" SG_ 417 BMS_Min_EntladeSpannung 0;
BA_ "Fehlerwert" SG_ 417 BMS_Min_EntladeSpannung 1023;
BA_ "GenSigSendType" SG_ 417 BMS_MinDyn_EntladeSpannung 0;
BA_ "GenSigStartValue" SG_ 417 BMS_MinDyn_EntladeSpannung 1023;
BA_ "GenSigSwitchedByIgnition" SG_ 417 BMS_MinDyn_EntladeSpannung 0;
BA_ "GenSigSendType" SG_ 417 BMS_MinDyn_LadeSpannung 0;
BA_ "GenSigStartValue" SG_ 417 BMS_MinDyn_LadeSpannung 1023;
BA_ "GenSigSwitchedByIgnition" SG_ 417 BMS_MinDyn_LadeSpannung 0;
BA_ "GenSigSendType" SG_ 925 BMS_Leerlaufspannung 0;
BA_ "GenSigStartValue" SG_ 925 BMS_Leerlaufspannung 1023;
BA_ "GenSigSwitchedByIgnition" SG_ 925 BMS_Leerlaufspannung 0;
BA_ "GenSigSendType" SG_ 925 BMS_Max_LadeSpannung 0;
BA_ "GenSigStartValue" SG_ 925 BMS_Max_LadeSpannung 1022;
BA_ "GenSigSwitchedByIgnition" SG_ 925 BMS_Max_LadeSpannung 0;
BA_ "Fehlerwert" SG_ 925 BMS_Max_LadeSpannung 1023;
BA_ "GenSigSendType" SG_ 925 BMS_MaxPred_EntladeStrom_02 0;
BA_ "GenSigStartValue" SG_ 925 BMS_MaxPred_EntladeStrom_02 2046;
BA_ "GenSigSwitchedByIgnition" SG_ 925 BMS_MaxPred_EntladeStrom_02 0;
BA_ "Fehlerwert" SG_ 925 BMS_MaxPred_EntladeStrom_02 2047;
BA_ "GenSigSendType" SG_ 925 BMS_MaxPred_LadeStrom_02 0;
BA_ "GenSigStartValue" SG_ 925 BMS_MaxPred_LadeStrom_02 2046;
BA_ "GenSigSwitchedByIgnition" SG_ 925 BMS_MaxPred_LadeStrom_02 0;
BA_ "Fehlerwert" SG_ 925 BMS_MaxPred_LadeStrom_02 2047;
BA_ "GenSigSendType" SG_ 925 BMS_MinPred_EntladeSpannung 0;
BA_ "GenSigStartValue" SG_ 925 BMS_MinPred_EntladeSpannung 1023;
BA_ "GenSigSwitchedByIgnition" SG_ 925 BMS_MinPred_EntladeSpannung 0;
BA_ "GenSigSendType" SG_ 925 BMS_MinPred_LadeSpannung 0;
BA_ "GenSigStartValue" SG_ 925 BMS_MinPred_LadeSpannung 1023;
BA_ "GenSigSwitchedByIgnition" SG_ 925 BMS_MinPred_LadeSpannung 0;
BA_ "GenSigSendType" SG_ 1442 BMS_04_BZ 0;
BA_ "GenSigFuncType" SG_ 1442 BMS_04_BZ 1;
BA_ "GenSigSwitchedByIgnition" SG_ 1442 BMS_04_BZ 0;
BA_ "GenSigSendType" SG_ 1442 BMS_04_CRC 0;
BA_ "GenSigFuncType" SG_ 1442 BMS_04_CRC 2;
BA_ "GenSigSwitchedByIgnition" SG_ 1442 BMS_04_CRC 0;
BA_ "GenSigSendType" SG_ 1442 BMS_Abschaltankuendigung 0;
BA_ "GenSigStartValue" SG_ 1442 BMS_Abschaltankuendigung 1022;
BA_ "Fehlerwert" SG_ 1442 BMS_Abschaltankuendigung 1023;
BA_ "GenSigSendType" SG_ 1442 BMS_Fehlerstatus 3;
BA_ "GenSigStartValue" SG_ 1442 BMS_Fehlerstatus 7;
BA_ "GenSigSwitchedByIgnition" SG_ 1442 BMS_Fehlerstatus 0;
BA_ "GenSigSendType" SG_ 1442 BMS_IstModus 3;
BA_ "GenSigStartValue" SG_ 1442 BMS_IstModus 7;
BA_ "GenSigSwitchedByIgnition" SG_ 1442 BMS_IstModus 0;
BA_ "GenSigSendType" SG_ 1442 BMS_Kapazitaet_02 0;
BA_ "GenSigStartValue" SG_ 1442 BMS_Kapazitaet_02 2047;
BA_ "GenSigSwitchedByIgnition" SG_ 1442 BMS_Kapazitaet_02 0;
BA_ "GenSigSendType" SG_ 1442 BMS_OBD_Lampe_Anf 0;
BA_ "GenSigSwitchedByIgnition" SG_ 1442 BMS_OBD_Lampe_Anf 0;
BA_ "GenSigSendType" SG_ 1442 BMS_Soll_SOC_HiRes 3;
BA_ "GenSigStartValue" SG_ 1442 BMS_Soll_SOC_HiRes 2046;
BA_ "GenSigSwitchedByIgnition" SG_ 1442 BMS_Soll_SOC_HiRes 0;
BA_ "Fehlerwert" SG_ 1442 BMS_Soll_SOC_HiRes 2047;
BA_ "GenSigSendType" SG_ 1442 BMS_Status_ServiceDisconnect 0;
BA_ "GenSigSwitchedByIgnition" SG_ 1442 BMS_Status_ServiceDisconnect 0;
BA_ "GenSigSendType" SG_ 1442 BMS_Status_Spgfreiheit 0;
BA_ "GenSigSwitchedByIgnition" SG_ 1442 BMS_Status_Spgfreiheit 0;
BA_ "GenSigSendType" SG_ 687 BMS_As_Entladezaehler 0;
BA_ "GenSigSwitchedByIgnition" SG_ 687 BMS_As_Entladezaehler 0;
BA_ "GenSigSendType" SG_ 687 BMS_As_Entladezaehler_Ueberlauf 0;
BA_ "GenSigSwitchedByIgnition" SG_ 687 BMS_As_Entladezaehler_Ueberlauf 0;
BA_ "GenSigSendType" SG_ 687 BMS_Rekuperation 0;
BA_ "GenSigSwitchedByIgnition" SG_ 687 BMS_Rekuperation 0;
BA_ "GenSigSendType" SG_ 687 BMS_Rekuperation_Ueberlauf 0;
BA_ "GenSigSwitchedByIgnition" SG_ 687 BMS_Rekuperation_Ueberlauf 0;
BA_ "GenSigSendType" SG_ 687 BMS_Verbrauch 0;
BA_ "GenSigSwitchedByIgnition" SG_ 687 BMS_Verbrauch 0;
BA_ "GenSigSendType" SG_ 687 BMS_Verbrauch_Ueberlauf 0;
BA_ "GenSigSwitchedByIgnition" SG_ 687 BMS_Verbrauch_Ueberlauf 0;
BA_ "GenSigSendType" SG_ 1438 BMS_Batterie_Voko_Anf 0;
BA_ "GenSigSwitchedByIgnition" SG_ 1438 BMS_Batterie_Voko_Anf 0;
BA_ "GenSigSendType" SG_ 1438 BMS_Fehler_NTKreis 0;
BA_ "GenSigSwitchedByIgnition" SG_ 1438 BMS_Fehler_NTKreis 0;
BA_ "Fehlerwert" SG_ 1438 BMS_Fehler_NTKreis 1;
BA_ "GenSigSendType" SG_ 1438 BMS_Fehlerstatus_EWP_02 0;
BA_ "GenSigSwitchedByIgnition" SG_ 1438 BMS_Fehlerstatus_EWP_02 0;
BA_ "Fehlerwert" SG_ 1438 BMS_Fehlerstatus_EWP_02 7;
BA_ "GenSigSendType" SG_ 1438 BMS_IstRuecklaufTemperatur_02 0;
BA_ "GenSigStartValue" SG_ 1438 BMS_IstRuecklaufTemperatur_02 254;
BA_ "GenSigSwitchedByIgnition" SG_ 1438 BMS_IstRuecklaufTemperatur_02 0;
BA_ "Fehlerwert" SG_ 1438 BMS_IstRuecklaufTemperatur_02 255;
BA_ "GenSigSendType" SG_ 1438 BMS_IstVorlaufTemperatur 0;
BA_ "GenSigStartValue" SG_ 1438 BMS_IstVorlaufTemperatur 254;
BA_ "GenSigSwitchedByIgnition" SG_ 1438 BMS_IstVorlaufTemperatur 0;
BA_ "Fehlerwert" SG_ 1438 BMS_IstVorlaufTemperatur 255;
BA_ "GenSigSendType" SG_ 1438 BMS_Soll_PWM_Pumpe 0;
BA_ "GenSigStartValue" SG_ 1438 BMS_Soll_PWM_Pumpe 15;
BA_ "GenSigSwitchedByIgnition" SG_ 1438 BMS_Soll_PWM_Pumpe 0;
BA_ "Fehlerwert" SG_ 1438 BMS_Soll_PWM_Pumpe 14;
BA_ "GenSigSendType" SG_ 1438 BMS_SollVolumenstrom 0;
BA_ "GenSigStartValue" SG_ 1438 BMS_SollVolumenstrom 62;
BA_ "GenSigSwitchedByIgnition" SG_ 1438 BMS_SollVolumenstrom 0;
BA_ "Fehlerwert" SG_ 1438 BMS_SollVolumenstrom 63;
BA_ "GenSigSendType" SG_ 1438 BMS_SollVorlauftemperatur 0;
BA_ "GenSigStartValue" SG_ 1438 BMS_SollVorlauftemperatur 254;
BA_ "GenSigSwitchedByIgnition" SG_ 1438 BMS_SollVorlauftemperatur 0;
BA_ "Fehlerwert" SG_ 1438 BMS_SollVorlauftemperatur 255;
BA_ "GenSigSendType" SG_ 1438 BMS_Status_Ventil 0;
BA_ "GenSigStartValue" SG_ 1438 BMS_Status_Ventil 6;
BA_ "GenSigSwitchedByIgnition" SG_ 1438 BMS_Status_Ventil 0;
BA_ "Fehlerwert" SG_ 1438 BMS_Status_Ventil 7;
BA_ "GenSigSendType" SG_ 1438 BMS_Temp_Epsilon 0;
BA_ "GenSigSwitchedByIgnition" SG_ 1438 BMS_Temp_Epsilon 0;
BA_ "GenSigSendType" SG_ 1438 BMS_Temperatur 0;
BA_ "GenSigStartValue" SG_ 1438 BMS_Temperatur 254;
BA_ "GenSigSwitchedByIgnition" SG_ 1438 BMS_Temperatur 0;
BA_ "Fehlerwert" SG_ 1438 BMS_Temperatur 255;
BA_ "GenSigSendType" SG_ 1438 BMS_Temperierung_Anf 0;
BA_ "GenSigStartValue" SG_ 1438 BMS_Temperierung_Anf 3;
BA_ "GenSigSwitchedByIgnition" SG_ 1438 BMS_Temperierung_Anf 0;
BA_ "GenSigSendType" SG_ 1482 BMS_07_BZ 0;
BA_ "GenSigFuncType" SG_ 1482 BMS_07_BZ 1;
BA_ "GenSigSwitchedByIgnition" SG_ 1482 BMS_07_BZ 0;
BA_ "GenSigSendType" SG_ 1482 BMS_07_CRC 0;
BA_ "GenSigFuncType" SG_ 1482 BMS_07_CRC 2;
BA_ "GenSigSwitchedByIgnition" SG_ 1482 BMS_07_CRC 0;
BA_ "GenSigSendType" SG_ 1482 BMS_Ausgleichsladung_Anf 0;
BA_ "GenSigSwitchedByIgnition" SG_ 1482 BMS_Ausgleichsladung_Anf 0;
BA_ "GenSigSendType" SG_ 1482 BMS_Balancing_Aktiv 0;
BA_ "GenSigSwitchedByIgnition" SG_ 1482 BMS_Balancing_Aktiv 0;
BA_ "GenSigSendType" SG_ 1482 BMS_Batteriediagnose 3;
BA_ "GenSigStartValue" SG_ 1482 BMS_Batteriediagnose 1;
BA_ "GenSigSwitchedByIgnition" SG_ 1482 BMS_Batteriediagnose 0;
BA_ "Fehlerwert" SG_ 1482 BMS_Batteriediagnose 7;
BA_ "GenSigSendType" SG_ 1482 BMS_Energieinhalt 0;
BA_ "GenSigStartValue" SG_ 1482 BMS_Energieinhalt 2046;
BA_ "GenSigSwitchedByIgnition" SG_ 1482 BMS_Energieinhalt 0;
BA_ "Fehlerwert" SG_ 1482 BMS_Energieinhalt 2047;
BA_ "GenSigSendType" SG_ 1482 BMS_Fehler_KuehlkreislaufLeckage 3;
BA_ "GenSigSwitchedByIgnition" SG_ 1482 BMS_Fehler_KuehlkreislaufLeckage 0;
BA_ "GenSigSendType" SG_ 1482 BMS_Freig_max_Performanz 3;
BA_ "GenSigSwitchedByIgnition" SG_ 1482 BMS_Freig_max_Performanz 0;
BA_ "GenSigSendType" SG_ 1482 BMS_Gesamtst_Spgfreiheit 3;
BA_ "GenSigSwitchedByIgnition" SG_ 1482 BMS_Gesamtst_Spgfreiheit 0;
BA_ "GenSigSendType" SG_ 1482 BMS_KundenWarnung 3;
BA_ "GenSigSwitchedByIgnition" SG_ 1482 BMS_KundenWarnung 0;
BA_ "GenSigSendType" SG_ 1482 BMS_Ladevorgang_aktiv 0;
BA_ "GenSigSwitchedByIgnition" SG_ 1482 BMS_Ladevorgang_aktiv 0;
BA_ "GenSigSendType" SG_ 1482 BMS_MaxEnergieinhalt 0;
BA_ "GenSigStartValue" SG_ 1482 BMS_MaxEnergieinhalt 2046;
BA_ "GenSigSwitchedByIgnition" SG_ 1482 BMS_MaxEnergieinhalt 0;
BA_ "Fehlerwert" SG_ 1482 BMS_MaxEnergieinhalt 2047;
BA_ "GenSigSendType" SG_ 1482 BMS_RIso_Ext 0;
BA_ "GenSigStartValue" SG_ 1482 BMS_RIso_Ext 4094;
BA_ "GenSigSwitchedByIgnition" SG_ 1482 BMS_RIso_Ext 0;
BA_ "Fehlerwert" SG_ 1482 BMS_RIso_Ext 4095;
BA_ "GenSigSendType" SG_ 2527679979 BMS_BCCM_Anforderung 0;
BA_ "GenSigStartValue" SG_ 2527679979 BMS_BCCM_Anforderung 2;
BA_ "GenSigSwitchedByIgnition" SG_ 2527679979 BMS_BCCM_Anforderung 0;
BA_ "Fehlerwert" SG_ 2527679979 BMS_BCCM_Anforderung 3;
BA_ "GenSigSendType" SG_ 2527679979 BMS_HV_Auszeit 0;
BA_ "GenSigStartValue" SG_ 2527679979 BMS_HV_Auszeit 510;
BA_ "GenSigSwitchedByIgnition" SG_ 2527679979 BMS_HV_Auszeit 0;
BA_ "Fehlerwert" SG_ 2527679979 BMS_HV_Auszeit 511;
BA_ "GenSigSendType" SG_ 2527679979 BMS_HV_Auszeit_Status 0;
BA_ "GenSigSwitchedByIgnition" SG_ 2527679979 BMS_HV_Auszeit_Status 0;
BA_ "GenSigSendType" SG_ 2527679979 BMS_Kapazitaet 0;
BA_ "GenSigStartValue" SG_ 2527679979 BMS_Kapazitaet 2047;
BA_ "GenSigSwitchedByIgnition" SG_ 2527679979 BMS_Kapazitaet 0;
BA_ "GenSigSendType" SG_ 2527679979 BMS_max_Grenz_SOC 0;
BA_ "GenSigStartValue" SG_ 2527679979 BMS_max_Grenz_SOC 31;
BA_ "GenSigSwitchedByIgnition" SG_ 2527679979 BMS_max_Grenz_SOC 0;
BA_ "GenSigSendType" SG_ 2527679979 BMS_min_Grenz_SOC 0;
BA_ "GenSigStartValue" SG_ 2527679979 BMS_min_Grenz_SOC 31;
BA_ "GenSigSwitchedByIgnition" SG_ 2527679979 BMS_min_Grenz_SOC 0;
BA_ "GenSigSendType" SG_ 2527679979 BMS_SOC_Kaltstart 0;
BA_ "GenSigStartValue" SG_ 2527679979 BMS_SOC_Kaltstart 2046;
BA_ "GenSigSwitchedByIgnition" SG_ 2527679979 BMS_SOC_Kaltstart 0;
BA_ "Fehlerwert" SG_ 2527679979 BMS_SOC_Kaltstart 2047;
BA_ "GenSigSendType" SG_ 1289 BMS_Energieinhalt_HiRes 0;
BA_ "GenSigStartValue" SG_ 1289 BMS_Energieinhalt_HiRes 32766;
BA_ "GenSigSwitchedByIgnition" SG_ 1289 BMS_Energieinhalt_HiRes 0;
BA_ "Fehlerwert" SG_ 1289 BMS_Energieinhalt_HiRes 32767;
BA_ "GenSigSendType" SG_ 1289 BMS_MaxEnergieinhalt_HiRes 0;
BA_ "GenSigStartValue" SG_ 1289 BMS_MaxEnergieinhalt_HiRes 32766;
BA_ "GenSigSwitchedByIgnition" SG_ 1289 BMS_MaxEnergieinhalt_HiRes 0;
BA_ "Fehlerwert" SG_ 1289 BMS_MaxEnergieinhalt_HiRes 32767;
BA_ "GenSigSendType" SG_ 1289 BMS_NutzbarerEnergieinhalt 0;
BA_ "GenSigStartValue" SG_ 1289 BMS_NutzbarerEnergieinhalt 4094;
BA_ "GenSigSwitchedByIgnition" SG_ 1289 BMS_NutzbarerEnergieinhalt 0;
BA_ "Fehlerwert" SG_ 1289 BMS_NutzbarerEnergieinhalt 4095;
BA_ "GenSigSendType" SG_ 1289 BMS_NutzbarerSOC 0;
BA_ "GenSigStartValue" SG_ 1289 BMS_NutzbarerSOC 254;
BA_ "GenSigSwitchedByIgnition" SG_ 1289 BMS_NutzbarerSOC 0;
BA_ "Fehlerwert" SG_ 1289 BMS_NutzbarerSOC 255;
BA_ "GenSigSendType" SG_ 1289 BMS_Pred_Entladeperformance 0;
BA_ "GenSigStartValue" SG_ 1289 BMS_Pred_Entladeperformance 126;
BA_ "GenSigSwitchedByIgnition" SG_ 1289 BMS_Pred_Entladeperformance 0;
BA_ "Fehlerwert" SG_ 1289 BMS_Pred_Entladeperformance 127;
BA_ "GenSigSendType" SG_ 1289 BMS_Pred_Ladeperformance 0;
BA_ "GenSigStartValue" SG_ 1289 BMS_Pred_Ladeperformance 126;
BA_ "GenSigSwitchedByIgnition" SG_ 1289 BMS_Pred_Ladeperformance 0;
BA_ "Fehlerwert" SG_ 1289 BMS_Pred_Ladeperformance 127;
BA_ "GenSigSendType" SG_ 2527679654 BMS_IsoFehler 0;
BA_ "GenSigSwitchedByIgnition" SG_ 2527679654 BMS_IsoFehler 0;
BA_ "GenSigSendType" SG_ 2527679654 BMS_IsoZustand 0;
BA_ "GenSigSwitchedByIgnition" SG_ 2527679654 BMS_IsoZustand 0;
BA_ "GenSigSendType" SG_ 2527679654 BMS_IstTemperatur_hoechste 0;
BA_ "GenSigStartValue" SG_ 2527679654 BMS_IstTemperatur_hoechste 254;
BA_ "GenSigSwitchedByIgnition" SG_ 2527679654 BMS_IstTemperatur_hoechste 0;
BA_ "Fehlerwert" SG_ 2527679654 BMS_IstTemperatur_hoechste 255;
BA_ "GenSigSendType" SG_ 2527679654 BMS_IstTemperatur_niedrigste 0;
BA_ "GenSigStartValue" SG_ 2527679654 BMS_IstTemperatur_niedrigste 254;
BA_ "GenSigSwitchedByIgnition" SG_ 2527679654 BMS_IstTemperatur_niedrigste 0;
BA_ "Fehlerwert" SG_ 2527679654 BMS_IstTemperatur_niedrigste 255;
BA_ "GenSigSendType" SG_ 2527679654 BMS_IstZellspannung_hoechste 0;
BA_ "GenSigStartValue" SG_ 2527679654 BMS_IstZellspannung_hoechste 4094;
BA_ "GenSigSwitchedByIgnition" SG_ 2527679654 BMS_IstZellspannung_hoechste 0;
BA_ "Fehlerwert" SG_ 2527679654 BMS_IstZellspannung_hoechste 4095;
BA_ "GenSigSendType" SG_ 2527679654 BMS_IstZellspannung_niedrigste 0;
BA_ "GenSigStartValue" SG_ 2527679654 BMS_IstZellspannung_niedrigste 4094;
BA_ "GenSigSwitchedByIgnition" SG_ 2527679654 BMS_IstZellspannung_niedrigste 0;
BA_ "Fehlerwert" SG_ 2527679654 BMS_IstZellspannung_niedrigste 4095;
BA_ "GenSigSendType" SG_ 2589283637 BMS_Pack_SN_01 0;
BA_ "GenSigStartValue" SG_ 2589283637 BMS_Pack_SN_01 255;
BA_ "GenSigSwitchedByIgnition" SG_ 2589283637 BMS_Pack_SN_01 0;
BA_ "GenSigSendType" SG_ 2589283637 BMS_Pack_SN_02 0;
BA_ "GenSigStartValue" SG_ 2589283637 BMS_Pack_SN_02 255;
BA_ "GenSigSwitchedByIgnition" SG_ 2589283637 BMS_Pack_SN_02 0;
BA_ "GenSigSendType" SG_ 2589283637 BMS_Pack_SN_03 0;
BA_ "GenSigStartValue" SG_ 2589283637 BMS_Pack_SN_03 255;
BA_ "GenSigSwitchedByIgnition" SG_ 2589283637 BMS_Pack_SN_03 0;
BA_ "GenSigSendType" SG_ 2589283637 BMS_Pack_SN_04 0;
BA_ "GenSigStartValue" SG_ 2589283637 BMS_Pack_SN_04 255;
BA_ "GenSigSwitchedByIgnition" SG_ 2589283637 BMS_Pack_SN_04 0;
BA_ "GenSigSendType" SG_ 2589283637 BMS_Pack_SN_05 0;
BA_ "GenSigStartValue" SG_ 2589283637 BMS_Pack_SN_05 255;
BA_ "GenSigSwitchedByIgnition" SG_ 2589283637 BMS_Pack_SN_05 0;
BA_ "GenSigSendType" SG_ 2589283637 BMS_Pack_SN_06 0;
BA_ "GenSigStartValue" SG_ 2589283637 BMS_Pack_SN_06 255;
BA_ "GenSigSwitchedByIgnition" SG_ 2589283637 BMS_Pack_SN_06 0;
BA_ "GenSigSendType" SG_ 2589283637 BMS_Pack_SN_07 0;
BA_ "GenSigStartValue" SG_ 2589283637 BMS_Pack_SN_07 255;
BA_ "GenSigSwitchedByIgnition" SG_ 2589283637 BMS_Pack_SN_07 0;
BA_ "GenSigSendType" SG_ 2589283637 BMS_Pack_SN_08 0;
BA_ "GenSigStartValue" SG_ 2589283637 BMS_Pack_SN_08 255;
BA_ "GenSigSwitchedByIgnition" SG_ 2589283637 BMS_Pack_SN_08 0;
BA_ "GenSigSendType" SG_ 2589283638 BMS_Pack_SN_09 0;
BA_ "GenSigStartValue" SG_ 2589283638 BMS_Pack_SN_09 255;
BA_ "GenSigSwitchedByIgnition" SG_ 2589283638 BMS_Pack_SN_09 0;
BA_ "GenSigSendType" SG_ 2589283638 BMS_Pack_SN_10 0;
BA_ "GenSigStartValue" SG_ 2589283638 BMS_Pack_SN_10 255;
BA_ "GenSigSwitchedByIgnition" SG_ 2589283638 BMS_Pack_SN_10 0;
BA_ "GenSigSendType" SG_ 2589283638 BMS_Pack_SN_11 0;
BA_ "GenSigStartValue" SG_ 2589283638 BMS_Pack_SN_11 255;
BA_ "GenSigSwitchedByIgnition" SG_ 2589283638 BMS_Pack_SN_11 0;
BA_ "GenSigSendType" SG_ 2589283638 BMS_Pack_SN_12 0;
BA_ "GenSigStartValue" SG_ 2589283638 BMS_Pack_SN_12 255;
BA_ "GenSigSwitchedByIgnition" SG_ 2589283638 BMS_Pack_SN_12 0;
BA_ "GenSigSendType" SG_ 2589283638 BMS_Pack_SN_13 0;
BA_ "GenSigStartValue" SG_ 2589283638 BMS_Pack_SN_13 255;
BA_ "GenSigSwitchedByIgnition" SG_ 2589283638 BMS_Pack_SN_13 0;
BA_ "GenSigSendType" SG_ 2589283638 BMS_Pack_SN_14 0;
BA_ "GenSigStartValue" SG_ 2589283638 BMS_Pack_SN_14 255;
BA_ "GenSigSwitchedByIgnition" SG_ 2589283638 BMS_Pack_SN_14 0;
BA_ "GenSigSendType" SG_ 2589283638 BMS_Pack_SN_15 0;
BA_ "GenSigStartValue" SG_ 2589283638 BMS_Pack_SN_15 255;
BA_ "GenSigSwitchedByIgnition" SG_ 2589283638 BMS_Pack_SN_15 0;
BA_ "GenSigSendType" SG_ 2589283638 BMS_Pack_SN_16 0;
BA_ "GenSigStartValue" SG_ 2589283638 BMS_Pack_SN_16 255;
BA_ "GenSigSwitchedByIgnition" SG_ 2589283638 BMS_Pack_SN_16 0;
BA_ "GenSigSendType" SG_ 1111 BMS_14_BZ 0;
BA_ "GenSigFuncType" SG_ 1111 BMS_14_BZ 1;
BA_ "GenSigSwitchedByIgnition" SG_ 1111 BMS_14_BZ 0;
BA_ "GenSigSendType" SG_ 1111 BMS_14_CRC 0;
BA_ "GenSigFuncType" SG_ 1111 BMS_14_CRC 2;
BA_ "GenSigSwitchedByIgnition" SG_ 1111 BMS_14_CRC 0;
BA_ "GenSigSendType" SG_ 1111 BMS_RIso_GND_HVM 0;
BA_ "GenSigStartValue" SG_ 1111 BMS_RIso_GND_HVM 4094;
BA_ "GenSigSwitchedByIgnition" SG_ 1111 BMS_RIso_GND_HVM 0;
BA_ "Fehlerwert" SG_ 1111 BMS_RIso_GND_HVM 4095;
BA_ "GenSigSendType" SG_ 1111 BMS_RIso_GND_HVP 0;
BA_ "GenSigStartValue" SG_ 1111 BMS_RIso_GND_HVP 4094;
BA_ "GenSigSwitchedByIgnition" SG_ 1111 BMS_RIso_GND_HVP 0;
BA_ "Fehlerwert" SG_ 1111 BMS_RIso_GND_HVP 4095;
BA_ "GenSigSendType" SG_ 1111 BMS_Spannung_ZwKr2 0;
BA_ "GenSigStartValue" SG_ 1111 BMS_Spannung_ZwKr2 2046;
BA_ "GenSigSwitchedByIgnition" SG_ 1111 BMS_Spannung_ZwKr2 0;
BA_ "Fehlerwert" SG_ 1111 BMS_Spannung_ZwKr2 2047;
BA_ "GenSigSendType" SG_ 1111 BMS_Warnung_Stuetzung_NV 0;
BA_ "GenSigStartValue" SG_ 1111 BMS_Warnung_Stuetzung_NV 6;
BA_ "GenSigSwitchedByIgnition" SG_ 1111 BMS_Warnung_Stuetzung_NV 0;
BA_ "Fehlerwert" SG_ 1111 BMS_Warnung_Stuetzung_NV 7;
BA_ "GenSigSendType" SG_ 2589283877 BMS_Pack_SN_17 0;
BA_ "GenSigStartValue" SG_ 2589283877 BMS_Pack_SN_17 255;
BA_ "GenSigSwitchedByIgnition" SG_ 2589283877 BMS_Pack_SN_17 0;
BA_ "GenSigSendType" SG_ 2589283877 BMS_Pack_SN_18 0;
BA_ "GenSigStartValue" SG_ 2589283877 BMS_Pack_SN_18 255;
BA_ "GenSigSwitchedByIgnition" SG_ 2589283877 BMS_Pack_SN_18 0;
BA_ "GenSigSendType" SG_ 2589283877 BMS_Pack_SN_19 0;
BA_ "GenSigStartValue" SG_ 2589283877 BMS_Pack_SN_19 255;
BA_ "GenSigSwitchedByIgnition" SG_ 2589283877 BMS_Pack_SN_19 0;
BA_ "GenSigSendType" SG_ 2589283877 BMS_Pack_SN_20 0;
BA_ "GenSigStartValue" SG_ 2589283877 BMS_Pack_SN_20 255;
BA_ "GenSigSwitchedByIgnition" SG_ 2589283877 BMS_Pack_SN_20 0;
BA_ "GenSigSendType" SG_ 2589283877 BMS_Pack_SN_21 0;
BA_ "GenSigStartValue" SG_ 2589283877 BMS_Pack_SN_21 255;
BA_ "GenSigSwitchedByIgnition" SG_ 2589283877 BMS_Pack_SN_21 0;
BA_ "GenSigSendType" SG_ 2589283877 BMS_Pack_SN_22 0;
BA_ "GenSigStartValue" SG_ 2589283877 BMS_Pack_SN_22 255;
BA_ "GenSigSwitchedByIgnition" SG_ 2589283877 BMS_Pack_SN_22 0;
BA_ "GenSigSendType" SG_ 2589283877 BMS_Pack_SN_23 0;
BA_ "GenSigStartValue" SG_ 2589283877 BMS_Pack_SN_23 255;
BA_ "GenSigSwitchedByIgnition" SG_ 2589283877 BMS_Pack_SN_23 0;
BA_ "GenSigSendType" SG_ 2589283877 BMS_Pack_SN_24 0;
BA_ "GenSigStartValue" SG_ 2589283877 BMS_Pack_SN_24 255;
BA_ "GenSigSwitchedByIgnition" SG_ 2589283877 BMS_Pack_SN_24 0;
BA_ "GenSigSendType" SG_ 2589283641 BMS_IstTemperaturMax_Modul_ID 0;
BA_ "GenSigStartValue" SG_ 2589283641 BMS_IstTemperaturMax_Modul_ID 255;
BA_ "GenSigSwitchedByIgnition" SG_ 2589283641 BMS_IstTemperaturMax_Modul_ID 0;
BA_ "GenSigSendType" SG_ 2589283641 BMS_IstTemperaturMax_Sensor_ID 0;
BA_ "GenSigStartValue" SG_ 2589283641 BMS_IstTemperaturMax_Sensor_ID 31;
BA_ "GenSigSwitchedByIgnition" SG_ 2589283641 BMS_IstTemperaturMax_Sensor_ID 0;
BA_ "GenSigSendType" SG_ 2589283641 BMS_IstTemperaturMin_Modul_ID 0;
BA_ "GenSigStartValue" SG_ 2589283641 BMS_IstTemperaturMin_Modul_ID 255;
BA_ "GenSigSwitchedByIgnition" SG_ 2589283641 BMS_IstTemperaturMin_Modul_ID 0;
BA_ "GenSigSendType" SG_ 2589283641 BMS_IstTemperaturMin_Sensor_ID 0;
BA_ "GenSigStartValue" SG_ 2589283641 BMS_IstTemperaturMin_Sensor_ID 31;
BA_ "GenSigSwitchedByIgnition" SG_ 2589283641 BMS_IstTemperaturMin_Sensor_ID 0;
BA_ "GenSigSendType" SG_ 2589283641 BMS_IstZellSpannungMax_Modul_ID 0;
BA_ "GenSigStartValue" SG_ 2589283641 BMS_IstZellSpannungMax_Modul_ID 255;
BA_ "GenSigSwitchedByIgnition" SG_ 2589283641 BMS_IstZellSpannungMax_Modul_ID 0;
BA_ "GenSigSendType" SG_ 2589283641 BMS_IstZellSpannungMax_Zell_ID 0;
BA_ "GenSigStartValue" SG_ 2589283641 BMS_IstZellSpannungMax_Zell_ID 255;
BA_ "GenSigSwitchedByIgnition" SG_ 2589283641 BMS_IstZellSpannungMax_Zell_ID 0;
BA_ "GenSigSendType" SG_ 2589283641 BMS_IstZellSpannungMin_Modul_ID 0;
BA_ "GenSigStartValue" SG_ 2589283641 BMS_IstZellSpannungMin_Modul_ID 255;
BA_ "GenSigSwitchedByIgnition" SG_ 2589283641 BMS_IstZellSpannungMin_Modul_ID 0;
BA_ "GenSigSendType" SG_ 2589283641 BMS_IstZellSpannungMin_Zell_ID 0;
BA_ "GenSigStartValue" SG_ 2589283641 BMS_IstZellSpannungMin_Zell_ID 255;
BA_ "GenSigSwitchedByIgnition" SG_ 2589283641 BMS_IstZellSpannungMin_Zell_ID 0;
BA_ "GenSigSendType" SG_ 2589283651 BMS_RtmWarnBattUnautorisiert 0;
BA_ "GenSigSwitchedByIgnition" SG_ 2589283651 BMS_RtmWarnBattUnautorisiert 0;
BA_ "GenSigSendType" SG_ 2589283651 BMS_RtmWarnPackKommunikation 0;
BA_ "GenSigSwitchedByIgnition" SG_ 2589283651 BMS_RtmWarnPackKommunikation 0;
BA_ "GenSigSendType" SG_ 2589283651 BMS_RtmWarnPackUeberladen 0;
BA_ "GenSigSwitchedByIgnition" SG_ 2589283651 BMS_RtmWarnPackUeberladen 0;
BA_ "GenSigSendType" SG_ 2589283651 BMS_RtmWarnSocHoch 0;
BA_ "GenSigSwitchedByIgnition" SG_ 2589283651 BMS_RtmWarnSocHoch 0;
BA_ "GenSigSendType" SG_ 2589283651 BMS_RtmWarnSocNiedrig 0;
BA_ "GenSigSwitchedByIgnition" SG_ 2589283651 BMS_RtmWarnSocNiedrig 0;
BA_ "GenSigSendType" SG_ 2589283651 BMS_RtmWarnSocSprung 0;
BA_ "GenSigSwitchedByIgnition" SG_ 2589283651 BMS_RtmWarnSocSprung 0;
BA_ "GenSigSendType" SG_ 2589283651 BMS_RtmWarnTZelleDiff 0;
BA_ "GenSigSwitchedByIgnition" SG_ 2589283651 BMS_RtmWarnTZelleDiff 0;
BA_ "GenSigSendType" SG_ 2589283651 BMS_RtmWarnTZelleMax 0;
BA_ "GenSigSwitchedByIgnition" SG_ 2589283651 BMS_RtmWarnTZelleMax 0;
BA_ "GenSigSendType" SG_ 2589283651 BMS_RtmWarnTZelleMin 0;
BA_ "GenSigSwitchedByIgnition" SG_ 2589283651 BMS_RtmWarnTZelleMin 0;
BA_ "GenSigSendType" SG_ 2589283651 BMS_RtmWarnUeberstrom 0;
BA_ "GenSigSwitchedByIgnition" SG_ 2589283651 BMS_RtmWarnUeberstrom 0;
BA_ "GenSigSendType" SG_ 2589283651 BMS_RtmWarnUPackMax 0;
BA_ "GenSigSwitchedByIgnition" SG_ 2589283651 BMS_RtmWarnUPackMax 0;
BA_ "GenSigSendType" SG_ 2589283651 BMS_RtmWarnUPackMin 0;
BA_ "GenSigSwitchedByIgnition" SG_ 2589283651 BMS_RtmWarnUPackMin 0;
BA_ "GenSigSendType" SG_ 2589283651 BMS_RtmWarnUZelleMax 0;
BA_ "GenSigSwitchedByIgnition" SG_ 2589283651 BMS_RtmWarnUZelleMax 0;
BA_ "GenSigSendType" SG_ 2589283651 BMS_RtmWarnUZelleMin 0;
BA_ "GenSigSwitchedByIgnition" SG_ 2589283651 BMS_RtmWarnUZelleMin 0;
BA_ "GenSigSendType" SG_ 2589283651 BMS_RtmWarnZelleZustand 0;
BA_ "GenSigSwitchedByIgnition" SG_ 2589283651 BMS_RtmWarnZelleZustand 0;
BA_ "GenSigSendType" SG_ 2589283652 BMS_18_BZ 0;
BA_ "GenSigFuncType" SG_ 2589283652 BMS_18_BZ 1;
BA_ "GenSigSwitchedByIgnition" SG_ 2589283652 BMS_18_BZ 0;
BA_ "GenSigSendType" SG_ 2589283652 BMS_18_CRC 0;
BA_ "GenSigFuncType" SG_ 2589283652 BMS_18_CRC 2;
BA_ "GenSigSwitchedByIgnition" SG_ 2589283652 BMS_18_CRC 0;
BA_ "GenSigSendType" SG_ 2589283652 BMS_Energie_Entladung 0;
BA_ "GenSigStartValue" SG_ 2589283652 BMS_Energie_Entladung 65534;
BA_ "GenSigSwitchedByIgnition" SG_ 2589283652 BMS_Energie_Entladung 0;
BA_ "Fehlerwert" SG_ 2589283652 BMS_Energie_Entladung 65535;
BA_ "GenSigSendType" SG_ 2589283652 BMS_Energie_Ladung 0;
BA_ "GenSigStartValue" SG_ 2589283652 BMS_Energie_Ladung 65534;
BA_ "GenSigSwitchedByIgnition" SG_ 2589283652 BMS_Energie_Ladung 0;
BA_ "Fehlerwert" SG_ 2589283652 BMS_Energie_Ladung 65535;
BA_ "GenSigSendType" SG_ 2589283652 BMS_Variante_Lambo 0;
BA_ "GenSigSwitchedByIgnition" SG_ 2589283652 BMS_Variante_Lambo 0;
BA_ "GenSigSendType" SG_ 2589283878 BMS_Pack_SN_25 0;
BA_ "GenSigStartValue" SG_ 2589283878 BMS_Pack_SN_25 255;
BA_ "GenSigSwitchedByIgnition" SG_ 2589283878 BMS_Pack_SN_25 0;
BA_ "GenSigSendType" SG_ 2589283878 BMS_Pack_SN_26 0;
BA_ "GenSigStartValue" SG_ 2589283878 BMS_Pack_SN_26 255;
BA_ "GenSigSwitchedByIgnition" SG_ 2589283878 BMS_Pack_SN_26 0;
BA_ "GenSigSendType" SG_ 2589283666 BMS_EnergieAntw_Energie 0;
BA_ "GenSigStartValue" SG_ 2589283666 BMS_EnergieAntw_Energie 2046;
BA_ "GenSigSwitchedByIgnition" SG_ 2589283666 BMS_EnergieAntw_Energie 0;
BA_ "Fehlerwert" SG_ 2589283666 BMS_EnergieAntw_Energie 2047;
BA_ "GenSigSendType" SG_ 2589283666 BMS_EnergieAntw_Zaehler 3;
BA_ "GenSigStartValue" SG_ 2589283666 BMS_EnergieAntw_Zaehler 14;
BA_ "GenSigSwitchedByIgnition" SG_ 2589283666 BMS_EnergieAntw_Zaehler 0;
BA_ "Fehlerwert" SG_ 2589283666 BMS_EnergieAntw_Zaehler 15;
BA_ "GenSigSendType" SG_ 2589283666 BMS_LadegrenzeAntw_Leistung 0;
BA_ "GenSigStartValue" SG_ 2589283666 BMS_LadegrenzeAntw_Leistung 4094;
BA_ "GenSigSwitchedByIgnition" SG_ 2589283666 BMS_LadegrenzeAntw_Leistung 0;
BA_ "Fehlerwert" SG_ 2589283666 BMS_LadegrenzeAntw_Leistung 4095;
BA_ "GenSigSendType" SG_ 2589283666 BMS_LadegrenzeAntw_SOC 0;
BA_ "GenSigStartValue" SG_ 2589283666 BMS_LadegrenzeAntw_SOC 126;
BA_ "GenSigSwitchedByIgnition" SG_ 2589283666 BMS_LadegrenzeAntw_SOC 0;
BA_ "Fehlerwert" SG_ 2589283666 BMS_LadegrenzeAntw_SOC 127;
BA_ "GenSigSendType" SG_ 2589283666 BMS_LadegrenzeAntw_Zaehler 3;
BA_ "GenSigStartValue" SG_ 2589283666 BMS_LadegrenzeAntw_Zaehler 14;
BA_ "GenSigSwitchedByIgnition" SG_ 2589283666 BMS_LadegrenzeAntw_Zaehler 0;
BA_ "Fehlerwert" SG_ 2589283666 BMS_LadegrenzeAntw_Zaehler 15;
BA_ "GenSigSendType" SG_ 2589283666 BMS_MMTR_Status 3;
BA_ "GenSigStartValue" SG_ 2589283666 BMS_MMTR_Status 14;
BA_ "GenSigSwitchedByIgnition" SG_ 2589283666 BMS_MMTR_Status 0;
BA_ "Fehlerwert" SG_ 2589283666 BMS_MMTR_Status 15;
BA_ "GenSigSendType" SG_ 2463978763 BMS_30_BZ 0;
BA_ "GenSigFuncType" SG_ 2463978763 BMS_30_BZ 1;
BA_ "GenSigSwitchedByIgnition" SG_ 2463978763 BMS_30_BZ 0;
BA_ "GenSigSendType" SG_ 2463978763 BMS_30_CRC 0;
BA_ "GenSigFuncType" SG_ 2463978763 BMS_30_CRC 2;
BA_ "GenSigSwitchedByIgnition" SG_ 2463978763 BMS_30_CRC 0;
BA_ "GenSigSendType" SG_ 2463978763 BMS_Ueberspannung_Zelle 0;
BA_ "GenSigStartValue" SG_ 2463978763 BMS_Ueberspannung_Zelle 6;
BA_ "GenSigSwitchedByIgnition" SG_ 2463978763 BMS_Ueberspannung_Zelle 0;
BA_ "Fehlerwert" SG_ 2463978763 BMS_Ueberspannung_Zelle 7;
BA_ "GenSigSendType" SG_ 2463978838 BMS_NutzbarerEnergieinhalt_HiRes 0;
BA_ "GenSigStartValue" SG_ 2463978838 BMS_NutzbarerEnergieinhalt_HiRes 32766;
BA_ "GenSigSwitchedByIgnition" SG_ 2463978838 BMS_NutzbarerEnergieinhalt_HiRes 0;
BA_ "Fehlerwert" SG_ 2463978838 BMS_NutzbarerEnergieinhalt_HiRes 32767;
BA_ "GenSigSendType" SG_ 2463978838 BMS_ZellTemp_virtuell_max 0;
BA_ "GenSigStartValue" SG_ 2463978838 BMS_ZellTemp_virtuell_max 254;
BA_ "GenSigSwitchedByIgnition" SG_ 2463978838 BMS_ZellTemp_virtuell_max 0;
BA_ "Fehlerwert" SG_ 2463978838 BMS_ZellTemp_virtuell_max 255;
BA_ "GenSigSendType" SG_ 2463978838 BMS_ZellTemp_virtuell_min 0;
BA_ "GenSigStartValue" SG_ 2463978838 BMS_ZellTemp_virtuell_min 254;
BA_ "GenSigSwitchedByIgnition" SG_ 2463978838 BMS_ZellTemp_virtuell_min 0;
BA_ "Fehlerwert" SG_ 2463978838 BMS_ZellTemp_virtuell_min 255;
BA_ "GenSigSendType" SG_ 2589283895 BMS_EnergieAntw_Energie_02 0;
BA_ "GenSigStartValue" SG_ 2589283895 BMS_EnergieAntw_Energie_02 16382;
BA_ "GenSigSwitchedByIgnition" SG_ 2589283895 BMS_EnergieAntw_Energie_02 0;
BA_ "Fehlerwert" SG_ 2589283895 BMS_EnergieAntw_Energie_02 16383;
BA_ "GenSigSendType" SG_ 2589283895 BMS_EnergieAntw_Zaehler_02 3;
BA_ "GenSigStartValue" SG_ 2589283895 BMS_EnergieAntw_Zaehler_02 14;
BA_ "GenSigSwitchedByIgnition" SG_ 2589283895 BMS_EnergieAntw_Zaehler_02 0;
BA_ "Fehlerwert" SG_ 2589283895 BMS_EnergieAntw_Zaehler_02 15;
BA_ "GenSigSendType" SG_ 2589283895 BMS_LadegrenzeAntw_Leistung_02 0;
BA_ "GenSigStartValue" SG_ 2589283895 BMS_LadegrenzeAntw_Leistung_02 14;
BA_ "GenSigSwitchedByIgnition" SG_ 2589283895 BMS_LadegrenzeAntw_Leistung_02 0;
BA_ "Fehlerwert" SG_ 2589283895 BMS_LadegrenzeAntw_Leistung_02 4095;
BA_ "GenSigSendType" SG_ 2589283895 BMS_LadegrenzeAntw_SOC_02 0;
BA_ "GenSigStartValue" SG_ 2589283895 BMS_LadegrenzeAntw_SOC_02 1022;
BA_ "GenSigSwitchedByIgnition" SG_ 2589283895 BMS_LadegrenzeAntw_SOC_02 0;
BA_ "Fehlerwert" SG_ 2589283895 BMS_LadegrenzeAntw_SOC_02 1023;
BA_ "GenSigSendType" SG_ 2589283895 BMS_LadegrenzeAntw_Zaehler_02 3;
BA_ "GenSigStartValue" SG_ 2589283895 BMS_LadegrenzeAntw_Zaehler_02 14;
BA_ "GenSigSwitchedByIgnition" SG_ 2589283895 BMS_LadegrenzeAntw_Zaehler_02 0;
BA_ "Fehlerwert" SG_ 2589283895 BMS_LadegrenzeAntw_Zaehler_02 15;
BA_ "GenSigSendType" SG_ 2589283895 BMS_NutzbarerSOC_02 0;
BA_ "GenSigStartValue" SG_ 2589283895 BMS_NutzbarerSOC_02 1022;
BA_ "GenSigSwitchedByIgnition" SG_ 2589283895 BMS_NutzbarerSOC_02 0;
BA_ "Fehlerwert" SG_ 2589283895 BMS_NutzbarerSOC_02 1023;
BA_ "GenSigSendType" SG_ 2589284070 BMS_ExtLadeleistung 0;
BA_ "GenSigStartValue" SG_ 2589284070 BMS_ExtLadeleistung 1022;
BA_ "GenSigSwitchedByIgnition" SG_ 2589284070 BMS_ExtLadeleistung 0;
BA_ "Fehlerwert" SG_ 2589284070 BMS_ExtLadeleistung 1023;
BA_ "GenSigSendType" SG_ 2589284007 BMS_48V_CALID_CVN_MUX 0;
BA_ "GenSigSwitchedByIgnition" SG_ 2589284007 BMS_48V_CALID_CVN_MUX 0;
BA_ "GenSigSwitchedByIgnition" SG_ 2589284007 BMS_48V_CALID_Index_01 0;
BA_ "GenSigSwitchedByIgnition" SG_ 2589284007 BMS_48V_CALID_Index_02 0;
BA_ "GenSigSwitchedByIgnition" SG_ 2589284007 BMS_48V_CALID_Index_03 0;
BA_ "GenSigSwitchedByIgnition" SG_ 2589284007 BMS_48V_CALID_Index_04 0;
BA_ "GenSigSwitchedByIgnition" SG_ 2589284007 BMS_48V_CALID_Index_05 0;
BA_ "GenSigSwitchedByIgnition" SG_ 2589284007 BMS_48V_CALID_Index_06 0;
BA_ "GenSigSwitchedByIgnition" SG_ 2589284007 BMS_48V_CALID_Index_07 0;
BA_ "GenSigSwitchedByIgnition" SG_ 2589284007 BMS_48V_CALID_Index_08 0;
BA_ "GenSigSwitchedByIgnition" SG_ 2589284007 BMS_48V_CALID_Index_09 0;
BA_ "GenSigSwitchedByIgnition" SG_ 2589284007 BMS_48V_CALID_Index_10 0;
BA_ "GenSigSwitchedByIgnition" SG_ 2589284007 BMS_48V_CALID_Index_11 0;
BA_ "GenSigSwitchedByIgnition" SG_ 2589284007 BMS_48V_CALID_Index_12 0;
BA_ "GenSigSwitchedByIgnition" SG_ 2589284007 BMS_48V_CALID_Index_13 0;
BA_ "GenSigSwitchedByIgnition" SG_ 2589284007 BMS_48V_CALID_Index_14 0;
BA_ "GenSigSwitchedByIgnition" SG_ 2589284007 BMS_48V_CALID_Index_15 0;
BA_ "GenSigSwitchedByIgnition" SG_ 2589284007 BMS_48V_CALID_Index_16 0;
BA_ "GenSigSwitchedByIgnition" SG_ 2589284007 BMS_48V_CVN_Byte_1 0;
BA_ "GenSigSwitchedByIgnition" SG_ 2589284007 BMS_48V_CVN_Byte_2 0;
BA_ "GenSigSwitchedByIgnition" SG_ 2589284007 BMS_48V_CVN_Byte_3 0;
BA_ "GenSigSwitchedByIgnition" SG_ 2589284007 BMS_48V_CVN_Byte_4 0;
BA_ "GenSigSendType" SG_ 2589284007 BMS_48V_CVN_VLD 0;
BA_ "GenSigSwitchedByIgnition" SG_ 2589284007 BMS_48V_CVN_VLD 0;
BA_ "GenSigSendType" SG_ 2589284008 BMS_48V_Komponentenfehler_01 0;
BA_ "GenSigSwitchedByIgnition" SG_ 2589284008 BMS_48V_Komponentenfehler_01 0;
BA_ "GenSigSendType" SG_ 2589284008 BMS_48V_Komponentenfehler_02 0;
BA_ "GenSigSwitchedByIgnition" SG_ 2589284008 BMS_48V_Komponentenfehler_02 0;
BA_ "GenSigSendType" SG_ 2589284008 BMS_48V_Komponentenfehler_03 0;
BA_ "GenSigSwitchedByIgnition" SG_ 2589284008 BMS_48V_Komponentenfehler_03 0;
BA_ "GenSigSendType" SG_ 2589284008 BMS_48V_Komponentenfehler_04 0;
BA_ "GenSigSwitchedByIgnition" SG_ 2589284008 BMS_48V_Komponentenfehler_04 0;
BA_ "GenSigSendType" SG_ 2589284008 BMS_48V_Komponentenfehler_05 0;
BA_ "GenSigSwitchedByIgnition" SG_ 2589284008 BMS_48V_Komponentenfehler_05 0;
BA_ "GenSigSendType" SG_ 2589284008 BMS_48V_Komponentenfehler_06 0;
BA_ "GenSigSwitchedByIgnition" SG_ 2589284008 BMS_48V_Komponentenfehler_06 0;
BA_ "GenSigSendType" SG_ 2589284008 BMS_48V_Komponentenfehler_07 0;
BA_ "GenSigSwitchedByIgnition" SG_ 2589284008 BMS_48V_Komponentenfehler_07 0;
BA_ "GenSigSendType" SG_ 2589284008 BMS_48V_Komponentenfehler_08 0;
BA_ "GenSigSwitchedByIgnition" SG_ 2589284008 BMS_48V_Komponentenfehler_08 0;
BA_ "GenSigSendType" SG_ 2589284008 BMS_48V_Komponentenfehler_09 0;
BA_ "GenSigSwitchedByIgnition" SG_ 2589284008 BMS_48V_Komponentenfehler_09 0;
BA_ "GenSigSendType" SG_ 2589284008 BMS_48V_Komponentenfehler_10 0;
BA_ "GenSigSwitchedByIgnition" SG_ 2589284008 BMS_48V_Komponentenfehler_10 0;
BA_ "GenSigSendType" SG_ 2589284008 BMS_48V_Komponentenfehler_11 0;
BA_ "GenSigSwitchedByIgnition" SG_ 2589284008 BMS_48V_Komponentenfehler_11 0;
BA_ "GenSigSendType" SG_ 2589284008 BMS_48V_Komponentenfehler_12 0;
BA_ "GenSigSwitchedByIgnition" SG_ 2589284008 BMS_48V_Komponentenfehler_12 0;
BA_ "GenSigSendType" SG_ 2589284008 BMS_48V_Komponentenfehler_13 0;
BA_ "GenSigSwitchedByIgnition" SG_ 2589284008 BMS_48V_Komponentenfehler_13 0;
BA_ "GenSigSendType" SG_ 2589284008 BMS_48V_Komponentenfehler_14 0;
BA_ "GenSigSwitchedByIgnition" SG_ 2589284008 BMS_48V_Komponentenfehler_14 0;
BA_ "GenSigSendType" SG_ 2589284008 BMS_48V_Komponentenfehler_15 0;
BA_ "GenSigSwitchedByIgnition" SG_ 2589284008 BMS_48V_Komponentenfehler_15 0;
BA_ "GenSigSendType" SG_ 2589284008 BMS_48V_Komponentenfehler_16 0;
BA_ "GenSigSwitchedByIgnition" SG_ 2589284008 BMS_48V_Komponentenfehler_16 0;
BA_ "GenSigSendType" SG_ 2589284008 BMS_48V_Komponentenfehler_17 0;
BA_ "GenSigSwitchedByIgnition" SG_ 2589284008 BMS_48V_Komponentenfehler_17 0;
BA_ "GenSigSendType" SG_ 2589284008 BMS_48V_Komponentenfehler_18 0;
BA_ "GenSigSwitchedByIgnition" SG_ 2589284008 BMS_48V_Komponentenfehler_18 0;
BA_ "GenSigSendType" SG_ 2589284008 BMS_48V_Komponentenfehler_19 0;
BA_ "GenSigSwitchedByIgnition" SG_ 2589284008 BMS_48V_Komponentenfehler_19 0;
BA_ "GenSigSendType" SG_ 2589284008 BMS_48V_Komponentenfehler_20 0;
BA_ "GenSigSwitchedByIgnition" SG_ 2589284008 BMS_48V_Komponentenfehler_20 0;
BA_ "GenSigSendType" SG_ 2589284008 BMS_48V_Komponentenfehler_21 0;
BA_ "GenSigSwitchedByIgnition" SG_ 2589284008 BMS_48V_Komponentenfehler_21 0;
BA_ "GenSigSendType" SG_ 2589284008 BMS_48V_Komponentenfehler_22 0;
BA_ "GenSigSwitchedByIgnition" SG_ 2589284008 BMS_48V_Komponentenfehler_22 0;
BA_ "GenSigSendType" SG_ 2589284008 BMS_48V_Komponentenfehler_23 0;
BA_ "GenSigSwitchedByIgnition" SG_ 2589284008 BMS_48V_Komponentenfehler_23 0;
BA_ "GenSigSendType" SG_ 2589284008 BMS_48V_Komponentenfehler_24 0;
BA_ "GenSigSwitchedByIgnition" SG_ 2589284008 BMS_48V_Komponentenfehler_24 0;
BA_ "GenSigSendType" SG_ 2589284008 BMS_48V_Komponentenfehler_25 0;
BA_ "GenSigSwitchedByIgnition" SG_ 2589284008 BMS_48V_Komponentenfehler_25 0;
BA_ "GenSigSendType" SG_ 2589284008 BMS_48V_Komponentenfehler_26 0;
BA_ "GenSigSwitchedByIgnition" SG_ 2589284008 BMS_48V_Komponentenfehler_26 0;
BA_ "GenSigSendType" SG_ 2589284008 BMS_48V_Komponentenfehler_27 0;
BA_ "GenSigSwitchedByIgnition" SG_ 2589284008 BMS_48V_Komponentenfehler_27 0;
BA_ "GenSigSendType" SG_ 2589284008 BMS_48V_Komponentenfehler_28 0;
BA_ "GenSigSwitchedByIgnition" SG_ 2589284008 BMS_48V_Komponentenfehler_28 0;
BA_ "GenSigSendType" SG_ 2589284008 BMS_48V_Komponentenfehler_29 0;
BA_ "GenSigSwitchedByIgnition" SG_ 2589284008 BMS_48V_Komponentenfehler_29 0;
BA_ "GenSigSendType" SG_ 2589284008 BMS_48V_Komponentenfehler_30 0;
BA_ "GenSigSwitchedByIgnition" SG_ 2589284008 BMS_48V_Komponentenfehler_30 0;
BA_ "GenSigSendType" SG_ 2589284008 BMS_48V_Komponentenfehler_31 0;
BA_ "GenSigSwitchedByIgnition" SG_ 2589284008 BMS_48V_Komponentenfehler_31 0;
BA_ "GenSigSendType" SG_ 2589284008 BMS_48V_Komponentenfehler_VLD 0;
BA_ "GenSigSwitchedByIgnition" SG_ 2589284008 BMS_48V_Komponentenfehler_VLD 0;
BA_ "GenSigSendType" SG_ 880 BMS_CMC_01_MUX 0;
BA_ "GenSigSwitchedByIgnition" SG_ 880 BMS_CMC_01_MUX 0;
BA_ "GenSigStartValue" SG_ 880 BMS_CMC_Zellspannung_001 4094;
BA_ "GenSigSwitchedByIgnition" SG_ 880 BMS_CMC_Zellspannung_001 0;
BA_ "Fehlerwert" SG_ 880 BMS_CMC_Zellspannung_001 4095;
BA_ "GenSigStartValue" SG_ 880 BMS_CMC_Zellspannung_002 4094;
BA_ "GenSigSwitchedByIgnition" SG_ 880 BMS_CMC_Zellspannung_002 0;
BA_ "Fehlerwert" SG_ 880 BMS_CMC_Zellspannung_002 4095;
BA_ "GenSigStartValue" SG_ 880 BMS_CMC_Zellspannung_003 4094;
BA_ "GenSigSwitchedByIgnition" SG_ 880 BMS_CMC_Zellspannung_003 0;
BA_ "Fehlerwert" SG_ 880 BMS_CMC_Zellspannung_003 4095;
BA_ "GenSigStartValue" SG_ 880 BMS_CMC_Zellspannung_004 4094;
BA_ "GenSigSwitchedByIgnition" SG_ 880 BMS_CMC_Zellspannung_004 0;
BA_ "Fehlerwert" SG_ 880 BMS_CMC_Zellspannung_004 4095;
BA_ "GenSigStartValue" SG_ 880 BMS_CMC_Zellspannung_005 4094;
BA_ "GenSigSwitchedByIgnition" SG_ 880 BMS_CMC_Zellspannung_005 0;
BA_ "Fehlerwert" SG_ 880 BMS_CMC_Zellspannung_005 4095;
BA_ "GenSigStartValue" SG_ 880 BMS_CMC_Zellspannung_006 4094;
BA_ "GenSigSwitchedByIgnition" SG_ 880 BMS_CMC_Zellspannung_006 0;
BA_ "Fehlerwert" SG_ 880 BMS_CMC_Zellspannung_006 4095;
BA_ "GenSigStartValue" SG_ 880 BMS_CMC_Zellspannung_007 4094;
BA_ "GenSigSwitchedByIgnition" SG_ 880 BMS_CMC_Zellspannung_007 0;
BA_ "Fehlerwert" SG_ 880 BMS_CMC_Zellspannung_007 4095;
BA_ "GenSigStartValue" SG_ 880 BMS_CMC_Zellspannung_008 4094;
BA_ "GenSigSwitchedByIgnition" SG_ 880 BMS_CMC_Zellspannung_008 0;
BA_ "Fehlerwert" SG_ 880 BMS_CMC_Zellspannung_008 4095;
BA_ "GenSigStartValue" SG_ 880 BMS_CMC_Zellspannung_009 4094;
BA_ "GenSigSwitchedByIgnition" SG_ 880 BMS_CMC_Zellspannung_009 0;
BA_ "Fehlerwert" SG_ 880 BMS_CMC_Zellspannung_009 4095;
BA_ "GenSigStartValue" SG_ 880 BMS_CMC_Zellspannung_010 4094;
BA_ "GenSigSwitchedByIgnition" SG_ 880 BMS_CMC_Zellspannung_010 0;
BA_ "Fehlerwert" SG_ 880 BMS_CMC_Zellspannung_010 4095;
BA_ "GenSigStartValue" SG_ 880 BMS_CMC_Zellspannung_011 4094;
BA_ "GenSigSwitchedByIgnition" SG_ 880 BMS_CMC_Zellspannung_011 0;
BA_ "Fehlerwert" SG_ 880 BMS_CMC_Zellspannung_011 4095;
BA_ "GenSigStartValue" SG_ 880 BMS_CMC_Zellspannung_012 4094;
BA_ "GenSigSwitchedByIgnition" SG_ 880 BMS_CMC_Zellspannung_012 0;
BA_ "Fehlerwert" SG_ 880 BMS_CMC_Zellspannung_012 4095;
BA_ "GenSigStartValue" SG_ 880 BMS_CMC_Zellspannung_013 4094;
BA_ "GenSigSwitchedByIgnition" SG_ 880 BMS_CMC_Zellspannung_013 0;
BA_ "Fehlerwert" SG_ 880 BMS_CMC_Zellspannung_013 4095;
BA_ "GenSigStartValue" SG_ 880 BMS_CMC_Zellspannung_014 4094;
BA_ "GenSigSwitchedByIgnition" SG_ 880 BMS_CMC_Zellspannung_014 0;
BA_ "Fehlerwert" SG_ 880 BMS_CMC_Zellspannung_014 4095;
BA_ "GenSigStartValue" SG_ 880 BMS_CMC_Zellspannung_015 4094;
BA_ "GenSigSwitchedByIgnition" SG_ 880 BMS_CMC_Zellspannung_015 0;
BA_ "Fehlerwert" SG_ 880 BMS_CMC_Zellspannung_015 4095;
BA_ "GenSigStartValue" SG_ 880 BMS_CMC_Zellspannung_016 4094;
BA_ "GenSigSwitchedByIgnition" SG_ 880 BMS_CMC_Zellspannung_016 0;
BA_ "Fehlerwert" SG_ 880 BMS_CMC_Zellspannung_016 4095;
BA_ "GenSigStartValue" SG_ 880 BMS_CMC_Zellspannung_017 4094;
BA_ "GenSigSwitchedByIgnition" SG_ 880 BMS_CMC_Zellspannung_017 0;
BA_ "Fehlerwert" SG_ 880 BMS_CMC_Zellspannung_017 4095;
BA_ "GenSigStartValue" SG_ 880 BMS_CMC_Zellspannung_018 4094;
BA_ "GenSigSwitchedByIgnition" SG_ 880 BMS_CMC_Zellspannung_018 0;
BA_ "Fehlerwert" SG_ 880 BMS_CMC_Zellspannung_018 4095;
BA_ "GenSigStartValue" SG_ 880 BMS_CMC_Zellspannung_019 4094;
BA_ "GenSigSwitchedByIgnition" SG_ 880 BMS_CMC_Zellspannung_019 0;
BA_ "Fehlerwert" SG_ 880 BMS_CMC_Zellspannung_019 4095;
BA_ "GenSigStartValue" SG_ 880 BMS_CMC_Zellspannung_020 4094;
BA_ "GenSigSwitchedByIgnition" SG_ 880 BMS_CMC_Zellspannung_020 0;
BA_ "Fehlerwert" SG_ 880 BMS_CMC_Zellspannung_020 4095;
BA_ "GenSigStartValue" SG_ 880 BMS_CMC_Zellspannung_021 4094;
BA_ "GenSigSwitchedByIgnition" SG_ 880 BMS_CMC_Zellspannung_021 0;
BA_ "Fehlerwert" SG_ 880 BMS_CMC_Zellspannung_021 4095;
BA_ "GenSigStartValue" SG_ 880 BMS_CMC_Zellspannung_022 4094;
BA_ "GenSigSwitchedByIgnition" SG_ 880 BMS_CMC_Zellspannung_022 0;
BA_ "Fehlerwert" SG_ 880 BMS_CMC_Zellspannung_022 4095;
BA_ "GenSigStartValue" SG_ 880 BMS_CMC_Zellspannung_023 4094;
BA_ "GenSigSwitchedByIgnition" SG_ 880 BMS_CMC_Zellspannung_023 0;
BA_ "Fehlerwert" SG_ 880 BMS_CMC_Zellspannung_023 4095;
BA_ "GenSigStartValue" SG_ 880 BMS_CMC_Zellspannung_024 4094;
BA_ "GenSigSwitchedByIgnition" SG_ 880 BMS_CMC_Zellspannung_024 0;
BA_ "Fehlerwert" SG_ 880 BMS_CMC_Zellspannung_024 4095;
BA_ "GenSigStartValue" SG_ 880 BMS_CMC_Zellspannung_025 4094;
BA_ "GenSigSwitchedByIgnition" SG_ 880 BMS_CMC_Zellspannung_025 0;
BA_ "Fehlerwert" SG_ 880 BMS_CMC_Zellspannung_025 4095;
BA_ "GenSigStartValue" SG_ 880 BMS_CMC_Zellspannung_026 4094;
BA_ "GenSigSwitchedByIgnition" SG_ 880 BMS_CMC_Zellspannung_026 0;
BA_ "Fehlerwert" SG_ 880 BMS_CMC_Zellspannung_026 4095;
BA_ "GenSigStartValue" SG_ 880 BMS_CMC_Zellspannung_027 4094;
BA_ "GenSigSwitchedByIgnition" SG_ 880 BMS_CMC_Zellspannung_027 0;
BA_ "Fehlerwert" SG_ 880 BMS_CMC_Zellspannung_027 4095;
BA_ "GenSigStartValue" SG_ 880 BMS_CMC_Zellspannung_028 4094;
BA_ "GenSigSwitchedByIgnition" SG_ 880 BMS_CMC_Zellspannung_028 0;
BA_ "Fehlerwert" SG_ 880 BMS_CMC_Zellspannung_028 4095;
BA_ "GenSigStartValue" SG_ 880 BMS_CMC_Zellspannung_029 4094;
BA_ "GenSigSwitchedByIgnition" SG_ 880 BMS_CMC_Zellspannung_029 0;
BA_ "Fehlerwert" SG_ 880 BMS_CMC_Zellspannung_029 4095;
BA_ "GenSigStartValue" SG_ 880 BMS_CMC_Zellspannung_030 4094;
BA_ "GenSigSwitchedByIgnition" SG_ 880 BMS_CMC_Zellspannung_030 0;
BA_ "Fehlerwert" SG_ 880 BMS_CMC_Zellspannung_030 4095;
BA_ "GenSigStartValue" SG_ 880 BMS_CMC_Zellspannung_031 4094;
BA_ "GenSigSwitchedByIgnition" SG_ 880 BMS_CMC_Zellspannung_031 0;
BA_ "Fehlerwert" SG_ 880 BMS_CMC_Zellspannung_031 4095;
BA_ "GenSigStartValue" SG_ 880 BMS_CMC_Zellspannung_032 4094;
BA_ "GenSigSwitchedByIgnition" SG_ 880 BMS_CMC_Zellspannung_032 0;
BA_ "Fehlerwert" SG_ 880 BMS_CMC_Zellspannung_032 4095;
BA_ "GenSigStartValue" SG_ 880 BMS_CMC_Zellspannung_033 4094;
BA_ "GenSigSwitchedByIgnition" SG_ 880 BMS_CMC_Zellspannung_033 0;
BA_ "Fehlerwert" SG_ 880 BMS_CMC_Zellspannung_033 4095;
BA_ "GenSigStartValue" SG_ 880 BMS_CMC_Zellspannung_034 4094;
BA_ "GenSigSwitchedByIgnition" SG_ 880 BMS_CMC_Zellspannung_034 0;
BA_ "Fehlerwert" SG_ 880 BMS_CMC_Zellspannung_034 4095;
BA_ "GenSigStartValue" SG_ 880 BMS_CMC_Zellspannung_035 4094;
BA_ "GenSigSwitchedByIgnition" SG_ 880 BMS_CMC_Zellspannung_035 0;
BA_ "Fehlerwert" SG_ 880 BMS_CMC_Zellspannung_035 4095;
BA_ "GenSigStartValue" SG_ 880 BMS_CMC_Zellspannung_036 4094;
BA_ "GenSigSwitchedByIgnition" SG_ 880 BMS_CMC_Zellspannung_036 0;
BA_ "Fehlerwert" SG_ 880 BMS_CMC_Zellspannung_036 4095;
BA_ "GenSigStartValue" SG_ 880 BMS_CMC_Zellspannung_037 4094;
BA_ "GenSigSwitchedByIgnition" SG_ 880 BMS_CMC_Zellspannung_037 0;
BA_ "Fehlerwert" SG_ 880 BMS_CMC_Zellspannung_037 4095;
BA_ "GenSigStartValue" SG_ 880 BMS_CMC_Zellspannung_038 4094;
BA_ "GenSigSwitchedByIgnition" SG_ 880 BMS_CMC_Zellspannung_038 0;
BA_ "Fehlerwert" SG_ 880 BMS_CMC_Zellspannung_038 4095;
BA_ "GenSigStartValue" SG_ 880 BMS_CMC_Zellspannung_039 4094;
BA_ "GenSigSwitchedByIgnition" SG_ 880 BMS_CMC_Zellspannung_039 0;
BA_ "Fehlerwert" SG_ 880 BMS_CMC_Zellspannung_039 4095;
BA_ "GenSigStartValue" SG_ 880 BMS_CMC_Zellspannung_040 4094;
BA_ "GenSigSwitchedByIgnition" SG_ 880 BMS_CMC_Zellspannung_040 0;
BA_ "Fehlerwert" SG_ 880 BMS_CMC_Zellspannung_040 4095;
BA_ "GenSigStartValue" SG_ 880 BMS_CMC_Zellspannung_041 4094;
BA_ "GenSigSwitchedByIgnition" SG_ 880 BMS_CMC_Zellspannung_041 0;
BA_ "Fehlerwert" SG_ 880 BMS_CMC_Zellspannung_041 4095;
BA_ "GenSigStartValue" SG_ 880 BMS_CMC_Zellspannung_042 4094;
BA_ "GenSigSwitchedByIgnition" SG_ 880 BMS_CMC_Zellspannung_042 0;
BA_ "Fehlerwert" SG_ 880 BMS_CMC_Zellspannung_042 4095;
BA_ "GenSigStartValue" SG_ 880 BMS_CMC_Zellspannung_043 4094;
BA_ "GenSigSwitchedByIgnition" SG_ 880 BMS_CMC_Zellspannung_043 0;
BA_ "Fehlerwert" SG_ 880 BMS_CMC_Zellspannung_043 4095;
BA_ "GenSigStartValue" SG_ 880 BMS_CMC_Zellspannung_044 4094;
BA_ "GenSigSwitchedByIgnition" SG_ 880 BMS_CMC_Zellspannung_044 0;
BA_ "Fehlerwert" SG_ 880 BMS_CMC_Zellspannung_044 4095;
BA_ "GenSigStartValue" SG_ 880 BMS_CMC_Zellspannung_045 4094;
BA_ "GenSigSwitchedByIgnition" SG_ 880 BMS_CMC_Zellspannung_045 0;
BA_ "Fehlerwert" SG_ 880 BMS_CMC_Zellspannung_045 4095;
BA_ "GenSigStartValue" SG_ 880 BMS_CMC_Zellspannung_046 4094;
BA_ "GenSigSwitchedByIgnition" SG_ 880 BMS_CMC_Zellspannung_046 0;
BA_ "Fehlerwert" SG_ 880 BMS_CMC_Zellspannung_046 4095;
BA_ "GenSigStartValue" SG_ 880 BMS_CMC_Zellspannung_047 4094;
BA_ "GenSigSwitchedByIgnition" SG_ 880 BMS_CMC_Zellspannung_047 0;
BA_ "Fehlerwert" SG_ 880 BMS_CMC_Zellspannung_047 4095;
BA_ "GenSigStartValue" SG_ 880 BMS_CMC_Zellspannung_048 4094;
BA_ "GenSigSwitchedByIgnition" SG_ 880 BMS_CMC_Zellspannung_048 0;
BA_ "Fehlerwert" SG_ 880 BMS_CMC_Zellspannung_048 4095;
BA_ "GenSigStartValue" SG_ 880 BMS_CMC_Zellspannung_049 4094;
BA_ "GenSigSwitchedByIgnition" SG_ 880 BMS_CMC_Zellspannung_049 0;
BA_ "Fehlerwert" SG_ 880 BMS_CMC_Zellspannung_049 4095;
BA_ "GenSigStartValue" SG_ 880 BMS_CMC_Zellspannung_050 4094;
BA_ "GenSigSwitchedByIgnition" SG_ 880 BMS_CMC_Zellspannung_050 0;
BA_ "Fehlerwert" SG_ 880 BMS_CMC_Zellspannung_050 4095;
BA_ "GenSigStartValue" SG_ 880 BMS_CMC_Zellspannung_051 4094;
BA_ "GenSigSwitchedByIgnition" SG_ 880 BMS_CMC_Zellspannung_051 0;
BA_ "Fehlerwert" SG_ 880 BMS_CMC_Zellspannung_051 4095;
BA_ "GenSigStartValue" SG_ 880 BMS_CMC_Zellspannung_052 4094;
BA_ "GenSigSwitchedByIgnition" SG_ 880 BMS_CMC_Zellspannung_052 0;
BA_ "Fehlerwert" SG_ 880 BMS_CMC_Zellspannung_052 4095;
BA_ "GenSigStartValue" SG_ 880 BMS_CMC_Zellspannung_053 4094;
BA_ "GenSigSwitchedByIgnition" SG_ 880 BMS_CMC_Zellspannung_053 0;
BA_ "Fehlerwert" SG_ 880 BMS_CMC_Zellspannung_053 4095;
BA_ "GenSigStartValue" SG_ 880 BMS_CMC_Zellspannung_054 4094;
BA_ "GenSigSwitchedByIgnition" SG_ 880 BMS_CMC_Zellspannung_054 0;
BA_ "Fehlerwert" SG_ 880 BMS_CMC_Zellspannung_054 4095;
BA_ "GenSigStartValue" SG_ 880 BMS_CMC_Zellspannung_055 4094;
BA_ "GenSigSwitchedByIgnition" SG_ 880 BMS_CMC_Zellspannung_055 0;
BA_ "Fehlerwert" SG_ 880 BMS_CMC_Zellspannung_055 4095;
BA_ "GenSigStartValue" SG_ 880 BMS_CMC_Zellspannung_056 4094;
BA_ "GenSigSwitchedByIgnition" SG_ 880 BMS_CMC_Zellspannung_056 0;
BA_ "Fehlerwert" SG_ 880 BMS_CMC_Zellspannung_056 4095;
BA_ "GenSigStartValue" SG_ 880 BMS_CMC_Zellspannung_057 4094;
BA_ "GenSigSwitchedByIgnition" SG_ 880 BMS_CMC_Zellspannung_057 0;
BA_ "Fehlerwert" SG_ 880 BMS_CMC_Zellspannung_057 4095;
BA_ "GenSigStartValue" SG_ 880 BMS_CMC_Zellspannung_058 4094;
BA_ "GenSigSwitchedByIgnition" SG_ 880 BMS_CMC_Zellspannung_058 0;
BA_ "Fehlerwert" SG_ 880 BMS_CMC_Zellspannung_058 4095;
BA_ "GenSigStartValue" SG_ 880 BMS_CMC_Zellspannung_059 4094;
BA_ "GenSigSwitchedByIgnition" SG_ 880 BMS_CMC_Zellspannung_059 0;
BA_ "Fehlerwert" SG_ 880 BMS_CMC_Zellspannung_059 4095;
BA_ "GenSigStartValue" SG_ 880 BMS_CMC_Zellspannung_060 4094;
BA_ "GenSigSwitchedByIgnition" SG_ 880 BMS_CMC_Zellspannung_060 0;
BA_ "Fehlerwert" SG_ 880 BMS_CMC_Zellspannung_060 4095;
BA_ "GenSigStartValue" SG_ 880 BMS_CMC_Zellspannung_061 4094;
BA_ "GenSigSwitchedByIgnition" SG_ 880 BMS_CMC_Zellspannung_061 0;
BA_ "Fehlerwert" SG_ 880 BMS_CMC_Zellspannung_061 4095;
BA_ "GenSigStartValue" SG_ 880 BMS_CMC_Zellspannung_062 4094;
BA_ "GenSigSwitchedByIgnition" SG_ 880 BMS_CMC_Zellspannung_062 0;
BA_ "Fehlerwert" SG_ 880 BMS_CMC_Zellspannung_062 4095;
BA_ "GenSigStartValue" SG_ 880 BMS_CMC_Zellspannung_063 4094;
BA_ "GenSigSwitchedByIgnition" SG_ 880 BMS_CMC_Zellspannung_063 0;
BA_ "Fehlerwert" SG_ 880 BMS_CMC_Zellspannung_063 4095;
BA_ "GenSigStartValue" SG_ 880 BMS_CMC_Zellspannung_064 4094;
BA_ "GenSigSwitchedByIgnition" SG_ 880 BMS_CMC_Zellspannung_064 0;
BA_ "Fehlerwert" SG_ 880 BMS_CMC_Zellspannung_064 4095;
BA_ "GenSigStartValue" SG_ 880 BMS_CMC_Zellspannung_065 4094;
BA_ "GenSigSwitchedByIgnition" SG_ 880 BMS_CMC_Zellspannung_065 0;
BA_ "Fehlerwert" SG_ 880 BMS_CMC_Zellspannung_065 4095;
BA_ "GenSigStartValue" SG_ 880 BMS_CMC_Zellspannung_066 4094;
BA_ "GenSigSwitchedByIgnition" SG_ 880 BMS_CMC_Zellspannung_066 0;
BA_ "Fehlerwert" SG_ 880 BMS_CMC_Zellspannung_066 4095;
BA_ "GenSigStartValue" SG_ 880 BMS_CMC_Zellspannung_067 4094;
BA_ "GenSigSwitchedByIgnition" SG_ 880 BMS_CMC_Zellspannung_067 0;
BA_ "Fehlerwert" SG_ 880 BMS_CMC_Zellspannung_067 4095;
BA_ "GenSigStartValue" SG_ 880 BMS_CMC_Zellspannung_068 4094;
BA_ "GenSigSwitchedByIgnition" SG_ 880 BMS_CMC_Zellspannung_068 0;
BA_ "Fehlerwert" SG_ 880 BMS_CMC_Zellspannung_068 4095;
BA_ "GenSigStartValue" SG_ 880 BMS_CMC_Zellspannung_069 4094;
BA_ "GenSigSwitchedByIgnition" SG_ 880 BMS_CMC_Zellspannung_069 0;
BA_ "Fehlerwert" SG_ 880 BMS_CMC_Zellspannung_069 4095;
BA_ "GenSigStartValue" SG_ 880 BMS_CMC_Zellspannung_070 4094;
BA_ "GenSigSwitchedByIgnition" SG_ 880 BMS_CMC_Zellspannung_070 0;
BA_ "Fehlerwert" SG_ 880 BMS_CMC_Zellspannung_070 4095;
BA_ "GenSigStartValue" SG_ 880 BMS_CMC_Zellspannung_071 4094;
BA_ "GenSigSwitchedByIgnition" SG_ 880 BMS_CMC_Zellspannung_071 0;
BA_ "Fehlerwert" SG_ 880 BMS_CMC_Zellspannung_071 4095;
BA_ "GenSigStartValue" SG_ 880 BMS_CMC_Zellspannung_072 4094;
BA_ "GenSigSwitchedByIgnition" SG_ 880 BMS_CMC_Zellspannung_072 0;
BA_ "Fehlerwert" SG_ 880 BMS_CMC_Zellspannung_072 4095;
BA_ "GenSigStartValue" SG_ 880 BMS_CMC_Zellspannung_073 4094;
BA_ "GenSigSwitchedByIgnition" SG_ 880 BMS_CMC_Zellspannung_073 0;
BA_ "Fehlerwert" SG_ 880 BMS_CMC_Zellspannung_073 4095;
BA_ "GenSigStartValue" SG_ 880 BMS_CMC_Zellspannung_074 4094;
BA_ "GenSigSwitchedByIgnition" SG_ 880 BMS_CMC_Zellspannung_074 0;
BA_ "Fehlerwert" SG_ 880 BMS_CMC_Zellspannung_074 4095;
BA_ "GenSigStartValue" SG_ 880 BMS_CMC_Zellspannung_075 4094;
BA_ "GenSigSwitchedByIgnition" SG_ 880 BMS_CMC_Zellspannung_075 0;
BA_ "Fehlerwert" SG_ 880 BMS_CMC_Zellspannung_075 4095;
BA_ "GenSigStartValue" SG_ 880 BMS_CMC_Zellspannung_076 4094;
BA_ "GenSigSwitchedByIgnition" SG_ 880 BMS_CMC_Zellspannung_076 0;
BA_ "Fehlerwert" SG_ 880 BMS_CMC_Zellspannung_076 4095;
BA_ "GenSigStartValue" SG_ 880 BMS_CMC_Zellspannung_077 4094;
BA_ "GenSigSwitchedByIgnition" SG_ 880 BMS_CMC_Zellspannung_077 0;
BA_ "Fehlerwert" SG_ 880 BMS_CMC_Zellspannung_077 4095;
BA_ "GenSigStartValue" SG_ 880 BMS_CMC_Zellspannung_078 4094;
BA_ "GenSigSwitchedByIgnition" SG_ 880 BMS_CMC_Zellspannung_078 0;
BA_ "Fehlerwert" SG_ 880 BMS_CMC_Zellspannung_078 4095;
BA_ "GenSigStartValue" SG_ 880 BMS_CMC_Zellspannung_079 4094;
BA_ "GenSigSwitchedByIgnition" SG_ 880 BMS_CMC_Zellspannung_079 0;
BA_ "Fehlerwert" SG_ 880 BMS_CMC_Zellspannung_079 4095;
BA_ "GenSigStartValue" SG_ 880 BMS_CMC_Zellspannung_080 4094;
BA_ "GenSigSwitchedByIgnition" SG_ 880 BMS_CMC_Zellspannung_080 0;
BA_ "Fehlerwert" SG_ 880 BMS_CMC_Zellspannung_080 4095;
